VERSION ""

NS_ :

BS_:

BU_: CH DIPF DIPR ETH FC HVI HVS PARTY SDCV VEH VIRT

BO_ 1304 VCRIGHT_alertCleared: 2 VEH
 SG_ VCRIGHT_alertClearedID : 0|9@1+ (1,0) [0|324] ""  X

BO_ 1924 DBG_xcpPMSCommand: 8 VEH
 SG_ DBG_xcpPMSCommand : 7|64@0+ (1,0) [0|18446744073709551615] ""  pms

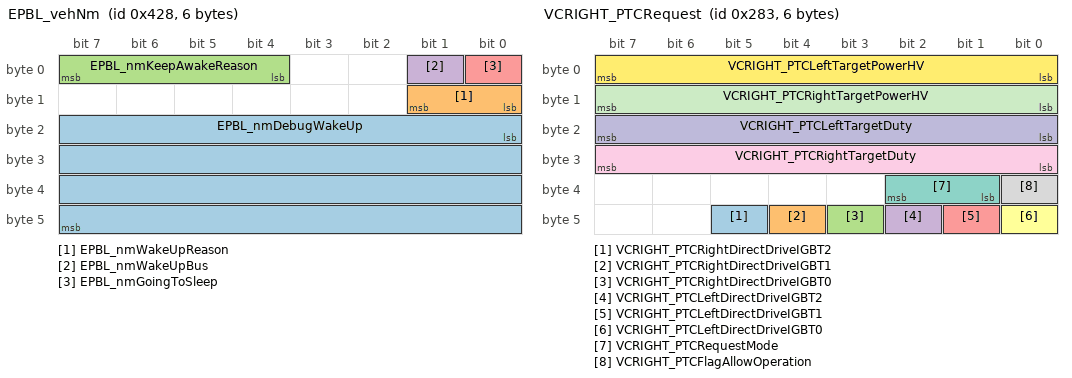
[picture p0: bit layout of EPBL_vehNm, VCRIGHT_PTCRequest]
BO_ 1064 EPBL_vehNm: 6 VEH
 SG_ EPBL_nmDebugWakeUp : 16|32@1+ (1,0) [0|4294967295] ""  gtw
 SG_ EPBL_nmWakeUpReason : 8|2@1+ (1,0) [0|3] ""  gtw
 SG_ EPBL_nmKeepAwakeReason : 4|4@1+ (1,0) [0|15] ""  gtw
 SG_ EPBL_nmWakeUpBus : 1|1@1+ (1,0) [0|1] ""  X
 SG_ EPBL_nmGoingToSleep : 0|1@1+ (1,0) [0|1] ""  X

BO_ 1579 UDS_ccRequest: 8 VEH
 SG_ UDS_ccRequestData : 7|64@0+ (1,0) [0|18446744073709551615] ""  bms

BO_ 627 UI_vehicleControl: 8 VEH
 SG_ UI_rearWindowLockout : 63|1@1+ (1,0) [0|1] ""  vcleft
 SG_ UI_driveStateRequest : 62|1@1+ (1,0) [0|1] ""  vcfront
 SG_ UI_honkHorn : 61|1@1+ (1,0) [0|1] ""  vcfront
 SG_ UI_domeLightSwitch : 59|2@1+ (1,0) [0|2] ""  vcleft
 SG_ UI_wiperRequest : 56|3@1+ (1,0) [0|6] ""  app
 SG_ UI_remoteClosureRequest : 54|2@1+ (1,0) [0|3] ""  vcsec
 SG_ UI_mirrorDipOnReverse : 53|1@1+ (1,0) [0|1] ""  vcleft
 SG_ UI_autoFoldMirrorsOn : 52|1@1+ (1,0) [0|1] ""  vcleft
 SG_ UI_rearRightSeatHeatReq : 50|2@1+ (1,0) [0|3] ""  vcright
 SG_ UI_rearCenterSeatHeatReq : 48|2@1+ (1,0) [0|3] ""  vcright
 SG_ UI_rearLeftSeatHeatReq : 46|2@1+ (1,0) [0|3] ""  vcright
 SG_ UI_frontRightSeatHeatReq : 44|2@1+ (1,0) [0|3] ""  vcright
 SG_ UI_frontLeftSeatHeatReq : 42|2@1+ (1,0) [0|3] ""  vcleft
 SG_ UI_autoHighBeamEnabled : 41|1@1+ (1,0) [0|1] ""  vcfront
 SG_ UI_ambientLightingEnabled : 40|1@1+ (1,0) [0|1] ""  vcfront
 SG_ UI_displayBrightnessLevel : 32|8@1+ (0.5,0) [0|127] "%"  vcfront
 SG_ UI_powerOff : 31|1@1+ (1,0) [0|1] ""  vcfront
 SG_ UI_seeYouHomeLightingOn : 30|1@1+ (1,0) [0|1] ""  vcfront
 SG_ UI_remoteStartRequest : 27|3@1+ (1,0) [0|4] ""  vcsec
 SG_ UI_mirrorHeatRequest : 26|1@1+ (1,0) [0|1] ""  vcleft
 SG_ UI_mirrorFoldRequest : 24|2@1+ (1,0) [0|3] ""  vcleft
 SG_ UI_rearFogSwitch : 23|1@1+ (1,0) [0|1] ""  vcleft
 SG_ UI_stop12vSupport : 22|1@1+ (1,0) [0|1] ""  vcfront
 SG_ UI_intrusionSensorOn : 21|1@1+ (1,0) [0|1] ""  vcfront
 SG_ UI_alarmEnabled : 20|1@1+ (1,0) [0|1] ""  vcsec
 SG_ UI_lockRequest : 17|3@1+ (1,0) [0|7] ""  vcsec
 SG_ UI_childDoorLockOn : 16|1@1+ (1,0) [0|1] ""  vcleft
 SG_ UI_globalUnlockOn : 15|1@1+ (1,0) [0|1] ""  X
 SG_ UI_unlockOnPark : 14|1@1+ (1,0) [0|1] ""  vcsec
 SG_ UI_walkAwayLock : 13|1@1+ (1,0) [0|1] ""  vcsec
 SG_ UI_walkUpUnlock : 12|1@1+ (1,0) [0|1] ""  vcsec
 SG_ UI_steeringButtonMode : 9|3@1+ (1,0) [0|5] ""  vcfront
 SG_ UI_steeringBacklightEnabled : 8|1@1+ (1,0) [0|1] ""  vcleft
 SG_ UI_wiperMode : 6|2@1+ (1,0) [0|3] ""  vcfront
 SG_ UI_frunkRequest : 5|1@1+ (1,0) [0|1] ""  vcfront
 SG_ UI_summonActive : 4|1@1+ (1,0) [0|1] ""  vcleft
 SG_ UI_frontFogSwitch : 3|1@1+ (1,0) [0|1] ""  vcfront
 SG_ UI_accessoryPowerRequest : 0|1@1+ (1,0) [0|1] ""  vcfront

BO_ 1960 EPBR_debugOutput: 8 VEH
 SG_ EPBR_filteredCurrentCalSP m1 : 52|12@1+ (0.01,0) [0|40.95] "A"  X
 SG_ EPBR_pid_error m1 : 40|12@1+ (0.016997132,-37.55274262) [-37.55274|32.05051] "A"  X
 SG_ EPBR_currentVariance m0 : 40|14@1- (3.0517578125e-05,0) [-0.25|0.24997] "A"  X
 SG_ EPBR_atEndStop m0 : 37|1@1+ (1,0) [0|1] ""  X
 SG_ EPBR_learnedBrakeHWType m0 : 35|2@1+ (1,0) [0|2] ""  X
 SG_ EPBR_diBrakeActive m0 : 34|1@1+ (1,0) [0|1] ""  X
 SG_ EPBR_diStandStill m0 : 33|1@1+ (1,0) [0|1] ""  X
 SG_ EPBR_nFault m0 : 32|1@1+ (1,0) [0|1] ""  X
 SG_ EPBR_brakeDiscWipeAccumul m2 : 32|28@1+ (1,0) [0|268435455] ""  X
 SG_ EPBR_ramp m1 : 32|8@1+ (0.392157,0) [0|100.00004] "%"  X
 SG_ EPBR_lockoutCommandHVC m2 : 31|1@1+ (1,0) [0|1] ""  gtw
 SG_ EPBR_lockoutOutputHVC m2 : 30|1@1+ (1,0) [0|1] ""  gtw
 SG_ EPBR_caliperState m0 : 29|3@1+ (1,0) [0|5] ""  X
 SG_ EPBR_lockoutCmdContactor m2 : 29|1@1+ (1,0) [0|1] ""  gtw
 SG_ EPBR_lockoutOutContactor m2 : 28|1@1+ (1,0) [0|1] ""  gtw
 SG_ EPBR_pid_duty m1 : 22|10@1- (0.2,0) [-102.4|102.2] "%"  X
 SG_ EPBR_pvFilt m0 : 20|9@1+ (0.043549408784,0) [0|22.25375] "V"  X
 SG_ EPBR_filteredCurrentPeak m2 : 16|12@1+ (0.01,0) [0|40.95] "A"  gtw
 SG_ EPBR_pid_uI m1 : 12|10@1- (0.2,0) [-102.4|102.2] "A"  X
 SG_ EPBR_nvFilt m0 : 11|9@1+ (0.043549408784,0) [0|22.25375] "V"  X
 SG_ EPBR_currentOffset m2 : 2|12@1+ (0.016997132,-37.55274262) [-37.55274|32.05051] "A"  X
 SG_ EPBR_pid_uP m1 : 2|10@1- (0.2,0) [-102.4|102.2] "A"  X
 SG_ EPBR_12VFilt_SW m0 : 2|9@1+ (0.043549408784,0) [0|22.25375] "V"  X
 SG_ EPBR_debugOutput M : 0|2@1+ (1,0) [0|2] ""  X

BO_ 1310 FC_info: 8 VEH
 SG_ FC_partNumChar14 m26 : 56|1@1+ (1,0) [0|1] ""  gtw
 SG_ FC_partNumChar07 m25 : 56|1@1+ (1,0) [0|1] ""  gtw
 SG_ FC_partNumChar20 m27 : 48|1@1+ (1,0) [0|1] ""  gtw
 SG_ FC_infoComponentID m10 : 48|16@1+ (1,0) [0|65535] ""  gtw
 SG_ FC_infoSubUsageID m11 : 48|16@1+ (1,0) [0|65535] ""  gtw
 SG_ FC_partNumChar13 m26 : 48|1@1+ (1,0) [0|1] ""  gtw
 SG_ FC_partNumChar06 m25 : 48|1@1+ (1,0) [0|1] ""  gtw
 SG_ FC_infoHardwareRevision m19 : 40|8@1+ (1,0) [0|255] ""  gtw
 SG_ FC_partNumChar05 m25 : 40|1@1+ (1,0) [0|1] ""  gtw
 SG_ FC_partNumChar19 m27 : 40|1@1+ (1,0) [0|1] ""  gtw
 SG_ FC_partNumChar12 m26 : 40|1@1+ (1,0) [0|1] ""  gtw
 SG_ FC_infoVariantCRC m22 : 32|32@1+ (1,0) [0|4294967295] ""  gtw
 SG_ FC_partNumChar11 m26 : 32|1@1+ (1,0) [0|1] ""  gtw
 SG_ FC_infoBootCRC m15 : 32|32@1+ (1,0) [0|4294967295] ""  gtw
 SG_ FC_partNumChar04 m25 : 32|1@1+ (1,0) [0|1] ""  gtw
 SG_ FC_infoUsageID m11 : 32|16@1+ (1,0) [0|65535] ""  gtw
 SG_ FC_partNumChar18 m27 : 32|1@1+ (1,0) [0|1] ""  gtw
 SG_ FC_infoHardwareID m10 : 32|16@1+ (1,0) [0|65535] ""  gtw
 SG_ FC_infoMaturity m19 : 32|8@1+ (1,0) [0|255] ""  gtw
 SG_ FC_infoApplicationCRC m13 : 32|32@1+ (1,0) [0|4294967295] ""  gtw
 SG_ FC_partNumChar03 m25 : 24|1@1+ (1,0) [0|1] ""  gtw
 SG_ FC_partNumChar17 m27 : 24|1@1+ (1,0) [0|1] ""  gtw
 SG_ FC_partNumChar10 m26 : 24|1@1+ (1,0) [0|1] ""  gtw
 SG_ FC_infoCPLDVersionMinor m16 : 24|8@1+ (1,0) [0|255] ""  gtw
 SG_ FC_infoAssemblyID m11 : 24|8@1+ (1,0) [0|255] ""  gtw
 SG_ FC_infoBranchOrigin m19 : 24|8@1+ (1,0) [0|255] ""  gtw
 SG_ FC_partNumChar02 m25 : 16|1@1+ (1,0) [0|1] ""  gtw
 SG_ FC_infoMajorVersion m19 : 16|8@1+ (1,0) [0|255] ""  gtw
 SG_ FC_infoBuildConfigID m10 : 16|8@1+ (1,0) [0|255] ""  gtw
 SG_ FC_partNumChar09 m26 : 16|1@1+ (1,0) [0|1] ""  gtw
 SG_ FC_partNumChar16 m27 : 16|1@1+ (1,0) [0|1] ""  gtw
 SG_ FC_infoPcbaID m11 : 16|8@1+ (1,0) [0|255] ""  gtw
 SG_ FC_infoCPLDVersionMajor m16 : 16|8@1+ (1,0) [0|255] ""  gtw
 SG_ FC_partNumChar08 m26 : 8|1@1+ (1,0) [0|1] ""  gtw
 SG_ FC_infoBuildType m10 : 8|3@1+ (1,0) [0|4] ""  gtw
 SG_ FC_infoAppGitHashBytes m17 : 8|56@1+ (1,0) [0|72057594037927935] ""  gtw
 SG_ FC_infoBootGitHashBytes m18 : 8|56@1+ (1,0) [0|72057594037927935] ""  gtw
 SG_ FC_infoPlatformType m19 : 8|8@1+ (1,0) [0|255] ""  gtw
 SG_ FC_infoBootSvnRev m14 : 8|24@1+ (1,0) [0|16777215] ""  gtw
 SG_ FC_partNumChar01 m25 : 8|1@1+ (1,0) [0|1] ""  gtw
 SG_ FC_partNumChar15 m27 : 8|1@1+ (1,0) [0|1] ""  gtw
 SG_ FC_infoBootUdsProtoVersion m20 : 8|8@1+ (1,0) [0|255] ""  gtw
 SG_ FC_infoIndex M : 0|8@1+ (1,0) [0|255] ""  dbg

BO_ 1910 DBG_xcpDISCommand: 8 VEH
 SG_ DBG_xcpDISCommand : 7|64@0+ (1,0) [0|18446744073709551615] ""  dis

BO_ 643 VCRIGHT_PTCRequest: 6 VEH
 SG_ VCRIGHT_PTCRightDirectDriveIGBT2 : 45|1@1+ (1,0) [0|1] ""  ptc
 SG_ VCRIGHT_PTCRightDirectDriveIGBT1 : 44|1@1+ (1,0) [0|1] ""  ptc
 SG_ VCRIGHT_PTCRightDirectDriveIGBT0 : 43|1@1+ (1,0) [0|1] ""  ptc
 SG_ VCRIGHT_PTCLeftDirectDriveIGBT2 : 42|1@1+ (1,0) [0|1] ""  ptc
 SG_ VCRIGHT_PTCLeftDirectDriveIGBT1 : 41|1@1+ (1,0) [0|1] ""  ptc
 SG_ VCRIGHT_PTCLeftDirectDriveIGBT0 : 40|1@1+ (1,0) [0|1] ""  ptc
 SG_ VCRIGHT_PTCRequestMode : 33|2@1+ (1,0) [0|2] ""  ptc
 SG_ VCRIGHT_PTCFlagAllowOperation : 32|1@1+ (1,0) [0|1] ""  ptc
 SG_ VCRIGHT_PTCRightTargetDuty : 24|8@1+ (0.5,0) [0|100] "%"  ptc
 SG_ VCRIGHT_PTCLeftTargetDuty : 16|8@1+ (0.5,0) [0|100] "%"  ptc
 SG_ VCRIGHT_PTCRightTargetPowerHV : 8|8@1+ (20,0) [0|5000] "W"  ptc
 SG_ VCRIGHT_PTCLeftTargetPowerHV : 0|8@1+ (20,0) [0|5000] "W"  ptc

BO_ 1768 EPBR_statsOutput: 8 VEH
 SG_ EPBR_staticApplyCountsVeryCold m0 : 44|20@1+ (1,0) [0|1048575] ""  X
 SG_ EPBR_staticApplyCountsCold m0 : 24|20@1+ (1,0) [0|1048575] ""  X
 SG_ EPBR_dynamicApplyCounts m1 : 8|32@1+ (1,0) [0|4294967295] ""  X
 SG_ EPBR_staticApplyCounts m0 : 2|20@1+ (1,0) [0|1048575] ""  X
 SG_ EPBR_statsOutput M : 0|2@1+ (1,0) [0|2] ""  X

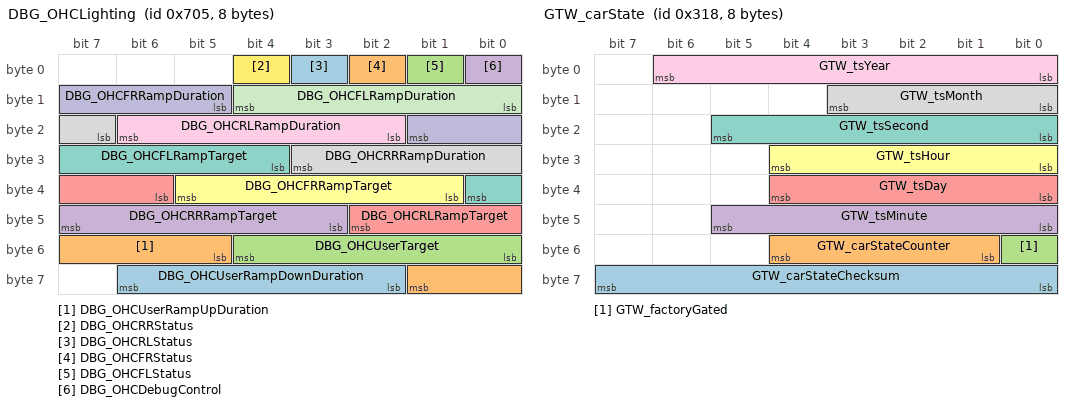
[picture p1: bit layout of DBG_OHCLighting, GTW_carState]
BO_ 1797 DBG_OHCLighting: 8 VEH
 SG_ DBG_OHCUserRampDownDuration : 58|5@1+ (0.25,0.25) [0.25|8] "sec"  vcleft
 SG_ DBG_OHCUserRampUpDuration : 53|5@1+ (0.25,0.25) [0.25|8] "sec"  vcleft
 SG_ DBG_OHCUserTarget : 48|5@1+ (5,0) [0|155] "%"  vcleft
 SG_ DBG_OHCRRRampTarget : 43|5@1+ (5,0) [0|155] "%"  vcleft
 SG_ DBG_OHCRLRampTarget : 38|5@1+ (5,0) [0|155] "%"  vcleft
 SG_ DBG_OHCFRRampTarget : 33|5@1+ (5,0) [0|155] "%"  vcleft
 SG_ DBG_OHCFLRampTarget : 28|5@1+ (5,0) [0|155] "%"  vcleft
 SG_ DBG_OHCRRRampDuration : 23|5@1+ (0.25,0.25) [0.25|8] "sec"  vcleft
 SG_ DBG_OHCRLRampDuration : 18|5@1+ (0.25,0.25) [0.25|8] "sec"  vcleft
 SG_ DBG_OHCFRRampDuration : 13|5@1+ (0.25,0.25) [0.25|8] "sec"  vcleft
 SG_ DBG_OHCFLRampDuration : 8|5@1+ (0.25,0.25) [0.25|8] "sec"  vcleft
 SG_ DBG_OHCRRStatus : 4|1@1+ (1,0) [0|1] ""  vcleft
 SG_ DBG_OHCRLStatus : 3|1@1+ (1,0) [0|1] ""  vcleft
 SG_ DBG_OHCFRStatus : 2|1@1+ (1,0) [0|1] ""  vcleft
 SG_ DBG_OHCFLStatus : 1|1@1+ (1,0) [0|1] ""  vcleft
 SG_ DBG_OHCDebugControl : 0|1@1+ (1,0) [0|1] ""  vcleft

BO_ 963 VCRIGHT_switchStatus: 7 VEH
 SG_ VCRIGHT_trunkExtReleasePressed : 48|1@1+ (1,0) [0|1] ""  gtw
 SG_ VCRIGHT_rearRightBuckleSwitch : 46|2@1+ (1,0) [0|3] ""  gtw
 SG_ VCRIGHT_rearCenterBuckleSwitch : 44|2@1+ (1,0) [0|3] ""  gtw
 SG_ VCRIGHT_frontOccupancySwitch : 42|2@1+ (1,0) [0|3] ""  gtw
 SG_ VCRIGHT_frontBuckleSwitch : 40|2@1+ (1,0) [0|3] ""  gtw
 SG_ VCRIGHT_btnWindowSwPackAutoDwnLR : 39|1@1+ (1,0) [0|1] ""  gtw
 SG_ VCRIGHT_btnWindowSwPackDownLR : 38|1@1+ (1,0) [0|1] ""  gtw
 SG_ VCRIGHT_btnWindowSwPackAutoUpLR : 37|1@1+ (1,0) [0|1] ""  gtw
 SG_ VCRIGHT_btnWindowSwPackUpLR : 36|1@1+ (1,0) [0|1] ""  gtw
 SG_ VCRIGHT_btnWindowSwPackAutoDwnLF : 35|1@1+ (1,0) [0|1] ""  gtw
 SG_ VCRIGHT_btnWindowSwPackDownLF : 34|1@1+ (1,0) [0|1] ""  gtw
 SG_ VCRIGHT_btnWindowSwPackAutoUpLF : 33|1@1+ (1,0) [0|1] ""  gtw
 SG_ VCRIGHT_btnWindowSwPackUpLF : 32|1@1+ (1,0) [0|1] ""  gtw
 SG_ VCRIGHT_btnWindowAutoDownRR : 31|1@1+ (1,0) [0|1] ""  gtw
 SG_ VCRIGHT_btnWindowDownRR : 30|1@1+ (1,0) [0|1] ""  gtw
 SG_ VCRIGHT_btnWindowAutoUpRR : 29|1@1+ (1,0) [0|1] ""  gtw
 SG_ VCRIGHT_btnWindowUpRR : 28|1@1+ (1,0) [0|1] ""  gtw
 SG_ VCRIGHT_btnWindowAutoDownRF : 27|1@1+ (1,0) [0|1] ""  gtw
 SG_ VCRIGHT_btnWindowDownRF : 26|1@1+ (1,0) [0|1] ""  gtw
 SG_ VCRIGHT_btnWindowAutoUpRF : 25|1@1+ (1,0) [0|1] ""  gtw
 SG_ VCRIGHT_btnWindowUpRF : 24|1@1+ (1,0) [0|1] ""  gtw
 SG_ VCRIGHT_frontSeatLumbarOut : 22|2@1+ (1,0) [0|3] ""  gtw
 SG_ VCRIGHT_frontSeatLumbarIn : 20|2@1+ (1,0) [0|3] ""  gtw
 SG_ VCRIGHT_frontSeatLumbarUp : 18|2@1+ (1,0) [0|3] ""  gtw
 SG_ VCRIGHT_frontSeatLumbarDown : 16|2@1+ (1,0) [0|3] ""  gtw
 SG_ VCRIGHT_frontSeatBackrestForward : 14|2@1+ (1,0) [0|3] ""  gtw
 SG_ VCRIGHT_frontSeatBackrestBack : 12|2@1+ (1,0) [0|3] ""  gtw
 SG_ VCRIGHT_frontSeatLiftUp : 10|2@1+ (1,0) [0|3] ""  gtw
 SG_ VCRIGHT_frontSeatLiftDown : 8|2@1+ (1,0) [0|3] ""  gtw
 SG_ VCRIGHT_frontSeatTiltUp : 6|2@1+ (1,0) [0|3] ""  gtw
 SG_ VCRIGHT_frontSeatTiltDown : 4|2@1+ (1,0) [0|3] ""  gtw
 SG_ VCRIGHT_frontSeatTrackForward : 2|2@1+ (1,0) [0|3] ""  gtw
 SG_ VCRIGHT_frontSeatTrackBack : 0|2@1+ (1,0) [0|3] ""  gtw

BO_ 1546 UDS_vcsecRequest: 8 VEH
 SG_ UDS_vcsecRequestData : 7|64@0+ (1,0) [0|18446744073709551615] ""  vcsec

BO_ 792 GTW_carState: 8 VEH
 SG_ GTW_carStateChecksum : 56|8@1+ (1,0) [0|255] ""  X
 SG_ GTW_carStateCounter : 49|4@1+ (1,0) [0|15] ""  X
 SG_ GTW_factoryGated : 48|1@1+ (1,0) [0|1] ""  epbl
 SG_ GTW_tsMinute : 40|6@1+ (1,0) [0|59] "minutes"  X
 SG_ GTW_tsDay : 32|5@1+ (1,0) [0|31] "days"  vcfront
 SG_ GTW_tsHour : 24|5@1+ (1,0) [0|23] "hours"  X
 SG_ GTW_tsSecond : 16|6@1+ (1,0) [0|59] "seconds"  X
 SG_ GTW_tsMonth : 8|4@1+ (1,0) [1|12] "months"  X
 SG_ GTW_tsYear : 0|7@1+ (1,2000) [2000|2127] "Year"  X

BO_ 771 VCRIGHT_info: 8 VEH
 SG_ VCRIGHT_infoComponentId m10 : 48|16@1+ (1,0) [0|65535] ""  gtw
 SG_ VCRIGHT_infoSubUsageId m11 : 40|16@1+ (1,0) [0|65535] ""  gtw
 SG_ VCRIGHT_infoHardwareId m10 : 32|16@1+ (1,0) [0|65535] ""  gtw
 SG_ VCRIGHT_infoBootCrc m20 : 24|32@1+ (1,0) [0|4294967295] ""  gtw
 SG_ VCRIGHT_infoUsageId m11 : 24|16@1+ (1,0) [0|65535] ""  gtw
 SG_ VCRIGHT_infoBuildConfigId m10 : 16|16@1+ (1,0) [0|65535] ""  gtw
 SG_ VCRIGHT_infoAssemblyId m11 : 16|8@1+ (1,0) [0|255] ""  gtw
 SG_ VCRIGHT_infoAppGitHash m17 : 8|56@1+ (1,0) [0|72057594037927935] ""  gtw
 SG_ VCRIGHT_infoBuildType m10 : 8|3@1+ (1,0) [0|4] ""  gtw
 SG_ VCRIGHT_infoBootGitHash m18 : 8|56@1+ (1,0) [0|72057594037927935] ""  gtw
 SG_ VCRIGHT_infoAppCrc m13 : 8|32@1+ (1,0) [0|4294967295] ""  gtw
 SG_ VCRIGHT_infoPcbaId m11 : 8|8@1+ (1,0) [0|255] ""  gtw
 SG_ VCRIGHT_infoPlatformType m19 : 8|8@1+ (1,0) [0|255] ""  gtw
 SG_ VCRIGHT_infoBootUdsProtoVersion m20 : 8|16@1+ (1,0) [0|65535] ""  gtw
 SG_ VCRIGHT_infoIndex M : 0|8@1+ (1,0) [0|255] ""  gtw

BO_ 1285 UMC_smartAdapterInfo: 8 VEH
 SG_ SA_partNumChar14 m26 : 56|8@1+ (1,0) [0|255] ""  gtw
 SG_ SA_serialNumChar14 m30 : 56|8@1+ (1,0) [0|255] ""  gtw
 SG_ SA_partNumChar07 m25 : 56|8@1+ (1,0) [0|255] ""  gtw
 SG_ SA_serialNumChar07 m29 : 56|8@1+ (1,0) [0|255] ""  gtw
 SG_ SA_SubUsageID m11 : 48|16@1+ (1,0) [0|65535] ""  gtw
 SG_ SA_partNumChar20 m27 : 48|8@1+ (1,0) [0|255] ""  gtw
 SG_ SA_partNumChar06 m25 : 48|8@1+ (1,0) [0|255] ""  gtw
 SG_ SA_serialNumChar13 m30 : 48|8@1+ (1,0) [0|255] ""  gtw
 SG_ SA_partNumChar13 m26 : 48|8@1+ (1,0) [0|255] ""  gtw
 SG_ SA_serialNumChar06 m29 : 48|8@1+ (1,0) [0|255] ""  gtw
 SG_ SA_partNumChar12 m26 : 40|8@1+ (1,0) [0|255] ""  gtw
 SG_ SA_partNumChar19 m27 : 40|8@1+ (1,0) [0|255] ""  gtw
 SG_ SA_partNumChar05 m25 : 40|8@1+ (1,0) [0|255] ""  gtw
 SG_ SA_serialNumChar05 m29 : 40|8@1+ (1,0) [0|255] ""  gtw
 SG_ SA_serialNumChar12 m30 : 40|8@1+ (1,0) [0|255] ""  gtw
 SG_ SA_serialNumChar11 m30 : 32|8@1+ (1,0) [0|255] ""  gtw
 SG_ SA_partNumChar18 m27 : 32|8@1+ (1,0) [0|255] ""  gtw
 SG_ SA_serialNumChar04 m29 : 32|8@1+ (1,0) [0|255] ""  gtw
 SG_ SA_partNumChar04 m25 : 32|8@1+ (1,0) [0|255] ""  gtw
 SG_ SA_UsageID m11 : 32|16@1+ (1,0) [0|65535] ""  gtw
 SG_ SA_partNumChar11 m26 : 32|8@1+ (1,0) [0|255] ""  gtw
 SG_ SA_AssemblyID m11 : 24|8@1+ (1,0) [0|255] ""  gtw
 SG_ SA_serialNumChar03 m29 : 24|8@1+ (1,0) [0|255] ""  gtw
 SG_ SA_serialNumChar10 m30 : 24|8@1+ (1,0) [0|255] ""  gtw
 SG_ SA_partNumChar10 m26 : 24|8@1+ (1,0) [0|255] ""  gtw
 SG_ SA_partNumChar17 m27 : 24|8@1+ (1,0) [0|255] ""  gtw
 SG_ SA_partNumChar03 m25 : 24|8@1+ (1,0) [0|255] ""  gtw
 SG_ SA_serialNumChar02 m29 : 16|8@1+ (1,0) [0|255] ""  gtw
 SG_ SA_partNumChar02 m25 : 16|8@1+ (1,0) [0|255] ""  gtw
 SG_ SA_serialNumChar09 m30 : 16|8@1+ (1,0) [0|255] ""  gtw
 SG_ SA_genealogyCrc m0 : 16|32@1+ (1,0) [0|4294967295] ""  gtw
 SG_ SA_partNumChar16 m27 : 16|8@1+ (1,0) [0|255] ""  gtw
 SG_ SA_partNumChar09 m26 : 16|8@1+ (1,0) [0|255] ""  gtw
 SG_ SA_serialNumChar08 m30 : 8|8@1+ (1,0) [0|255] ""  gtw
 SG_ SA_serialNumInt m32 : 8|40@1+ (1,0) [0|1099511627775] ""  X
 SG_ SA_partNumChar15 m27 : 8|8@1+ (1,0) [0|255] ""  gtw
 SG_ SA_partNumChar01 m25 : 8|8@1+ (1,0) [0|255] ""  gtw
 SG_ SA_genealogyVersion m0 : 8|8@1+ (1,0) [0|255] ""  gtw
 SG_ SA_partNumInt m31 : 8|32@1+ (1,0) [0|4294967295] ""  X
 SG_ SA_serialNumChar01 m29 : 8|8@1+ (1,0) [0|255] ""  gtw
 SG_ SA_partNumChar08 m26 : 8|8@1+ (1,0) [0|255] ""  gtw
 SG_ SA_infoIndex M : 0|8@1+ (1,0) [0|32] ""  dbg

BO_ 858 DI_alertMatrix3: 8 VEH
 SG_ DI_a192_invalidOdometer : 63|1@1+ (1,0) [0|1] ""  gtw
 SG_ DI_a191_brakeShiftReq : 62|1@1+ (1,0) [0|1] ""  gtw
 SG_ DI_a189_garageShiftWithPedal : 60|1@1+ (1,0) [0|1] ""  gtw
 SG_ DI_a187_pedalMisapplication : 58|1@1+ (1,0) [0|1] ""  gtw
 SG_ DI_a186_brakeStand : 57|1@1+ (1,0) [0|1] ""  gtw
 SG_ DI_a185_autoparkAborted : 56|1@1+ (1,0) [0|1] ""  gtw
 SG_ DI_a184_autoparkCanceled : 55|1@1+ (1,0) [0|1] ""  gtw
 SG_ DI_a183_holdReleaseRqrd : 54|1@1+ (1,0) [0|1] ""  gtw
 SG_ DI_a182_frontMotorMode : 53|1@1+ (1,0) [0|1] ""  gtw
 SG_ DI_a181_rearMotorMode : 52|1@1+ (1,0) [0|1] ""  gtw
 SG_ DI_a180_crsSeatbeltUnbuckled : 51|1@1+ (1,0) [0|1] ""  gtw
 SG_ DI_a177_tireFitmentChanged : 48|1@1+ (1,0) [0|1] ""  gtw
 SG_ DI_a176_EBRreleased : 47|1@1+ (1,0) [0|1] ""  gtw
 SG_ DI_a175_crsNotAvailable : 46|1@1+ (1,0) [0|1] ""  gtw
 SG_ DI_a174_notOkToStartDrive : 45|1@1+ (1,0) [0|1] ""  gtw
 SG_ DI_a173_bothPedalsPressed : 44|1@1+ (1,0) [0|1] ""  gtw
 SG_ DI_a172_accelPressedInNP : 43|1@1+ (1,0) [0|1] ""  gtw
 SG_ DI_a171_driveRailNotRequested : 42|1@1+ (1,0) [0|1] ""  gtw
 SG_ DI_a170_pedalFoul : 41|1@1+ (1,0) [0|1] ""  gtw
 SG_ DI_a169_regenOffOverride : 40|1@1+ (1,0) [0|1] ""  gtw
 SG_ DI_a168_proximityDriveDenial : 39|1@1+ (1,0) [0|1] ""  gtw
 SG_ DI_a167_keyNotAuthenticated : 38|1@1+ (1,0) [0|1] ""  gtw
 SG_ DI_a166_driverLeft : 37|1@1+ (1,0) [0|1] ""  gtw
 SG_ DI_a165_cruiseCancelled : 36|1@1+ (1,0) [0|1] ""  gtw
 SG_ DI_a164_brakeOverride : 35|1@1+ (1,0) [0|1] ""  gtw
 SG_ DI_a163_unparkReq : 34|1@1+ (1,0) [0|1] ""  gtw
 SG_ DI_a162_shiftDenied : 33|1@1+ (1,0) [0|1] ""  gtw
 SG_ DI_a161_epas3pMIA : 32|1@1+ (1,0) [0|1] ""  gtw
 SG_ DI_a160_busVoltageAnomaly : 31|1@1+ (1,0) [0|1] ""  gtw
 SG_ DI_a159_cruiseSelfCheck : 30|1@1+ (1,0) [0|1] ""  gtw
 SG_ DI_a158_ibstMIA : 29|1@1+ (1,0) [0|1] ""  gtw
 SG_ DI_a157_rcmMIA : 28|1@1+ (1,0) [0|1] ""  gtw
 SG_ DI_a156_currentObserver : 27|1@1+ (1,0) [0|1] ""  gtw
 SG_ DI_a155_vcfrontMIA : 26|1@1+ (1,0) [0|1] ""  gtw
 SG_ DI_a154_resolver : 25|1@1+ (1,0) [0|1] ""  gtw
 SG_ DI_a153_oilPump : 24|1@1+ (1,0) [0|1] ""  gtw
 SG_ DI_a152_linError : 23|1@1+ (1,0) [0|1] ""  gtw
 SG_ DI_a151_shockTorqueLimiter : 22|1@1+ (1,0) [0|1] ""  gtw
 SG_ DI_a150_busVD : 21|1@1+ (1,0) [0|1] ""  gtw
 SG_ DI_a149_oilPumpFailure : 20|1@1+ (1,0) [0|1] ""  gtw
 SG_ DI_a148_overtorqueUsed : 19|1@1+ (1,0) [0|1] ""  gtw
 SG_ DI_a147_highTorqueWearLimit : 18|1@1+ (1,0) [0|1] ""  gtw
 SG_ DI_a146_pbrkPanicEpbFault : 17|1@1+ (1,0) [0|1] ""  gtw
 SG_ DI_a145_pbrkPanicSkid : 16|1@1+ (1,0) [0|1] ""  gtw
 SG_ DI_a144_configMismatch : 15|1@1+ (1,0) [0|1] ""  gtw
 SG_ DI_a143_mcuLimitActive : 14|1@1+ (1,0) [0|1] ""  gtw
 SG_ DI_a142_highLashAngle : 13|1@1+ (1,0) [0|1] ""  gtw
 SG_ DI_a141_dasMIA : 12|1@1+ (1,0) [0|1] ""  gtw
 SG_ DI_a139_rearUnitDisabled : 10|1@1+ (1,0) [0|1] ""  gtw
 SG_ DI_a138_frontUnitDisabled : 9|1@1+ (1,0) [0|1] ""  gtw
 SG_ DI_a137_noCapableDriveUnits : 8|1@1+ (1,0) [0|1] ""  gtw
 SG_ DI_a136_spiError : 7|1@1+ (1,0) [0|1] ""  gtw
 SG_ DI_a135_vehicleHoldFault : 6|1@1+ (1,0) [0|1] ""  gtw
 SG_ DI_a134_wheelSpeedIrrational : 5|1@1+ (1,0) [0|1] ""  gtw
 SG_ DI_a133_capacitorOT : 4|1@1+ (1,0) [0|1] ""  gtw
 SG_ DI_a131_highSpeedWearLimit : 2|1@1+ (1,0) [0|1] ""  gtw
 SG_ DI_a130_aebFault : 1|1@1+ (1,0) [0|1] ""  gtw
 SG_ DI_a129_epbNotApplied : 0|1@1+ (1,0) [0|1] ""  gtw

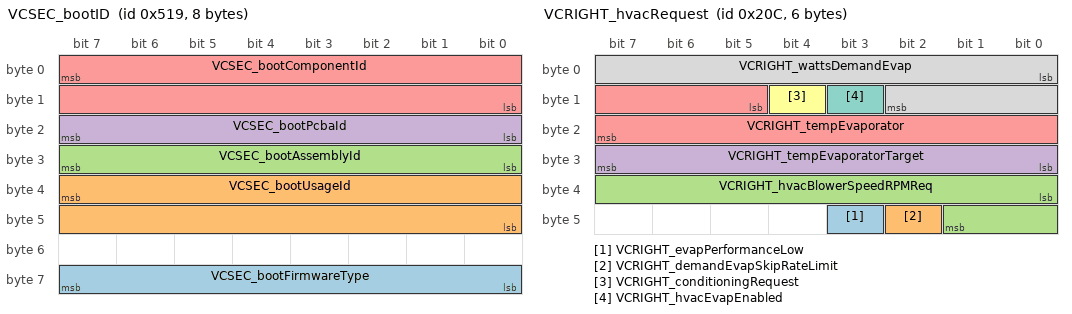
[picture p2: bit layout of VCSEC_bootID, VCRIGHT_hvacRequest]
BO_ 1305 VCSEC_bootID: 8 VEH
 SG_ VCSEC_bootFirmwareType : 63|8@0+ (1,0) [0|255] ""  X
 SG_ VCSEC_bootUsageId : 39|16@0+ (1,0) [0|65535] ""  X
 SG_ VCSEC_bootAssemblyId : 31|8@0+ (1,0) [0|255] ""  X
 SG_ VCSEC_bootPcbaId : 23|8@0+ (1,0) [0|255] ""  X
 SG_ VCSEC_bootComponentId : 7|16@0+ (1,0) [0|65535] ""  X

BO_ 524 VCRIGHT_hvacRequest: 6 VEH
 SG_ VCRIGHT_evapPerformanceLow : 43|1@1+ (1,0) [0|1] ""  gtw
 SG_ VCRIGHT_demandEvapSkipRateLimit : 42|1@1+ (1,0) [0|1] ""  vcfront
 SG_ VCRIGHT_hvacBlowerSpeedRPMReq : 32|10@1+ (5,0) [0|5115] "RPM"  gtw
 SG_ VCRIGHT_tempEvaporatorTarget : 24|8@1+ (0.2,0) [0|50] "degC"  gtw
 SG_ VCRIGHT_tempEvaporator : 13|11@1+ (0.1,-40) [-40|105] "degC"  gtw
 SG_ VCRIGHT_conditioningRequest : 12|1@1+ (1,0) [0|1] ""  vcfront
 SG_ VCRIGHT_hvacEvapEnabled : 11|1@1+ (1,0) [0|1] ""  gtw
 SG_ VCRIGHT_wattsDemandEvap : 0|11@1+ (5,0) [0|10000] "W"  gtw

BO_ 1748 PMS_info: 8 VEH
 SG_ PMS_componentId m10 : 48|16@1+ (1,0) [0|65535] ""  gtw
 SG_ PMS_subUsageId m11 : 48|16@1+ (1,0) [0|65535] ""  gtw
 SG_ PMS_bootloaderSvnUrlHash m14 : 32|32@1+ (1,0) [0|4294967295] ""  gtw
 SG_ PMS_bootloaderCrc m20 : 32|32@1+ (1,0) [0|4294967295] ""  gtw
 SG_ PMS_applicationCrc m13 : 32|32@1+ (1,0) [0|4294967295] ""  gtw
 SG_ PMS_usageId m11 : 32|16@1+ (1,0) [0|65535] ""  gtw
 SG_ PMS_hardwareId m10 : 32|8@1+ (1,0) [0|252] ""  gtw
 SG_ PMS_diNodeApplicationCrc m21 : 32|32@1+ (1,0) [0|4294967295] ""  gtw
 SG_ PMS_assemblyId m11 : 24|8@1+ (1,0) [0|255] ""  gtw
 SG_ PMS_buildConfigurationId m10 : 16|16@1+ (1,0) [0|65535] ""  gtw
 SG_ PMS_diNodeBuildConfigurationId m21 : 16|16@1+ (1,0) [0|65535] ""  X
 SG_ PMS_pcbaId m11 : 16|8@1+ (1,0) [0|255] ""  gtw
 SG_ PMS_appGitHash m17 : 8|56@1+ (1,0) [0|72057594037927935] ""  gtw
 SG_ PMS_diNodeBuildType m21 : 8|8@1+ (1,0) [0|4] ""  gtw
 SG_ PMS_bootloaderSvnRevision m14 : 8|24@1+ (1,0) [0|16777215] ""  gtw
 SG_ PMS_platformTyp m19 : 8|8@1+ (1,0) [0|255] ""  gtw
 SG_ PMS_bootGitHash m18 : 8|56@1+ (1,0) [0|72057594037927935] ""  gtw
 SG_ PMS_udsProtocolVersion m20 : 8|8@1+ (1,0) [0|255] ""  gtw
 SG_ PMS_buildType m10 : 8|8@1+ (1,0) [0|4] ""  gtw
 SG_ PMS_infoIndex M : 0|8@1+ (1,0) [0|255] ""  gtw

BO_ 929 VCFRONT_vehicleStatus: 8 VEH
 SG_ VCFRONT_vehicleStatusChecksum : 56|8@1+ (1,0) [0|255] ""  X
 SG_ VCFRONT_vehicleStatusCounter : 52|4@1+ (1,0) [0|15] ""  X
 SG_ VCFRONT_pcsEFuseVoltage : 42|10@1+ (0.1,0) [0|102.2] "V"  bms
 SG_ VCFRONT_2RowRightUnbuckled : 40|2@1+ (1,0) [0|2] ""  gtw
 SG_ VCFRONT_2RowCenterUnbuckled : 38|2@1+ (1,0) [0|2] ""  gtw
 SG_ VCFRONT_2RowLeftUnbuckled : 36|2@1+ (1,0) [0|2] ""  gtw
 SG_ VCFRONT_passengerUnbuckled : 34|2@1+ (1,0) [0|2] ""  gtw
 SG_ VCFRONT_driverUnbuckled : 32|2@1+ (1,0) [0|2] ""  gtw
 SG_ VCFRONT_driverDoorStatus : 31|1@1+ (1,0) [0|1] ""  di
 SG_ VCFRONT_driverBuckleStatus : 30|1@1+ (1,0) [0|1] ""  di
 SG_ VCFRONT_ota12VSupportRequest : 29|1@1+ (1,0) [0|1] ""  bms
 SG_ VCFRONT_driverIsLeaving : 28|1@1+ (1,0) [0|1] ""  di
 SG_ VCFRONT_batterySupportRequest : 27|1@1+ (1,0) [0|1] ""  gtw
 SG_ VCFRONT_pcs12vVoltageTarget : 16|11@1+ (0.01,0) [0|16] "V"  bms
 SG_ VCFRONT_12vStatusForDrive : 14|2@1+ (1,0) [0|2] ""  di
 SG_ VCFRONT_driverIsLeavingAnySpeed : 13|1@1+ (1,0) [0|1] ""  epbl
 SG_ VCFRONT_diPowerOnState : 10|3@1+ (1,0) [0|4] ""  gtw
 SG_ VCFRONT_LVLoadRequest : 9|1@1+ (1,0) [0|1] ""  gtw
 SG_ VCFRONT_is12VBatterySupported : 5|1@1+ (1,0) [0|1] ""  gtw
 SG_ VCFRONT_APGlassHeaterState : 2|3@1+ (1,0) [0|4] ""  aps
 SG_ VCFRONT_preconditionRequest : 1|1@1+ (1,0) [0|1] ""  bms
 SG_ VCFRONT_bmsHvChargeEnable : 0|1@1+ (1,0) [0|1] ""  bms

BO_ 1331 EPBL_bootID: 8 VEH
 SG_ EPBL_bootIdData : 0|64@1+ (1,0) [0|18446744073709551615] ""  gtwu

BO_ 1000 EPBR_alertMatrix: 8 VEH
 SG_ EPBR_a120_DI_DRIVE_MIA m1 : 63|1@1+ (1,0) [0|1] ""  gtw
 SG_ EPBR_a180_dynamicActive m2 : 63|1@1+ (1,0) [0|1] ""  gtw
 SG_ EPBR_a300_leftRightConfusion m4 : 63|1@1+ (1,0) [0|1] ""  gtw
 SG_ EPBR_a060_engineeringBuild m0 : 63|1@1+ (1,0) [0|1] ""  gtw
 SG_ EPBR_a119_SCCM_MIA m1 : 62|1@1+ (1,0) [0|1] ""  gtw
 SG_ EPBR_a059_inputResistanceHigh m0 : 62|1@1+ (1,0) [0|1] ""  gtw
 SG_ EPBR_a179_epbProblem m2 : 62|1@1+ (1,0) [0|1] ""  gtw
 SG_ EPBR_a178_caliperStateUnknown m2 : 61|1@1+ (1,0) [0|1] ""  gtw
 SG_ EPBR_a118_VCFRONT_MIA m1 : 61|1@1+ (1,0) [0|1] ""  gtw
 SG_ EPBR_a117_VCLEFT_MIA m1 : 60|1@1+ (1,0) [0|1] ""  gtw
 SG_ EPBR_a177_csmApplyRetry m2 : 60|1@1+ (1,0) [0|1] ""  gtw
 SG_ EPBR_a176_csmApplyFailed m2 : 59|1@1+ (1,0) [0|1] ""  gtw
 SG_ EPBR_a116_VCRIGHT_MIA m1 : 59|1@1+ (1,0) [0|1] ""  gtw
 SG_ EPBR_a175_csmReleaseRetry m2 : 58|1@1+ (1,0) [0|1] ""  gtw
 SG_ EPBR_a115_VCSEC_MIA m1 : 58|1@1+ (1,0) [0|1] ""  gtw
 SG_ EPBR_a174_csmReleaseFailed m2 : 57|1@1+ (1,0) [0|1] ""  gtw
 SG_ EPBR_a114_ESP_MIA m1 : 57|1@1+ (1,0) [0|1] ""  gtw
 SG_ EPBR_a113_UI_MIA m1 : 56|1@1+ (1,0) [0|1] ""  gtw
 SG_ EPBR_a173_hiCurrentMissing m2 : 56|1@1+ (1,0) [0|1] ""  gtw
 SG_ EPBR_a172_SPI_MIA m2 : 55|1@1+ (1,0) [0|1] ""  gtw
 SG_ EPBR_a112_EPBL_MIA m1 : 55|1@1+ (1,0) [0|1] ""  gtw
 SG_ EPBR_a171_12vUv m2 : 54|1@1+ (1,0) [0|1] ""  gtw
 SG_ EPBR_a111_EPBR_MIA m1 : 54|1@1+ (1,0) [0|1] ""  gtw
 SG_ EPBR_a110_GTW_MIA m1 : 53|1@1+ (1,0) [0|1] ""  gtw
 SG_ EPBR_a170_12vOv m2 : 53|1@1+ (1,0) [0|1] ""  gtw
 SG_ EPBR_a109_RCM_MIA m1 : 52|1@1+ (1,0) [0|1] ""  gtw
 SG_ EPBR_a108_DIS_MIA m1 : 51|1@1+ (1,0) [0|1] ""  gtw
 SG_ EPBR_a107_BMS_MIA m1 : 50|1@1+ (1,0) [0|1] ""  gtw
 SG_ EPBR_a106_PCS_MIA m1 : 49|1@1+ (1,0) [0|1] ""  gtw
 SG_ EPBR_a046_Task1000msError m0 : 49|1@1+ (1,0) [0|1] ""  gtw
 SG_ EPBR_a105_TAS_MIA m1 : 48|1@1+ (1,0) [0|1] ""  gtw
 SG_ EPBR_a045_Task100msError m0 : 48|1@1+ (1,0) [0|1] ""  gtw
 SG_ EPBR_a104_DAS_MIA m1 : 47|1@1+ (1,0) [0|1] ""  gtw
 SG_ EPBR_a044_Task10msError m0 : 47|1@1+ (1,0) [0|1] ""  gtw
 SG_ EPBR_a043_Task1msError m0 : 46|1@1+ (1,0) [0|1] ""  gtw
 SG_ EPBR_a103_CP_MIA m1 : 46|1@1+ (1,0) [0|1] ""  gtw
 SG_ EPBR_a102_PTC_MIA m1 : 45|1@1+ (1,0) [0|1] ""  gtw
 SG_ EPBR_a042_HighStackUsage m0 : 45|1@1+ (1,0) [0|1] ""  gtw
 SG_ EPBR_a101_PM_MIA m1 : 44|1@1+ (1,0) [0|1] ""  gtw
 SG_ EPBR_a041_HighCPULoad m0 : 44|1@1+ (1,0) [0|1] ""  gtw
 SG_ EPBR_a100_CANbus_MIA m1 : 43|1@1+ (1,0) [0|1] ""  gtw
 SG_ EPBR_a099_PARK_MIA m1 : 42|1@1+ (1,0) [0|1] ""  gtw
 SG_ EPBR_a098_DI_THERMAL_MIA m1 : 41|1@1+ (1,0) [0|1] ""  gtw
 SG_ EPBR_a097_CMP_MIA m1 : 40|1@1+ (1,0) [0|1] ""  gtw
 SG_ EPBR_a217_SPI_MIA_debugData2 m3 : 40|1@1+ (1,0) [0|1] ""  gtw
 SG_ EPBR_a216_SPI_MIA_debugData1 m3 : 39|1@1+ (1,0) [0|1] ""  gtw
 SG_ EPBR_a031_UDSActive m0 : 34|1@1+ (1,0) [0|1] ""  gtw
 SG_ EPBR_a030_ECULogUploadRequest m0 : 33|1@1+ (1,0) [0|1] ""  gtw
 SG_ EPBR_a022_TaskInitError m0 : 25|1@1+ (1,0) [0|1] ""  gtw
 SG_ EPBR_a021_TaskSchedulerError m0 : 24|1@1+ (1,0) [0|1] ""  gtw
 SG_ EPBR_a141_invalidState m2 : 24|1@1+ (1,0) [0|1] ""  gtw
 SG_ EPBR_a201_hwBrakeTypeMismatch m3 : 24|1@1+ (1,0) [0|1] ""  gtw
 SG_ EPBR_a200_PmUnparkNotAllowed m3 : 23|1@1+ (1,0) [0|1] ""  gtw
 SG_ EPBR_a138_NVMWriteTime m2 : 21|1@1+ (1,0) [0|1] ""  gtw
 SG_ EPBR_a137_PvUv m2 : 20|1@1+ (1,0) [0|1] ""  gtw
 SG_ EPBR_a136_PvOv m2 : 19|1@1+ (1,0) [0|1] ""  gtw
 SG_ EPBR_a015_NVMMAlert m0 : 18|1@1+ (1,0) [0|1] ""  gtw
 SG_ EPBR_a195_parkForDriverIsLeaving m3 : 18|1@1+ (1,0) [0|1] ""  gtw
 SG_ EPBR_a135_NvUv m2 : 18|1@1+ (1,0) [0|1] ""  gtw
 SG_ EPBR_a134_NvOv m2 : 17|1@1+ (1,0) [0|1] ""  gtw
 SG_ EPBR_a013_AlertManagerFault m0 : 16|1@1+ (1,0) [0|1] ""  gtw
 SG_ EPBR_a012_CPUReset m0 : 15|1@1+ (1,0) [0|1] ""  gtw
 SG_ EPBR_a191_csmReleaseDegraded m3 : 14|1@1+ (1,0) [0|1] ""  gtw
 SG_ EPBR_a251_currentVarianceHigh m4 : 14|1@1+ (1,0) [0|1] ""  gtw
 SG_ EPBR_a190_csmApplyDegraded m3 : 13|1@1+ (1,0) [0|1] ""  gtw
 SG_ EPBR_a250_WinchModeCanceled m4 : 13|1@1+ (1,0) [0|1] ""  gtw
 SG_ EPBR_a010_ExtSupplyVoltError m0 : 13|1@1+ (1,0) [0|1] ""  gtw
 SG_ EPBR_a189_epbDynamicParkCanceled m3 : 12|1@1+ (1,0) [0|1] ""  gtw
 SG_ EPBR_a249_idleFaultRelease m4 : 12|1@1+ (1,0) [0|1] ""  gtw
 SG_ EPBR_a128_MotorPVoltHigh m2 : 11|1@1+ (1,0) [0|1] ""  gtw
 SG_ EPBR_a188_epbDynamic m3 : 11|1@1+ (1,0) [0|1] ""  gtw
 SG_ EPBR_a248_csmDynamicApplyFailed m4 : 11|1@1+ (1,0) [0|1] ""  gtw
 SG_ EPBR_a247_csmDynamicApplyRetry m4 : 10|1@1+ (1,0) [0|1] ""  gtw
 SG_ EPBR_a187_cdpDynamic m3 : 10|1@1+ (1,0) [0|1] ""  gtw
 SG_ EPBR_a127_MotorNVoltHigh m2 : 10|1@1+ (1,0) [0|1] ""  gtw
 SG_ EPBR_a126_MotorNVoltLow m2 : 9|1@1+ (1,0) [0|1] ""  gtw
 SG_ EPBR_a246_idleFaultApply m4 : 9|1@1+ (1,0) [0|1] ""  gtw
 SG_ EPBR_a186_externalParkAbort m3 : 9|1@1+ (1,0) [0|1] ""  gtw
 SG_ EPBR_a245_serviceModeActive m4 : 8|1@1+ (1,0) [0|1] ""  gtw
 SG_ EPBR_a125_IdleVMismatch m2 : 8|1@1+ (1,0) [0|1] ""  gtw
 SG_ EPBR_a185_summonAborted m3 : 8|1@1+ (1,0) [0|1] ""  gtw
 SG_ EPBR_a184_dynamicParkAbort m3 : 7|1@1+ (1,0) [0|1] ""  gtw
 SG_ EPBR_a124_calOutOfBounds m2 : 7|1@1+ (1,0) [0|1] ""  gtw
 SG_ EPBR_a244_WinchModeActive m4 : 7|1@1+ (1,0) [0|1] ""  gtw
 SG_ EPBR_a064_busSleepReqTimeout m1 : 7|1@1+ (1,0) [0|1] ""  gtw
 SG_ EPBR_a063_SwitchFault m1 : 6|1@1+ (1,0) [0|1] ""  gtw
 SG_ EPBR_a003_SWAssertion m0 : 6|1@1+ (1,0) [0|1] ""  gtw
 SG_ EPBR_a183_cdpNotAvailable m3 : 6|1@1+ (1,0) [0|1] ""  gtw
 SG_ EPBR_a243_bdwUnavailable m4 : 6|1@1+ (1,0) [0|1] ""  gtw
 SG_ EPBR_a123_Uc m2 : 6|1@1+ (1,0) [0|1] ""  gtw
 SG_ EPBR_a122_Oc m2 : 5|1@1+ (1,0) [0|1] ""  gtw
 SG_ EPBR_a182_OneEPBAppliedUnsecEnv m3 : 5|1@1+ (1,0) [0|1] ""  gtw
 SG_ EPBR_a062_XCPWasConnected m1 : 5|1@1+ (1,0) [0|1] ""  gtw
 SG_ EPBR_a242_hvOutputLocked m4 : 5|1@1+ (1,0) [0|1] ""  gtw
 SG_ EPBR_a002_PowerLossReset m0 : 5|1@1+ (1,0) [0|1] ""  gtw
 SG_ EPBR_a121_nDriveFault m2 : 4|1@1+ (1,0) [0|1] ""  gtw
 SG_ EPBR_a241_diOutputLocked m4 : 4|1@1+ (1,0) [0|1] ""  gtw
 SG_ EPBR_a181_TooSteepGradeToPark m3 : 4|1@1+ (1,0) [0|1] ""  gtw
 SG_ EPBR_a001_WatchdogReset m0 : 4|1@1+ (1,0) [0|1] ""  gtw
 SG_ EPBR_a061_XCPConnected m1 : 4|1@1+ (1,0) [0|1] ""  gtw
 SG_ EPBR_matrixIndex M : 0|4@1+ (1,0) [0|15] ""  gtw

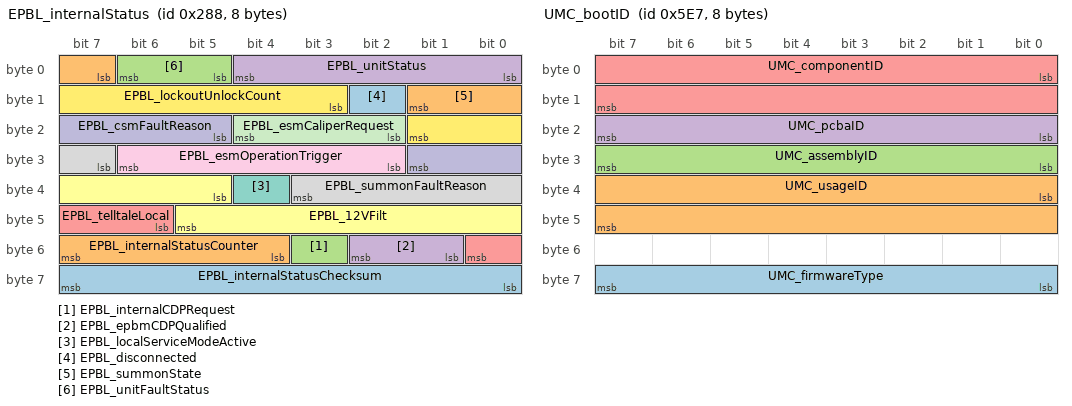
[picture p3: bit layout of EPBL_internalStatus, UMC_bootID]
BO_ 648 EPBL_internalStatus: 8 VEH
 SG_ EPBL_internalStatusChecksum : 56|8@1+ (1,0) [0|255] ""  X
 SG_ EPBL_internalStatusCounter : 52|4@1+ (1,0) [0|15] ""  X
 SG_ EPBL_internalCDPRequest : 51|1@1+ (1,0) [0|1] ""  epbr
 SG_ EPBL_epbmCDPQualified : 49|2@1+ (1,0) [0|2] ""  X
 SG_ EPBL_telltaleLocal : 46|3@1+ (1,0) [0|7] ""  epbr
 SG_ EPBL_12VFilt : 37|9@1+ (0.043549408784,0) [0|22.25375] "V"  gtw
 SG_ EPBL_localServiceModeActive : 36|1@1+ (1,0) [0|1] ""  epbr
 SG_ EPBL_summonFaultReason : 31|5@1+ (1,0) [0|28] ""  gtw
 SG_ EPBL_esmOperationTrigger : 26|5@1+ (1,0) [0|30] ""  gtw
 SG_ EPBL_csmFaultReason : 21|5@1+ (1,0) [0|21] ""  gtw
 SG_ EPBL_esmCaliperRequest : 18|3@1+ (1,0) [0|4] ""  gtw
 SG_ EPBL_lockoutUnlockCount : 11|7@1+ (1,0) [0|127] ""  gtw
 SG_ EPBL_disconnected : 10|1@1+ (1,0) [0|1] ""  epbr
 SG_ EPBL_summonState : 7|3@1+ (1,0) [0|6] ""  epbr
 SG_ EPBL_unitFaultStatus : 5|2@1+ (1,0) [0|3] ""  epbr
 SG_ EPBL_unitStatus : 0|5@1+ (1,0) [0|21] ""  epbr

BO_ 1893 VCSEC_xcpResponse: 8 VEH
 SG_ VCSEC_xcpResponseData : 0|64@1+ (1,0) [0|18446744073709551615] ""  X

BO_ 867 CMP_info: 8 VEH
 SG_ CMP_infoSubUsageId m11 : 48|16@1+ (1,0) [0|65535] ""  gtw
 SG_ CMP_infoComponentId m10 : 48|16@1+ (1,0) [0|65535] ""  gtw
 SG_ CMP_infoAppCrc m13 : 32|32@1+ (1,0) [0|4294967295] ""  gtw
 SG_ CMP_infoBootCrc m20 : 32|32@1+ (1,0) [0|4294967295] ""  gtw
 SG_ CMP_infoUsageId m11 : 32|16@1+ (1,0) [0|65535] ""  gtw
 SG_ CMP_infoHardwareId m10 : 32|16@1+ (1,0) [0|65535] ""  gtw
 SG_ CMP_infoAssemblyId m11 : 24|8@1+ (1,0) [0|255] ""  gtw
 SG_ CMP_infoBuildConfigId m10 : 16|16@1+ (1,0) [0|65535] ""  gtw
 SG_ CMP_infoPcbaId m11 : 16|8@1+ (1,0) [0|255] ""  gtw
 SG_ CMP_infoBootUdsProtoVersion m20 : 8|8@1+ (1,0) [0|255] ""  gtw
 SG_ CMP_infoBuildType m10 : 8|8@1+ (1,0) [0|4] ""  gtw
 SG_ CMP_infoPlatformType m13 : 8|8@1+ (1,0) [0|255] ""  gtw
 SG_ CMP_infoIndex M : 0|8@1+ (1,0) [0|255] ""  gtw

BO_ 1511 UMC_bootID: 8 VEH
 SG_ UMC_firmwareType : 56|8@1+ (1,0) [0|255] ""  X
 SG_ UMC_usageID : 32|16@1+ (1,0) [0|65535] ""  X
 SG_ UMC_assemblyID : 24|8@1+ (1,0) [0|255] ""  X
 SG_ UMC_pcbaID : 16|8@1+ (1,0) [0|255] ""  X
 SG_ UMC_componentID : 0|16@1+ (1,0) [0|65535] ""  dbg

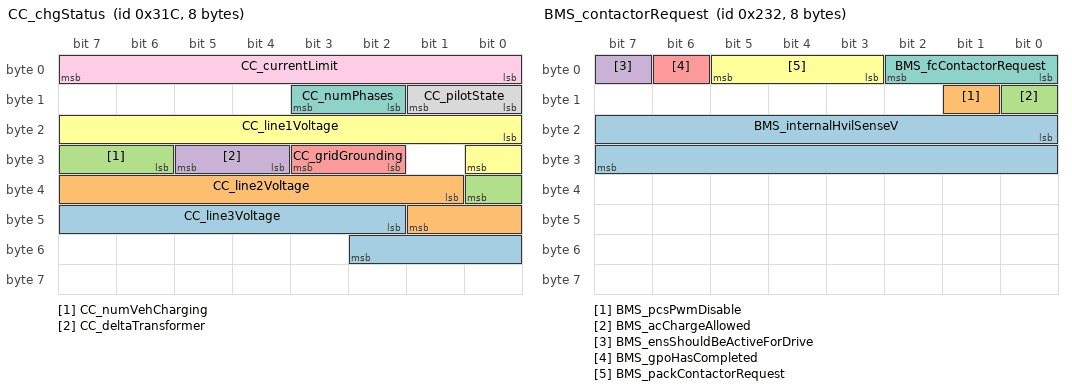
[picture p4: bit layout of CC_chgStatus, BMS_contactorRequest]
BO_ 796 CC_chgStatus: 8 VEH
 SG_ CC_line3Voltage : 42|9@1+ (1,0) [0|511] "V"  gtw
 SG_ CC_line2Voltage : 33|9@1+ (1,0) [0|511] "V"  gtw
 SG_ CC_numVehCharging : 30|3@1+ (1,0) [0|7] ""  gtw
 SG_ CC_deltaTransformer : 28|2@1+ (1,0) [0|3] ""  gtw
 SG_ CC_gridGrounding : 26|2@1+ (1,0) [0|2] ""  gtw
 SG_ CC_line1Voltage : 16|9@1+ (1,0) [0|511] "V"  gtw
 SG_ CC_numPhases : 10|2@1+ (1,0) [0|3] ""  gtw
 SG_ CC_pilotState : 8|2@1+ (1,0) [0|3] ""  gtw
 SG_ CC_currentLimit : 0|8@1+ (0.5,0) [0|127.5] "A"  dbg

BO_ 1796 DBG_xcpPMCommand: 8 VEH
 SG_ DBG_xcpPMCommand : 7|64@0+ (1,0) [0|18446744073709551615] ""  pm

BO_ 1799 DBG_intrusionSensor: 3 VEH
 SG_ DBG_IS_Reserved_06 : 23|1@1+ (1,0) [0|1] ""  vcleft
 SG_ DBG_IS_Siren_Alarm_Cycles : 22|1@1+ (1,0) [0|1] ""  vcleft
 SG_ DBG_IS_Siren_Tone : 21|1@1+ (1,0) [0|1] ""  vcleft
 SG_ DBG_IS_Siren_Beep_Duration : 19|2@1+ (1,0) [0|3] ""  vcleft
 SG_ DBG_IS_Siren_Beep_Type : 17|2@1+ (1,0) [0|3] ""  vcleft
 SG_ DBG_IS_Siren_Alarm : 16|1@1+ (1,0) [0|1] ""  vcleft
 SG_ DBG_IS_Reserved_05 : 15|1@1+ (1,0) [0|1] ""  vcleft
 SG_ DBG_IS_Reserved_04 : 14|1@1+ (1,0) [0|1] ""  vcleft
 SG_ DBG_IS_Reserved_03 : 13|1@1+ (1,0) [0|1] ""  vcleft
 SG_ DBG_IS_Reserved_02 : 12|1@1+ (1,0) [0|1] ""  vcleft
 SG_ DBG_IS_Vehicles_Settings : 8|4@1+ (1,0) [0|15] ""  vcleft
 SG_ DBG_IS_Suspensions : 7|1@1+ (1,0) [0|1] ""  vcleft
 SG_ DBG_IS_Reserved_01 : 6|1@1+ (1,0) [0|1] ""  vcleft
 SG_ DBG_IS_Window : 5|1@1+ (1,0) [0|1] ""  vcleft
 SG_ DBG_IS_Heater : 4|1@1+ (1,0) [0|1] ""  vcleft
 SG_ DBG_IS_Air_Conditioned : 3|1@1+ (1,0) [0|1] ""  vcleft
 SG_ DBG_IS_USS_Operation : 0|3@1+ (1,0) [0|7] ""  vcleft

BO_ 737 VCFRONT_status: 8 VEH
 SG_ VCFRONT_frunkAccessPost m0 : 62|1@1+ (1,0) [0|1] ""  gtw
 SG_ VCFRONT_headlampRightFanStatus m0 : 61|1@1+ (1,0) [0|1] ""  gtw
 SG_ VCFRONT_headlampLeftFanStatus m0 : 60|1@1+ (1,0) [0|1] ""  gtw
 SG_ VCFRONT_12VOverchargeCounter m4 : 59|4@1+ (1,0) [0|15] ""  gtw
 SG_ VCFRONT_sleepCurrent m1 : 53|10@1- (1,0) [-512|511] "mA"  gtw
 SG_ VCFRONT_wiperPositionDeg m0 : 52|8@1+ (1,0) [0|255] "deg"  X
 SG_ VCFRONT_hornOn m0 : 51|1@1+ (1,0) [0|1] ""  gtw
 SG_ VCFRONT_anyDoorOpen m0 : 50|1@1+ (1,0) [0|1] ""  gtw
 SG_ VCFRONT_anyClosureOpen m0 : 49|1@1+ (1,0) [0|1] ""  gtw
 SG_ VCFRONT_wiperCycles m3 : 48|16@1+ (100,0) [0|6553500] "Cycles"  gtw
 SG_ VCFRONT_homelinkCommStatus m2 : 48|2@1+ (1,0) [0|3] ""  gtw
 SG_ VCFRONT_frunkInteriorRelSwitch m0 : 48|1@1+ (1,0) [0|1] ""  gtw
 SG_ VCFRONT_timeSpentSleeping m1 : 45|8@1+ (1,0) [0|255] "s"  gtw
 SG_ VCFRONT_IBSUnfilteredTemperature m4 : 43|16@1- (0.01,0) [-327.68|327.67] "degC"  gtw
 SG_ VCFRONT_HSDInitCompleteU16 m4 : 42|1@1+ (1,0) [0|1] ""  gtw
 SG_ VCFRONT_HSDInitCompleteU13 m4 : 41|1@1+ (1,0) [0|1] ""  gtw
 SG_ VCFRONT_PEResetLineState m4 : 40|1@1+ (1,0) [0|1] ""  gtw
 SG_ VCFRONT_pressureRefrigDischarge m3 : 40|8@1+ (0.125,0) [0|31.75] "bar"  gtw
 SG_ VCFRONT_homelinkV2Response4 m2 : 40|8@1+ (1,0) [0|255] ""  gtw
 SG_ VCFRONT_IBSFault m4 : 39|1@1+ (1,0) [0|1] ""  gtw
 SG_ VCFRONT_PCSMia m4 : 38|1@1+ (1,0) [0|1] ""  gtw
 SG_ VCFRONT_headlightRightVPosition m0 : 38|10@1+ (1,0) [0|1023] "ticks"  X
 SG_ VCFRONT_chargeNeeded m4 : 37|1@1+ (1,0) [0|1] ""  gtw
 SG_ VCFRONT_timeSpentDischarging m1 : 35|10@1+ (1,0) [0|1023] "min"  gtw
 SG_ VCFRONT_pressureRefrigSuction m3 : 32|7@1+ (0.125,0) [0|11.5] "bar"  gtw
 SG_ VCFRONT_homelinkV2Response3 m2 : 32|8@1+ (1,0) [0|255] ""  gtw
 SG_ VCFRONT_hasLowRefrigerant m3 : 29|1@1+ (1,0) [0|1] ""  gtw
 SG_ VCFRONT_headlightLeftVPosition m0 : 28|10@1+ (1,0) [0|1023] "ticks"  X
 SG_ VCFRONT_compPerfRecoveryLimited m3 : 27|1@1+ (1,0) [0|1] ""  gtw
 SG_ VCFRONT_chillerDemandActive m3 : 26|1@1+ (1,0) [0|1] ""  gtw
 SG_ VCFRONT_timeSpentCharging m1 : 25|10@1+ (1,0) [0|1023] "min"  gtw
 SG_ VCFRONT_isEvapOperationAllowed m3 : 25|1@1+ (1,0) [0|1] ""  gtw
 SG_ VCFRONT_airCompressorStatus m0 : 25|3@1+ (1,0) [0|7] ""  gtw
 SG_ VCFRONT_AS8510Voltage m4 : 25|12@1+ (0.005443676098,0) [0|22.28641] "V"  gtw
 SG_ VCFRONT_crashUnlockOverrideSet m0 : 24|1@1+ (1,0) [0|1] ""  gtw
 SG_ VCFRONT_freezeEvapITerm m3 : 24|1@1+ (1,0) [0|1] ""  gtw
 SG_ VCFRONT_homelinkV2Response2 m2 : 24|8@1+ (1,0) [0|255] ""  gtw
 SG_ VCFRONT_crashState m0 : 22|2@1+ (1,0) [0|2] ""  gtw
 SG_ VCFRONT_batterySMState m1 : 22|3@1+ (1,0) [0|7] ""  gtw
 SG_ VCFRONT_reverseBatteryFault m1 : 21|1@1+ (1,0) [0|1] ""  X
 SG_ VCFRONT_crashDetectedType m0 : 20|2@1+ (1,0) [0|2] ""  gtw
 SG_ VCFRONT_vehicleStatusDBG m1 : 16|5@1+ (1,0) [0|17] ""  aps
 SG_ VCFRONT_wiperState m0 : 16|4@1+ (1,0) [0|12] ""  das
 SG_ VCFRONT_homelinkV2Response1 m2 : 16|8@1+ (1,0) [0|255] ""  gtw
 SG_ VCFRONT_minEvapHeatRejection m3 : 16|8@1+ (10,0) [0|2500] "W"  vcright
 SG_ VCFRONT_vbatMonitorVoltage m4 : 13|12@1+ (0.005443676098,0) [0|22.28641] "V"  gtw
 SG_ VCFRONT_iBoosterStateDBG m1 : 12|3@1+ (1,0) [0|4] ""  gtw
 SG_ VCFRONT_wiperPosition m0 : 12|3@1+ (1,0) [0|4] ""  gtw
 SG_ VCFRONT_epasWakeLine m1 : 11|1@1+ (1,0) [0|1] ""  gtw
 SG_ VCFRONT_iBoosterWakeLine m1 : 10|1@1+ (1,0) [0|1] ""  gtw
 SG_ VCFRONT_ChargePumpVoltageStable m1 : 9|1@1+ (1,0) [0|1] ""  gtw
 SG_ VCFRONT_homelinkV2Response0 m2 : 8|8@1+ (1,0) [0|255] ""  gtw
 SG_ VCFRONT_railBState m1 : 8|1@1+ (1,0) [0|1] ""  gtw
 SG_ VCFRONT_maxEvapHeatRejection m3 : 8|8@1+ (32,0) [0|8000] "W"  vcright
 SG_ VCFRONT_wiperSpeed m0 : 8|4@1+ (1,0) [0|8] ""  das
 SG_ VCFRONT_railAState m1 : 7|1@1+ (1,0) [0|1] ""  gtw
 SG_ VCFRONT_12VBRailStable m1 : 6|1@1+ (1,0) [0|1] ""  gtw
 SG_ VCFRONT_12VARailStable m1 : 5|1@1+ (1,0) [0|1] ""  gtw
 SG_ VCFRONT_5VBRailStable m1 : 4|1@1+ (1,0) [0|1] ""  gtw
 SG_ VCFRONT_frunkLatchStatus m0 : 3|4@1+ (1,0) [0|8] ""  di
 SG_ VCFRONT_tempCompTargetVoltage m4 : 3|10@1+ (0.01,9) [9|16] "V"  gtw
 SG_ VCFRONT_5VARailStable m1 : 3|1@1+ (1,0) [0|1] ""  gtw
 SG_ VCFRONT_statusIndex M : 0|3@1+ (1,0) [0|5] ""  X

BO_ 1798 DBG_xcpDICommand: 8 VEH
 SG_ DBG_xcpDICommand : 7|64@0+ (1,0) [0|18446744073709551615] ""  di

BO_ 562 BMS_contactorRequest: 8 VEH
 SG_ BMS_internalHvilSenseV : 16|16@1+ (0.001,0) [0|65.534] "V"  X
 SG_ BMS_pcsPwmDisable : 9|1@1+ (1,0) [0|1] ""  X
 SG_ BMS_acChargeAllowed : 8|1@1+ (1,0) [0|1] ""  X
 SG_ BMS_ensShouldBeActiveForDrive : 7|1@1+ (1,0) [0|1] ""  X
 SG_ BMS_gpoHasCompleted : 6|1@1+ (1,0) [0|1] ""  X
 SG_ BMS_packContactorRequest : 3|3@1+ (1,0) [0|5] ""  gtw
 SG_ BMS_fcContactorRequest : 0|3@1+ (1,0) [0|5] ""  gtw

BO_ 825 VCSEC_authentication: 8 VEH
 SG_ VCSEC_authRequested : 60|1@1+ (1,0) [0|1] ""  gtw
 SG_ VCSEC_keyChannelIndexed : 56|4@1+ (1,0) [0|15] ""  gtw
 SG_ VCSEC_simpleLockStatus : 54|2@1+ (1,0) [0|2] ""  gtw
 SG_ VCSEC_lockIndicationRequest : 51|3@1+ (1,0) [0|4] ""  gtw
 SG_ VCSEC_immobilizerState : 48|3@1+ (1,0) [0|5] ""  bms
 SG_ VCSEC_alarmStatus : 43|4@1+ (1,0) [0|15] ""  bms
 SG_ VCSEC_isKeyWithinSummonRange : 41|1@1+ (1,0) [0|1] ""  gtw
 SG_ VCSEC_usingModifiedMACAddress : 40|1@1+ (1,0) [0|1] ""  gtw
 SG_ VCSEC_prsntRsnDeltaP : 39|1@1+ (1,0) [0|1] ""  gtw
 SG_ VCSEC_MCUCommandType : 36|3@1+ (1,0) [0|5] ""  bms
 SG_ VCSEC_frunkRequest : 34|2@1+ (1,0) [0|2] ""  gtw
 SG_ VCSEC_trunkRequest : 32|2@1+ (1,0) [0|2] ""  gtw
 SG_ VCSEC_summonRequest : 29|3@1+ (1,0) [0|5] ""  gtw
 SG_ VCSEC_lockRequestType : 24|5@1+ (1,0) [0|19] ""  gtw
 SG_ VCSEC_trunkLockStatus : 23|1@1+ (1,0) [0|1] ""  gtw
 SG_ VCSEC_rightRearLockStatus : 22|1@1+ (1,0) [0|1] ""  gtw
 SG_ VCSEC_rightFrontLockStatus : 21|1@1+ (1,0) [0|1] ""  gtw
 SG_ VCSEC_leftRearLockStatus : 20|1@1+ (1,0) [0|1] ""  gtw
 SG_ VCSEC_leftFrontLockStatus : 19|1@1+ (1,0) [0|1] ""  gtw
 SG_ VCSEC_chargePortLockStatus : 18|1@1+ (1,0) [0|1] ""  bms
 SG_ VCSEC_authenticationStatus : 16|2@1+ (1,0) [0|2] ""  gtw
 SG_ VCSEC_vehicleLockStatus : 12|4@1+ (1,0) [0|15] ""  gtw
 SG_ VCSEC_numberOfPubKeysOnWhitelist : 6|5@1+ (1,0) [0|31] ""  bms
 SG_ VCSEC_prsntRsnHighThresholdR : 5|1@1+ (1,0) [0|1] ""  gtw
 SG_ VCSEC_prsntRsnDeltaR : 4|1@1+ (1,0) [0|1] ""  gtw
 SG_ VCSEC_prsntRsnDeltaD : 3|1@1+ (1,0) [0|1] ""  gtw
 SG_ VCSEC_prsntRsnHighThresholdP : 2|1@1+ (1,0) [0|1] ""  gtw
 SG_ VCSEC_prsntRsnHighThresholdD : 1|1@1+ (1,0) [0|1] ""  gtw
 SG_ VCSEC_prsntRsnHighThresholdC : 0|1@1+ (1,0) [0|1] ""  gtw

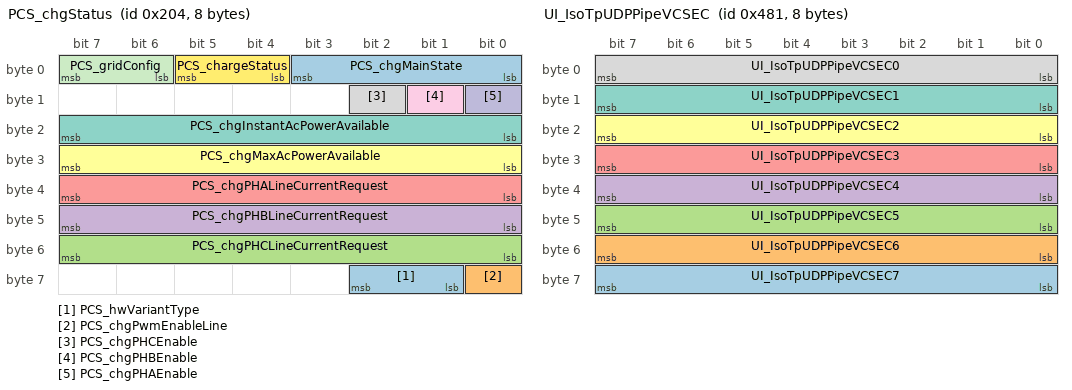
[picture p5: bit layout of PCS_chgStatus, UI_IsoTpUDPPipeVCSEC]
BO_ 516 PCS_chgStatus: 8 VEH
 SG_ PCS_hwVariantType : 57|2@1+ (1,0) [0|2] ""  gtw
 SG_ PCS_chgPwmEnableLine : 56|1@1+ (1,0) [0|1] ""  gtw
 SG_ PCS_chgPHCLineCurrentRequest : 48|8@1+ (0.1,0) [0|20] "A"  dbg
 SG_ PCS_chgPHBLineCurrentRequest : 40|8@1+ (0.1,0) [0|20] "A"  dbg
 SG_ PCS_chgPHALineCurrentRequest : 32|8@1+ (0.1,0) [0|20] "A"  dbg
 SG_ PCS_chgMaxAcPowerAvailable : 24|8@1+ (0.1,0) [0|20] "kW"  dbg
 SG_ PCS_chgInstantAcPowerAvailable : 16|8@1+ (0.1,0) [0|20] "kW"  gtw
 SG_ PCS_chgPHCEnable : 10|1@1+ (1,0) [0|1] ""  dbg
 SG_ PCS_chgPHBEnable : 9|1@1+ (1,0) [0|1] ""  dbg
 SG_ PCS_chgPHAEnable : 8|1@1+ (1,0) [0|1] ""  dbg
 SG_ PCS_gridConfig : 6|2@1+ (1,0) [0|3] ""  dbg
 SG_ PCS_chargeStatus : 4|2@1+ (1,0) [0|2] ""  dbg
 SG_ PCS_chgMainState : 0|4@1+ (1,0) [0|9] ""  dbg

BO_ 1153 UI_IsoTpUDPPipeVCSEC: 8 VEH
 SG_ UI_IsoTpUDPPipeVCSEC7 : 63|8@0+ (1,0) [0|255] ""  vcsec
 SG_ UI_IsoTpUDPPipeVCSEC6 : 55|8@0+ (1,0) [0|255] ""  vcsec
 SG_ UI_IsoTpUDPPipeVCSEC5 : 47|8@0+ (1,0) [0|255] ""  vcsec
 SG_ UI_IsoTpUDPPipeVCSEC4 : 39|8@0+ (1,0) [0|255] ""  vcsec
 SG_ UI_IsoTpUDPPipeVCSEC3 : 31|8@0+ (1,0) [0|255] ""  vcsec
 SG_ UI_IsoTpUDPPipeVCSEC2 : 23|8@0+ (1,0) [0|255] ""  vcsec
 SG_ UI_IsoTpUDPPipeVCSEC1 : 15|8@0+ (1,0) [0|255] ""  vcsec
 SG_ UI_IsoTpUDPPipeVCSEC0 : 7|8@0+ (1,0) [0|255] ""  vcsec

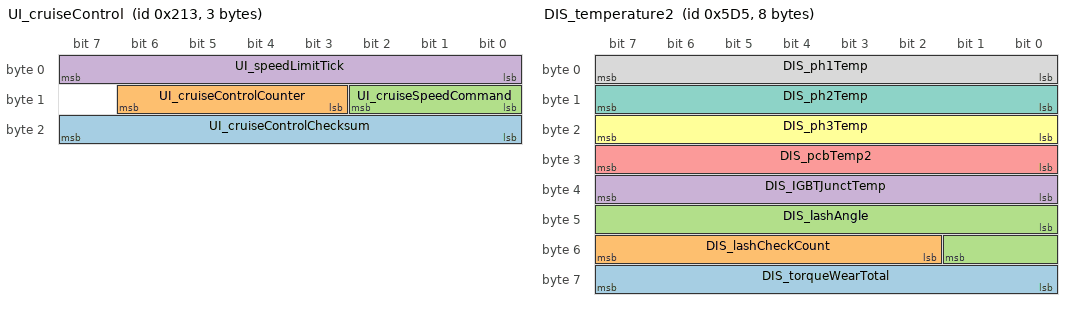
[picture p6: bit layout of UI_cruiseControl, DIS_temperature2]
BO_ 531 UI_cruiseControl: 3 VEH
 SG_ UI_cruiseControlChecksum : 16|8@1+ (1,0) [0|255] ""  X
 SG_ UI_cruiseControlCounter : 11|4@1+ (1,0) [0|15] ""  X
 SG_ UI_cruiseSpeedCommand : 8|3@1+ (1,0) [0|5] ""  das
 SG_ UI_speedLimitTick : 0|8@1+ (1,0) [0|200] "speed"  di

BO_ 1493 DIS_temperature2: 8 VEH
 SG_ DIS_torqueWearTotal : 56|8@1+ (0.02,0) [0|5.08] "1"  gtw
 SG_ DIS_lashCheckCount : 50|6@1+ (1,0) [0|63] ""  X
 SG_ DIS_lashAngle : 40|10@1+ (0.06,0) [0|60] "Deg"  X
 SG_ DIS_IGBTJunctTemp : 32|8@1+ (1,-40) [-40|200] "DegC"  gtw
 SG_ DIS_pcbTemp2 : 24|8@1+ (1,-40) [-40|150] "DegC"  gtw
 SG_ DIS_ph3Temp : 16|8@1+ (1,-40) [-40|120] "DegC"  X
 SG_ DIS_ph2Temp : 8|8@1+ (1,-40) [-40|120] "DegC"  gtw
 SG_ DIS_ph1Temp : 0|8@1+ (1,-40) [-40|120] "DegC"  gtw

BO_ 1550 UDS_cpRequest: 8 VEH
 SG_ UDS_cpRequestData : 7|64@0+ (1,0) [0|18446744073709551615] ""  bms

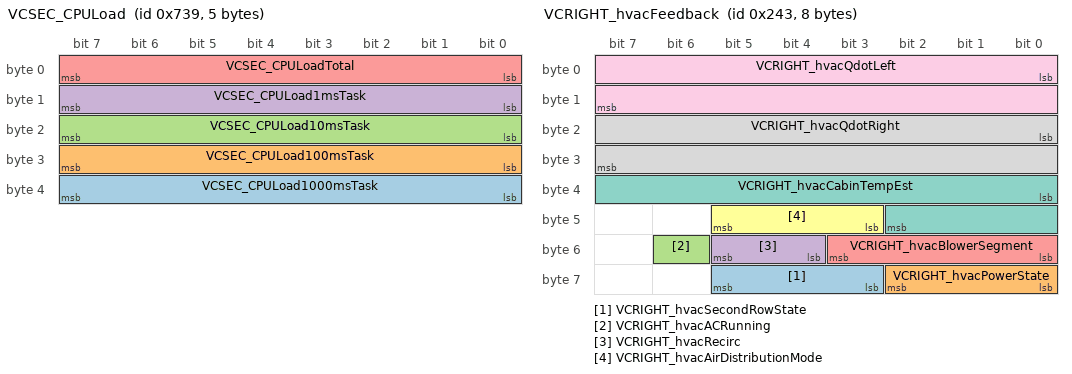
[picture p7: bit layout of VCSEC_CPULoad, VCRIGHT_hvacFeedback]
BO_ 1849 VCSEC_CPULoad: 5 VEH
 SG_ VCSEC_CPULoad1000msTask : 32|8@1+ (1,0) [0|255] ""  X
 SG_ VCSEC_CPULoad100msTask : 24|8@1+ (1,0) [0|255] ""  X
 SG_ VCSEC_CPULoad10msTask : 16|8@1+ (1,0) [0|255] ""  X
 SG_ VCSEC_CPULoad1msTask : 8|8@1+ (1,0) [0|255] ""  X
 SG_ VCSEC_CPULoadTotal : 0|8@1+ (1,0) [0|255] ""  X

BO_ 821 DIS_info: 8 VEH
 SG_ DIS_componentId m10 : 48|16@1+ (1,0) [0|65535] ""  gtw
 SG_ DIS_subUsageId m11 : 48|16@1+ (1,0) [0|65535] ""  gtw
 SG_ DIS_applicationSvnUrlHash m12 : 32|32@1+ (1,0) [0|4294967295] ""  gtw
 SG_ DIS_bootloaderSvnUrlHash m14 : 32|32@1+ (1,0) [0|4294967295] ""  gtw
 SG_ DIS_bootloaderCrc m20 : 32|32@1+ (1,0) [0|4294967295] ""  gtw
 SG_ DIS_usageId m11 : 32|16@1+ (1,0) [0|65535] ""  gtw
 SG_ DIS_applicationCrc m13 : 32|32@1+ (1,0) [0|4294967295] ""  gtw
 SG_ DIS_hardwareId m10 : 32|8@1+ (1,0) [0|252] ""  gtw
 SG_ DIS_assemblyId m11 : 24|8@1+ (1,0) [0|255] ""  gtw
 SG_ DIS_oilPumpAppCrc m16 : 16|32@1+ (1,0) [0|4294967295] ""  gtw
 SG_ DIS_buildConfigurationId m10 : 16|16@1+ (1,0) [0|65535] ""  gtw
 SG_ DIS_pcbaId m11 : 16|8@1+ (1,0) [0|255] ""  gtw
 SG_ DIS_appGitHash m17 : 8|56@1+ (1,0) [0|72057594037927935] ""  gtw
 SG_ DIS_bootloaderSvnRevision m14 : 8|24@1+ (1,0) [0|16777215] ""  gtw
 SG_ DIS_platformTyp m19 : 8|8@1+ (1,0) [0|255] ""  gtw
 SG_ DIS_applicationSvnRevision m12 : 8|24@1+ (1,0) [0|16777215] ""  gtw
 SG_ DIS_oilPumpBuildType m16 : 8|3@1+ (1,0) [0|4] ""  gtw
 SG_ DIS_subcomponentGitHash m31 : 8|56@1+ (1,0) [0|72057594037927935] ""  X
 SG_ DIS_bootGitHash m18 : 8|56@1+ (1,0) [0|72057594037927935] ""  gtw
 SG_ DIS_buildType m10 : 8|3@1+ (1,0) [0|4] ""  gtw
 SG_ DIS_infoBootLdUdsProtocolVersion m20 : 8|8@1+ (1,0) [0|255] ""  gtw
 SG_ DIS_infoIndex M : 0|8@1+ (1,0) [0|255] ""  gtw

BO_ 579 VCRIGHT_hvacFeedback: 8 VEH
 SG_ VCRIGHT_hvacSecondRowState : 59|3@1+ (1,0) [0|4] ""  gtw
 SG_ VCRIGHT_hvacPowerState : 56|3@1+ (1,0) [0|4] ""  gtw
 SG_ VCRIGHT_hvacACRunning : 54|1@1+ (1,0) [0|1] ""  gtw
 SG_ VCRIGHT_hvacRecirc : 52|2@1+ (1,0) [0|2] ""  gtw
 SG_ VCRIGHT_hvacBlowerSegment : 48|4@1+ (1,0) [0|11] ""  gtw
 SG_ VCRIGHT_hvacAirDistributionMode : 43|3@1+ (1,0) [0|7] ""  gtw
 SG_ VCRIGHT_hvacCabinTempEst : 32|11@1+ (0.1,-40) [-40|164] "degC"  gtw
 SG_ VCRIGHT_hvacQdotRight : 16|16@1+ (1,-32767) [-32767|32767] "W"  gtw
 SG_ VCRIGHT_hvacQdotLeft : 0|16@1+ (1,-32767) [-32767|32767] "W"  gtw

BO_ 822 DI_maxRatedPower: 3 VEH
 SG_ DI_sysRegenPowerRated : 16|8@1+ (1,-100) [-100|0] "kW"  gtw
 SG_ DI_sysDrivePowerRated : 0|9@1+ (1,0) [0|400] "kW"  gtw

BO_ 1810 BMS_packTemperatureMeasurements: 8 VEH
 SG_ BMS_packTemperature6 m1 : 48|16@1- (0.01,0) [-327.68|327.67] "C"  dbg
 SG_ BMS_packTemperature12 m3 : 48|16@1- (0.01,0) [-327.68|327.67] "C"  dbg
 SG_ BMS_packTemperature15 m4 : 48|16@1- (0.01,0) [-327.68|327.67] "C"  dbg
 SG_ BMS_packTemperature18 m5 : 48|16@1- (0.01,0) [-327.68|327.67] "C"  dbg
 SG_ BMS_packTemperature3 m0 : 48|16@1- (0.01,0) [-327.68|327.67] "C"  dbg
 SG_ BMS_packTemperature9 m2 : 48|16@1- (0.01,0) [-327.68|327.67] "C"  dbg
 SG_ BMS_packTemperature11 m3 : 32|16@1- (0.01,0) [-327.68|327.67] "C"  dbg
 SG_ BMS_packTemperature8 m2 : 32|16@1- (0.01,0) [-327.68|327.67] "C"  dbg
 SG_ BMS_packTemperature14 m4 : 32|16@1- (0.01,0) [-327.68|327.67] "C"  dbg
 SG_ BMS_packTemperature5 m1 : 32|16@1- (0.01,0) [-327.68|327.67] "C"  dbg
 SG_ BMS_packTemperature17 m5 : 32|16@1- (0.01,0) [-327.68|327.67] "C"  dbg
 SG_ BMS_packTemperature2 m0 : 32|16@1- (0.01,0) [-327.68|327.67] "C"  dbg
 SG_ BMS_packTemperature7 m2 : 16|16@1- (0.01,0) [-327.68|327.67] "C"  dbg
 SG_ BMS_packTemperature1 m0 : 16|16@1- (0.01,0) [-327.68|327.67] "C"  dbg
 SG_ BMS_packTemperature13 m4 : 16|16@1- (0.01,0) [-327.68|327.67] "C"  dbg
 SG_ BMS_packTemperature16 m5 : 16|16@1- (0.01,0) [-327.68|327.67] "C"  dbg
 SG_ BMS_packTemperature4 m1 : 16|16@1- (0.01,0) [-327.68|327.67] "C"  dbg
 SG_ BMS_packTemperature10 m3 : 16|16@1- (0.01,0) [-327.68|327.67] "C"  dbg
 SG_ BMS_thermistorStatus12 m3 : 12|2@1+ (1,0) [0|3] ""  dbg
 SG_ BMS_thermistorStatus18 m5 : 12|2@1+ (1,0) [0|3] ""  dbg
 SG_ BMS_thermistorStatus6 m1 : 12|2@1+ (1,0) [0|3] ""  dbg
 SG_ BMS_thermistorStatus3 m0 : 12|2@1+ (1,0) [0|3] ""  dbg
 SG_ BMS_thermistorStatus15 m4 : 12|2@1+ (1,0) [0|3] ""  dbg
 SG_ BMS_thermistorStatus9 m2 : 12|2@1+ (1,0) [0|3] ""  dbg
 SG_ BMS_thermistorStatus14 m4 : 10|2@1+ (1,0) [0|3] ""  dbg
 SG_ BMS_thermistorStatus2 m0 : 10|2@1+ (1,0) [0|3] ""  dbg
 SG_ BMS_thermistorStatus11 m3 : 10|2@1+ (1,0) [0|3] ""  dbg
 SG_ BMS_thermistorStatus8 m2 : 10|2@1+ (1,0) [0|3] ""  dbg
 SG_ BMS_thermistorStatus5 m1 : 10|2@1+ (1,0) [0|3] ""  dbg
 SG_ BMS_thermistorStatus17 m5 : 10|2@1+ (1,0) [0|3] ""  dbg
 SG_ BMS_thermistorStatus4 m1 : 8|2@1+ (1,0) [0|3] ""  dbg
 SG_ BMS_thermistorStatus1 m0 : 8|2@1+ (1,0) [0|3] ""  dbg
 SG_ BMS_thermistorStatus13 m4 : 8|2@1+ (1,0) [0|3] ""  dbg
 SG_ BMS_thermistorStatus7 m2 : 8|2@1+ (1,0) [0|3] ""  dbg
 SG_ BMS_thermistorStatus10 m3 : 8|2@1+ (1,0) [0|3] ""  dbg
 SG_ BMS_thermistorStatus16 m5 : 8|2@1+ (1,0) [0|3] ""  dbg
 SG_ BMS_packTemperatureMultiplexer M : 0|8@1+ (1,0) [0|5] ""  dbg

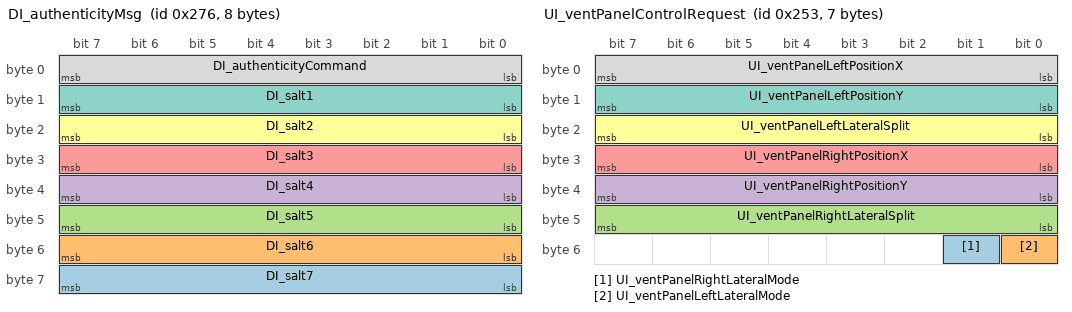
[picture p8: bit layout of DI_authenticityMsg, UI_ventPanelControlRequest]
BO_ 630 DI_authenticityMsg: 8 VEH
 SG_ DI_salt7 : 56|8@1+ (1,0) [0|255] ""  vcsec
 SG_ DI_salt6 : 48|8@1+ (1,0) [0|255] ""  vcsec
 SG_ DI_salt5 : 40|8@1+ (1,0) [0|255] ""  vcsec
 SG_ DI_salt4 : 32|8@1+ (1,0) [0|255] ""  vcsec
 SG_ DI_salt3 : 24|8@1+ (1,0) [0|255] ""  vcsec
 SG_ DI_salt2 : 16|8@1+ (1,0) [0|255] ""  vcsec
 SG_ DI_salt1 : 8|8@1+ (1,0) [0|255] ""  vcsec
 SG_ DI_authenticityCommand : 0|8@1+ (1,0) [0|255] ""  vcsec

BO_ 595 UI_ventPanelControlRequest: 7 VEH
 SG_ UI_ventPanelRightLateralMode : 49|1@1+ (1,0) [0|1] ""  vcright
 SG_ UI_ventPanelLeftLateralMode : 48|1@1+ (1,0) [0|1] ""  vcright
 SG_ UI_ventPanelRightLateralSplit : 40|8@1+ (0.5,0) [0|100] "%"  vcright
 SG_ UI_ventPanelRightPositionY : 32|8@1+ (0.5,0) [0|100] "%"  vcright
 SG_ UI_ventPanelRightPositionX : 24|8@1+ (0.5,0) [0|100] "%"  vcright
 SG_ UI_ventPanelLeftLateralSplit : 16|8@1+ (0.5,0) [0|100] "%"  vcright
 SG_ UI_ventPanelLeftPositionY : 8|8@1+ (0.5,0) [0|100] "%"  vcright
 SG_ UI_ventPanelLeftPositionX : 0|8@1+ (0.5,0) [0|100] "%"  vcright

BO_ 1992 EPBL_info: 8 VEH
 SG_ EPBL_infoComponentId m10 : 48|16@1+ (1,0) [0|65535] ""  gtw
 SG_ EPBL_infoSubUsageId m11 : 40|16@1+ (1,0) [0|65535] ""  gtw
 SG_ EPBL_infoHardwareId m10 : 32|16@1+ (1,0) [0|65535] ""  gtw
 SG_ EPBL_infoUsageId m11 : 24|16@1+ (1,0) [0|65535] ""  gtw
 SG_ EPBL_infoBootCrc m20 : 24|32@1+ (1,0) [0|4294967295] ""  gtw
 SG_ EPBL_infoBuildConfigId m10 : 16|16@1+ (1,0) [0|65535] ""  gtw
 SG_ EPBL_infoAssemblyId m11 : 16|8@1+ (1,0) [0|255] ""  gtw
 SG_ EPBL_infoAppCrc m13 : 8|32@1+ (1,0) [0|4294967295] ""  gtw
 SG_ EPBL_infoAppGitHash m17 : 8|56@1+ (1,0) [0|72057594037927935] ""  gtw
 SG_ EPBL_infoBootGitHash m18 : 8|56@1+ (1,0) [0|72057594037927935] ""  gtw
 SG_ EPBL_infoBuildType m10 : 8|3@1+ (1,0) [0|4] ""  gtw
 SG_ EPBL_infoPlatformType m19 : 8|8@1+ (1,0) [0|255] ""  gtw
 SG_ EPBL_infoBootUdsProtoVersion m20 : 8|16@1+ (1,0) [0|65535] ""  gtw
 SG_ EPBL_infoPcbaId m11 : 8|8@1+ (1,0) [0|255] ""  gtw
 SG_ EPBL_infoIndex M : 0|8@1+ (1,0) [0|255] ""  gtw

BO_ 707 VCRIGHT_windowStatus: 8 VEH
 SG_ VCRIGHT_windowCalibratedRR m0 : 62|1@1+ (1,0) [0|1] ""  gtw
 SG_ VCRIGHT_positionRR m0 : 54|8@1+ (10,0) [0|2550] "ticks"  gtw
 SG_ VCRIGHT_motorCurrentRR m0 : 48|6@1- (0.5,0.0) [-15|15] "A"  X
 SG_ VCRIGHT_windowStopReqReasonRR m1 : 48|4@1+ (1,0) [0|8] ""  gtw
 SG_ VCRIGHT_windowStopReasonRR m1 : 42|3@1+ (1,0) [0|6] ""  gtw
 SG_ VCRIGHT_windowThermalModeRR m1 : 40|2@1+ (1,0) [0|3] ""  X
 SG_ VCRIGHT_motorDutyRR m0 : 40|6@1- (5,0) [-100|100] "%"  X
 SG_ VCRIGHT_windowStateRR m0 : 33|4@1+ (1,0) [0|8] ""  gtw
 SG_ VCRIGHT_ThermalTCRR m1 : 32|8@1+ (1,0) [0|255] "s"  X
 SG_ VCRIGHT_windowCalibratedRF m0 : 32|1@1+ (1,0) [0|1] ""  gtw
 SG_ VCRIGHT_windowStopReqReasonRF m1 : 24|4@1+ (1,0) [0|8] ""  gtw
 SG_ VCRIGHT_positionRF m0 : 24|8@1+ (10,0) [0|2550] "ticks"  gtw
 SG_ VCRIGHT_windowStopReasonRF m1 : 18|3@1+ (1,0) [0|6] ""  gtw
 SG_ VCRIGHT_windowThermalModeRF m1 : 16|2@1+ (1,0) [0|3] ""  X
 SG_ VCRIGHT_motorCurrentRF m0 : 16|6@1- (0.5,0.0) [-15|15] "A"  X
 SG_ VCRIGHT_ThermalTCRF m1 : 8|8@1+ (1,0) [0|255] "s"  X
 SG_ VCRIGHT_motorDutyRF m0 : 8|6@1- (5,0) [-100|100] "%"  X
 SG_ VCRIGHT_windowStateRF m0 : 1|4@1+ (1,0) [0|8] ""  gtw
 SG_ VCRIGHT_windowStatusIndex M : 0|1@1+ (1,0) [0|1] ""  X

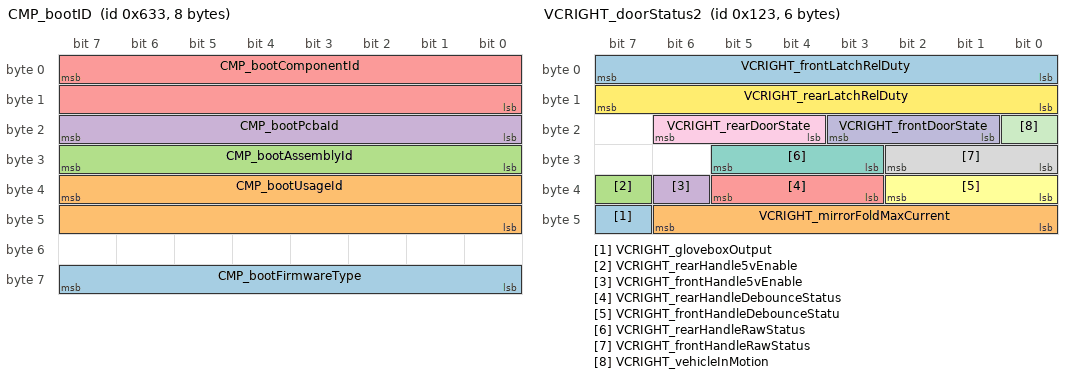
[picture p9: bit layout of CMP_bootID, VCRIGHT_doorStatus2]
BO_ 1587 CMP_bootID: 8 VEH
 SG_ CMP_bootFirmwareType : 63|8@0+ (1,0) [0|255] ""  gtwu
 SG_ CMP_bootUsageId : 39|16@0+ (1,0) [0|65535] ""  gtwu
 SG_ CMP_bootAssemblyId : 31|8@0+ (1,0) [0|255] ""  gtwu
 SG_ CMP_bootPcbaId : 23|8@0+ (1,0) [0|255] ""  gtwu
 SG_ CMP_bootComponentId : 7|16@0+ (1,0) [0|65535] ""  gtwu

BO_ 1894 DI_dlogData: 8 VEH
 SG_ DI_dlogData : 0|64@1+ (1,0) [0|18446744073709551615] ""  dbg

BO_ 1570 UDS_vcleftRequest: 8 VEH
 SG_ UDS_vcleftRequestData_L : 39|32@0+ (1,0) [0|4294967295] ""  vcleft
 SG_ UDS_vcleftRequestData_H : 7|32@0+ (1,0) [0|4294967295] ""  vcleft

BO_ 291 VCRIGHT_doorStatus2: 6 VEH
 SG_ VCRIGHT_gloveboxOutput : 47|1@1+ (1,0) [0|1] ""  gtw
 SG_ VCRIGHT_mirrorFoldMaxCurrent : 40|7@1- (0.046,0.0) [-3|3] "A"  X
 SG_ VCRIGHT_rearHandle5vEnable : 39|1@1+ (1,0) [0|1] ""  gtw
 SG_ VCRIGHT_frontHandle5vEnable : 38|1@1+ (1,0) [0|1] ""  gtw
 SG_ VCRIGHT_rearHandleDebounceStatus : 35|3@1+ (1,0) [0|5] ""  gtw
 SG_ VCRIGHT_frontHandleDebounceStatu : 32|3@1+ (1,0) [0|5] ""  gtw
 SG_ VCRIGHT_rearHandleRawStatus : 27|3@1+ (1,0) [0|5] ""  gtw
 SG_ VCRIGHT_frontHandleRawStatus : 24|3@1+ (1,0) [0|5] ""  gtw
 SG_ VCRIGHT_rearDoorState : 20|3@1+ (1,0) [0|4] ""  gtw
 SG_ VCRIGHT_frontDoorState : 17|3@1+ (1,0) [0|4] ""  gtw
 SG_ VCRIGHT_vehicleInMotion : 16|1@1+ (1,0) [0|1] ""  gtw
 SG_ VCRIGHT_rearLatchRelDuty : 8|8@1+ (1,0) [0|255] "%"  gtw
 SG_ VCRIGHT_frontLatchRelDuty : 0|8@1+ (1,0) [0|255] "%"  gtw

BO_ 1814 DI_xcpResponse: 8 VEH
 SG_ DI_xcpResponse : 0|64@1+ (1,0) [0|18446744073709551615] ""  dbg

BO_ 573 CP_chargeStatus: 1 VEH
 SG_ CP_acChargeCurrentLimit : 0|8@1+ (0.5,0) [0|127.5] "A"  gtw

BO_ 1349 VCFRONT_systemStatus: 8 VEH
 SG_ VCFRONT_systemStatusChecksum : 56|8@1+ (1,0) [0|255] ""  X
 SG_ VCFRONT_systemStatusCounter : 52|4@1+ (1,0) [0|15] ""  X
 SG_ VCFRONT_vcrightVoltage m0 : 40|12@1+ (0.005443676098,0) [0|22.28641] "V"  bms
 SG_ VCFRONT_vcleftVoltage m0 : 28|12@1+ (0.005443676098,0) [0|22.28641] "V"  gtw
 SG_ VCFRONT_loadShedTAS m1 : 23|1@1+ (1,0) [0|1] ""  gtw
 SG_ VCFRONT_vcrightCurrent m0 : 16|12@1+ (0.05,0) [0|204.7] "A"  gtw
 SG_ VCFRONT_loadShedPumps_duty m1 : 16|7@1+ (1,0) [0|100] "%"  gtw
 SG_ VCFRONT_loadShedUI m1 : 15|1@1+ (1,0) [0|1] ""  gtw
 SG_ VCFRONT_loadShedRSeatHeaters m1 : 14|1@1+ (1,0) [0|1] ""  gtw
 SG_ VCFRONT_loadShedDefrosters m1 : 13|1@1+ (1,0) [0|1] ""  gtw
 SG_ VCFRONT_loadShedBlower_duty m1 : 6|7@1+ (1,0) [0|100] "%"  gtw
 SG_ VCFRONT_loadShed12VAuxLoads m1 : 5|1@1+ (1,0) [0|1] ""  gtw
 SG_ VCFRONT_loadShedAmplifier m1 : 4|1@1+ (1,0) [0|1] ""  gtw
 SG_ VCFRONT_loadShedFSeatHeaters m1 : 3|1@1+ (1,0) [0|1] ""  gtw
 SG_ VCFRONT_vcleftCurrent m0 : 1|12@1+ (0.05,0) [0|204.7] "A"  gtw
 SG_ VCFRONT_loadShedSMState m1 : 1|2@1+ (1,0) [0|3] ""  gtw
 SG_ VCFRONT_systemStatusMuxIndex M : 0|1@1+ (1,0) [0|1] ""  X

BO_ 1932 EPBR_xcpResponse: 8 VEH
 SG_ EPBR_xcpResponse : 7|64@0+ (1,0) [0|18446744073709551615] ""  X

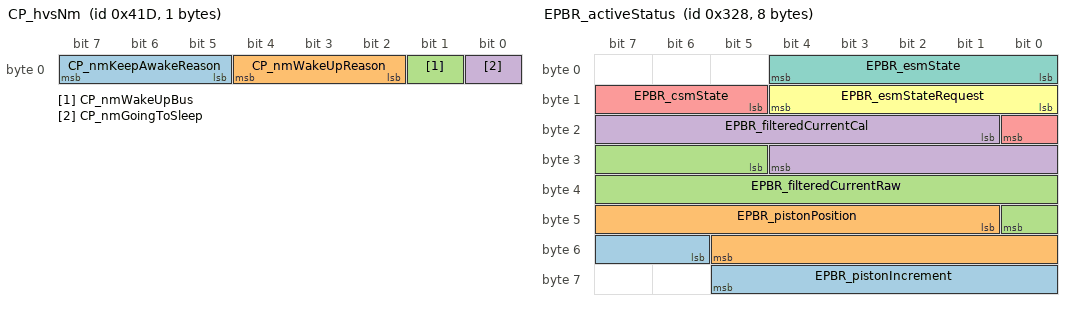
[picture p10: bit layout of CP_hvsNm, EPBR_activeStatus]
BO_ 1053 CP_hvsNm: 1 VEH
 SG_ CP_nmKeepAwakeReason : 5|3@1+ (1,0) [0|4] ""  dbg
 SG_ CP_nmWakeUpReason : 2|3@1+ (1,0) [0|4] ""  dbg
 SG_ CP_nmWakeUpBus : 1|1@1+ (1,0) [0|1] ""  dbg
 SG_ CP_nmGoingToSleep : 0|1@1+ (1,0) [0|1] ""  dbg

BO_ 1793 VCFRONT_debugThermal10Hz: 6 VEH
 SG_ VCFRONT_coolantNoFlowFaultPT m2 : 40|1@1+ (1,0) [0|1] ""  X
 SG_ VCFRONT_coolantNoFlowReqPT m2 : 39|1@1+ (1,0) [0|1] ""  X
 SG_ VCFRONT_coolantFlowPTMax m2 : 30|9@1+ (0.1,0) [0|40] "LPM"  X
 SG_ VCFRONT_coolantNoFlowFaultBat m2 : 29|1@1+ (1,0) [0|1] ""  X
 SG_ VCFRONT_coolantNoFlowReqBat m2 : 28|1@1+ (1,0) [0|1] ""  X
 SG_ VCFRONT_solenoidEvapCurrent m4 : 24|6@1+ (0.04,0) [0|2.4] "A"  X
 SG_ VCFRONT_radiatorFanFault m3 : 24|1@1+ (1,0) [0|1] ""  X
 SG_ VCFRONT_pumpPowertrainFault m1 : 24|1@1+ (1,0) [0|1] ""  X
 SG_ VCFRONT_pumpBatteryFault m0 : 24|1@1+ (1,0) [0|1] ""  X
 SG_ VCFRONT_solenoidEvapPowerApplied m4 : 20|1@1+ (1,0) [0|1] ""  X
 SG_ VCFRONT_coolantFlowBatMax m2 : 19|9@1+ (0.1,0) [0|40] "LPM"  X
 SG_ VCFRONT_exvMotorHasCommError m4 : 19|1@1+ (1,0) [0|1] ""  X
 SG_ VCFRONT_fiveWayValveStall m2 : 18|1@1+ (1,0) [0|1] ""  X
 SG_ VCFRONT_exvMotorIsCoilShortYNVbb m4 : 18|1@1+ (1,0) [0|1] ""  X
 SG_ VCFRONT_fiveWayValveNoTravel m2 : 17|1@1+ (1,0) [0|1] ""  X
 SG_ VCFRONT_exvMotorIsCoilShortYNGnd m4 : 17|1@1+ (1,0) [0|1] ""  X
 SG_ VCFRONT_pumpBatteryITerm m0 : 16|8@1+ (0.005,-0.6) [-0.6|0.6] "Nm"  X
 SG_ VCFRONT_fiveWayValveOverTravel m2 : 16|1@1+ (1,0) [0|1] ""  X
 SG_ VCFRONT_pumpPowertrainITerm m1 : 16|8@1+ (0.005,-0.6) [-0.6|0.6] "Nm"  X
 SG_ VCFRONT_radiatorFanITerm m3 : 16|8@1+ (0.025,-1.5) [-1.5|4.5] "Nm"  X
 SG_ VCFRONT_exvMotorIsCoilShortYPVbb m4 : 16|1@1+ (1,0) [0|1] ""  X
 SG_ VCFRONT_exvMotorIsCoilShortYPGnd m4 : 15|1@1+ (1,0) [0|1] ""  X
 SG_ VCFRONT_fiveWayValveUnderTravel m2 : 15|1@1+ (1,0) [0|1] ""  X
 SG_ VCFRONT_exvMotorIsCoilShortXNVbb m4 : 14|1@1+ (1,0) [0|1] ""  X
 SG_ VCFRONT_exvMotorIsCoilShortXNGnd m4 : 13|1@1+ (1,0) [0|1] ""  X
 SG_ VCFRONT_exvMotorIsCoilShortXPVbb m4 : 12|1@1+ (1,0) [0|1] ""  X
 SG_ VCFRONT_exvMotorIsCoilShortXPGnd m4 : 11|1@1+ (1,0) [0|1] ""  X
 SG_ VCFRONT_exvMotorIsCoilOpenY m4 : 10|1@1+ (1,0) [0|1] ""  X
 SG_ VCFRONT_exvMotorIsCoilOpenX m4 : 9|1@1+ (1,0) [0|1] ""  X
 SG_ VCFRONT_pumpPowertrainOutputDuty m1 : 8|7@1+ (1,0) [0|100] "%"  X
 SG_ VCFRONT_radiatorFanOutputDuty m3 : 8|7@1+ (1,0) [0|100] "%"  X
 SG_ VCFRONT_exvMotorThermalShutdown m4 : 8|1@1+ (1,0) [0|1] ""  X
 SG_ VCFRONT_pumpBatteryOutputDuty m0 : 8|7@1+ (1,0) [0|100] "%"  X
 SG_ VCFRONT_exvMotorThermalWarn m4 : 7|1@1+ (1,0) [0|1] ""  X
 SG_ VCFRONT_exvMotorWasHardReset m4 : 6|1@1+ (1,0) [0|1] ""  X
 SG_ VCFRONT_exvMotorDirection m4 : 5|1@1+ (1,0) [0|1] ""  X
 SG_ VCFRONT_exvMotorIsMoving m4 : 4|1@1+ (1,0) [0|1] ""  X
 SG_ VCFRONT_fiveWayValveMotorCounts m2 : 4|11@1+ (1,-1000) [-1000|1000] "ticks"  X
 SG_ VCFRONT_fiveWayValveAtTarget m2 : 3|1@1+ (1,0) [0|1] ""  X
 SG_ VCFRONT_exvMotorIsEnabled m4 : 3|1@1+ (1,0) [0|1] ""  X
 SG_ VCFRONT_debugThermal10HzIndex M : 0|3@1+ (1,0) [0|5] ""  X

BO_ 1863 DBG_DI_vdcControl: 1 VEH
 SG_ DBG_DI_vdcDebugEnable : 0|1@1+ (1,0) [0|1] ""  di

BO_ 1541 UDS_disRequest: 8 VEH
 SG_ UDS_disRequestData : 7|64@0+ (1,0) [0|18446744073709551615] ""  dis

BO_ 1537 VCFRONT_udsResponse: 8 VEH
 SG_ VCFRONT_udsResponseData : 7|64@0+ (1,0) [0|18446744073709551615] ""  gtw

BO_ 808 EPBR_activeStatus: 8 VEH
 SG_ EPBR_pistonIncrement : 54|8@1- (0.05,2.0) [0|4] "vCounts"  X
 SG_ EPBR_pistonPosition : 41|13@1- (9.768009768009769,0.0) [-20000|20000] "vCounts"  X
 SG_ EPBR_filteredCurrentRaw : 29|12@1+ (0.01,0) [0|40.95] "A"  gtw
 SG_ EPBR_filteredCurrentCal : 17|12@1+ (0.01,0) [0|40.95] "A"  gtw
 SG_ EPBR_csmState : 13|4@1+ (1,0) [0|14] ""  gtw
 SG_ EPBR_esmStateRequest : 8|5@1+ (1,0) [0|19] ""  gtw
 SG_ EPBR_esmState : 0|5@1+ (1,0) [0|19] ""  gtw

BO_ 1539 UDS_cmpRequest: 8 VEH
 SG_ UDS_cmpRequestData : 7|64@0+ (1,0) [0|18446744073709551615] ""  cmp

BO_ 1017 VCSEC_alertMatrix: 8 VEH
 SG_ VCSEC_a180_wlistRemovedPermissio m2 : 63|1@1+ (1,0) [0|1] ""  gtw
 SG_ VCSEC_a120_DI_DRIVE_MIA m1 : 63|1@1+ (1,0) [0|1] ""  gtw
 SG_ VCSEC_a060_engineeringBuild m0 : 63|1@1+ (1,0) [0|1] ""  gtw
 SG_ VCSEC_a179_wlistAddedPermission m2 : 62|1@1+ (1,0) [0|1] ""  gtw
 SG_ VCSEC_a119_SCCM_MIA m1 : 62|1@1+ (1,0) [0|1] ""  gtw
 SG_ VCSEC_a059_inputResistanceHigh m0 : 62|1@1+ (1,0) [0|1] ""  gtw
 SG_ VCSEC_a178_whitelistRemovedKey m2 : 61|1@1+ (1,0) [0|1] ""  gtw
 SG_ VCSEC_a118_VCFRONT_MIA m1 : 61|1@1+ (1,0) [0|1] ""  gtw
 SG_ VCSEC_a177_whitelistAddedKey m2 : 60|1@1+ (1,0) [0|1] ""  gtw
 SG_ VCSEC_a117_VCLEFT_MIA m1 : 60|1@1+ (1,0) [0|1] ""  gtw
 SG_ VCSEC_a116_VCRIGHT_MIA m1 : 59|1@1+ (1,0) [0|1] ""  gtw
 SG_ VCSEC_a175_BLEUnexpectedResetRe m2 : 58|1@1+ (1,0) [0|1] ""  gtw
 SG_ VCSEC_a115_VCSEC_MIA m1 : 58|1@1+ (1,0) [0|1] ""  gtw
 SG_ VCSEC_a114_ESP_MIA m1 : 57|1@1+ (1,0) [0|1] ""  gtw
 SG_ VCSEC_a174_BLEUnexpectedResetRi m2 : 57|1@1+ (1,0) [0|1] ""  gtw
 SG_ VCSEC_a173_BLEUnexpectedResetL m2 : 56|1@1+ (1,0) [0|1] ""  gtw
 SG_ VCSEC_a113_UI_MIA m1 : 56|1@1+ (1,0) [0|1] ""  gtw
 SG_ VCSEC_a172_BLEUnexpectedResetC m2 : 55|1@1+ (1,0) [0|1] ""  gtw
 SG_ VCSEC_a112_EPBL_MIA m1 : 55|1@1+ (1,0) [0|1] ""  gtw
 SG_ VCSEC_a111_EPBR_MIA m1 : 54|1@1+ (1,0) [0|1] ""  gtw
 SG_ VCSEC_a170_BLERearSoftReset m2 : 53|1@1+ (1,0) [0|1] ""  gtw
 SG_ VCSEC_a110_GTW_MIA m1 : 53|1@1+ (1,0) [0|1] ""  gtw
 SG_ VCSEC_a169_BLERightSoftReset m2 : 52|1@1+ (1,0) [0|1] ""  gtw
 SG_ VCSEC_a109_RCM_MIA m1 : 52|1@1+ (1,0) [0|1] ""  gtw
 SG_ VCSEC_a108_DIS_MIA m1 : 51|1@1+ (1,0) [0|1] ""  gtw
 SG_ VCSEC_a168_BLELeftSoftReset m2 : 51|1@1+ (1,0) [0|1] ""  gtw
 SG_ VCSEC_a107_BMS_MIA m1 : 50|1@1+ (1,0) [0|1] ""  gtw
 SG_ VCSEC_a167_BLECenterSoftReset m2 : 50|1@1+ (1,0) [0|1] ""  gtw
 SG_ VCSEC_a046_Task1000msError m0 : 49|1@1+ (1,0) [0|1] ""  gtw
 SG_ VCSEC_a166_BLECenterPowerCycled m2 : 49|1@1+ (1,0) [0|1] ""  gtw
 SG_ VCSEC_a106_PCS_MIA m1 : 49|1@1+ (1,0) [0|1] ""  gtw
 SG_ VCSEC_a105_TAS_MIA m1 : 48|1@1+ (1,0) [0|1] ""  gtw
 SG_ VCSEC_a045_Task100msError m0 : 48|1@1+ (1,0) [0|1] ""  gtw
 SG_ VCSEC_a165_ephemeralKeyGenerated m2 : 48|1@1+ (1,0) [0|1] ""  gtw
 SG_ VCSEC_a164_attrsWentMissingC m2 : 47|1@1+ (1,0) [0|1] ""  gtw
 SG_ VCSEC_a044_Task10msError m0 : 47|1@1+ (1,0) [0|1] ""  gtw
 SG_ VCSEC_a104_DAS_MIA m1 : 47|1@1+ (1,0) [0|1] ""  gtw
 SG_ VCSEC_a103_CP_MIA m1 : 46|1@1+ (1,0) [0|1] ""  gtw
 SG_ VCSEC_a043_Task1msError m0 : 46|1@1+ (1,0) [0|1] ""  gtw
 SG_ VCSEC_a102_PTC_MIA m1 : 45|1@1+ (1,0) [0|1] ""  gtw
 SG_ VCSEC_a162_hciFaultRe m2 : 45|1@1+ (1,0) [0|1] ""  gtw
 SG_ VCSEC_a042_HighStackUsage m0 : 45|1@1+ (1,0) [0|1] ""  gtw
 SG_ VCSEC_a101_PM_MIA m1 : 44|1@1+ (1,0) [0|1] ""  gtw
 SG_ VCSEC_a161_hciFaultR m2 : 44|1@1+ (1,0) [0|1] ""  gtw
 SG_ VCSEC_a041_HighCPULoad m0 : 44|1@1+ (1,0) [0|1] ""  gtw
 SG_ VCSEC_a100_CANbus_MIA m1 : 43|1@1+ (1,0) [0|1] ""  gtw
 SG_ VCSEC_a099_PARK_MIA m1 : 42|1@1+ (1,0) [0|1] ""  gtw
 SG_ VCSEC_a159_hciFaultL m2 : 42|1@1+ (1,0) [0|1] ""  gtw
 SG_ VCSEC_a158_hciFaultC m2 : 41|1@1+ (1,0) [0|1] ""  gtw
 SG_ VCSEC_a098_DI_THERMAL_MIA m1 : 41|1@1+ (1,0) [0|1] ""  gtw
 SG_ VCSEC_a097_CMP_MIA m1 : 40|1@1+ (1,0) [0|1] ""  gtw
 SG_ VCSEC_a156_srvcCmdTimeoutRe m2 : 39|1@1+ (1,0) [0|1] ""  gtw
 SG_ VCSEC_a155_srvcCmdTimeoutR m2 : 38|1@1+ (1,0) [0|1] ""  gtw
 SG_ VCSEC_a154_srvcCmdTimeoutL m2 : 37|1@1+ (1,0) [0|1] ""  gtw
 SG_ VCSEC_a153_srvcCmdTimeoutC m2 : 36|1@1+ (1,0) [0|1] ""  gtw
 SG_ VCSEC_a151_attrsWentMissingRe m2 : 34|1@1+ (1,0) [0|1] ""  gtw
 SG_ VCSEC_a031_UDSActive m0 : 34|1@1+ (1,0) [0|1] ""  gtw
 SG_ VCSEC_a030_ECULogUploadRequest m0 : 33|1@1+ (1,0) [0|1] ""  gtw
 SG_ VCSEC_a210_keyDeviceBatteryLow m3 : 33|1@1+ (1,0) [0|1] ""  gtw
 SG_ VCSEC_a150_attrsWentMissingR m2 : 33|1@1+ (1,0) [0|1] ""  gtw
 SG_ VCSEC_a149_attrsWentMissingL m2 : 32|1@1+ (1,0) [0|1] ""  gtw
 SG_ VCSEC_a209_BLECenterAssertFailur m3 : 32|1@1+ (1,0) [0|1] ""  gtw
 SG_ VCSEC_a208_BLERearAssertFailure m3 : 31|1@1+ (1,0) [0|1] ""  gtw
 SG_ VCSEC_a148_keyWhitelistFull m2 : 31|1@1+ (1,0) [0|1] ""  gtw
 SG_ VCSEC_a207_BLERightAssertFailure m3 : 30|1@1+ (1,0) [0|1] ""  gtw
 SG_ VCSEC_a147_protobufRXTimeout m2 : 30|1@1+ (1,0) [0|1] ""  gtw
 SG_ VCSEC_a206_BLELeftAssertFailure m3 : 29|1@1+ (1,0) [0|1] ""  gtw
 SG_ VCSEC_a205_MTUUpdateNotConfirmed m3 : 28|1@1+ (1,0) [0|1] ""  gtw
 SG_ VCSEC_a145_bleGattAlertRe m2 : 28|1@1+ (1,0) [0|1] ""  gtw
 SG_ VCSEC_a144_bleGattAlertR m2 : 27|1@1+ (1,0) [0|1] ""  gtw
 SG_ VCSEC_a204_SharedSecretsWritten m3 : 27|1@1+ (1,0) [0|1] ""  gtw
 SG_ VCSEC_a203_rearEndpointLostComm m3 : 26|1@1+ (1,0) [0|1] ""  gtw
 SG_ VCSEC_a143_bleGattAlertL m2 : 26|1@1+ (1,0) [0|1] ""  gtw
 SG_ VCSEC_a022_TaskInitError m0 : 25|1@1+ (1,0) [0|1] ""  gtw
 SG_ VCSEC_a142_bleGattAlertC m2 : 25|1@1+ (1,0) [0|1] ""  gtw
 SG_ VCSEC_a202_rightEndpointLostComm m3 : 25|1@1+ (1,0) [0|1] ""  gtw
 SG_ VCSEC_a021_TaskSchedulerError m0 : 24|1@1+ (1,0) [0|1] ""  gtw
 SG_ VCSEC_a141_tooFewKeysOnWhitelist m2 : 24|1@1+ (1,0) [0|1] ""  gtw
 SG_ VCSEC_a201_leftEndpointLostComm m3 : 24|1@1+ (1,0) [0|1] ""  gtw
 SG_ VCSEC_a200_centerEndpointLostCom m3 : 23|1@1+ (1,0) [0|1] ""  gtw
 SG_ VCSEC_a140_nfcAuthentication m2 : 23|1@1+ (1,0) [0|1] ""  gtw
 SG_ VCSEC_a199_CenterNFCReaderMIA m3 : 22|1@1+ (1,0) [0|1] ""  gtw
 SG_ VCSEC_a138_rearEndpointMIA m2 : 21|1@1+ (1,0) [0|1] ""  gtw
 SG_ VCSEC_a198_BPillarNFCReaderMIA m3 : 21|1@1+ (1,0) [0|1] ""  gtw
 SG_ VCSEC_a197_indicationFault m3 : 20|1@1+ (1,0) [0|1] ""  gtw
 SG_ VCSEC_a137_rightEndpointMIA m2 : 20|1@1+ (1,0) [0|1] ""  gtw
 SG_ VCSEC_a136_leftEndpointMIA m2 : 19|1@1+ (1,0) [0|1] ""  gtw
 SG_ VCSEC_a196_protobufTXTimeout m3 : 19|1@1+ (1,0) [0|1] ""  gtw
 SG_ VCSEC_a015_NVMMAlert m0 : 18|1@1+ (1,0) [0|1] ""  gtw
 SG_ VCSEC_a195_keyMissingInDrive m3 : 18|1@1+ (1,0) [0|1] ""  gtw
 SG_ VCSEC_a135_centerEndpointMIA m2 : 18|1@1+ (1,0) [0|1] ""  gtw
 SG_ VCSEC_a194_macIDWlistingFailedRe m3 : 17|1@1+ (1,0) [0|1] ""  gtw
 SG_ VCSEC_a134_badCertificate m2 : 17|1@1+ (1,0) [0|1] ""  gtw
 SG_ VCSEC_a133_alarmTriggered m2 : 16|1@1+ (1,0) [0|1] ""  gtw
 SG_ VCSEC_a013_AlertManagerFault m0 : 16|1@1+ (1,0) [0|1] ""  gtw
 SG_ VCSEC_a193_macIDWlistingFailedRi m3 : 16|1@1+ (1,0) [0|1] ""  gtw
 SG_ VCSEC_a012_CPUReset m0 : 15|1@1+ (1,0) [0|1] ""  gtw
 SG_ VCSEC_a192_macIDWlistingFailedL m3 : 15|1@1+ (1,0) [0|1] ""  gtw
 SG_ VCSEC_a191_macIDWlistingFailedC m3 : 14|1@1+ (1,0) [0|1] ""  gtw
 SG_ VCSEC_a190_protoTooManyBytes m3 : 13|1@1+ (1,0) [0|1] ""  gtw
 SG_ VCSEC_a010_ExtSupplyVoltError m0 : 13|1@1+ (1,0) [0|1] ""  gtw
 SG_ VCSEC_a189_protoExpLengthTooLarg m3 : 12|1@1+ (1,0) [0|1] ""  gtw
 SG_ VCSEC_a188_protobufDecodeError m3 : 11|1@1+ (1,0) [0|1] ""  gtw
 SG_ VCSEC_a187_badConnectionDropped m3 : 10|1@1+ (1,0) [0|1] ""  gtw
 SG_ VCSEC_a186_rearEndpointRFMia m3 : 9|1@1+ (1,0) [0|1] ""  gtw
 SG_ VCSEC_a185_passengerEndpointRFMi m3 : 8|1@1+ (1,0) [0|1] ""  gtw
 SG_ VCSEC_a184_driverEndpointRFMia m3 : 7|1@1+ (1,0) [0|1] ""  gtw
 SG_ VCSEC_a064_busSleepReqTimeout m1 : 7|1@1+ (1,0) [0|1] ""  gtw
 SG_ VCSEC_a183_centerEndpointRFMia m3 : 6|1@1+ (1,0) [0|1] ""  gtw
 SG_ VCSEC_a003_SWAssertion m0 : 6|1@1+ (1,0) [0|1] ""  gtw
 SG_ VCSEC_a063_SwitchFault m1 : 6|1@1+ (1,0) [0|1] ""  gtw
 SG_ VCSEC_a062_XCPWasConnected m1 : 5|1@1+ (1,0) [0|1] ""  gtw
 SG_ VCSEC_a002_PowerLossReset m0 : 5|1@1+ (1,0) [0|1] ""  gtw
 SG_ VCSEC_a182_cryptoHighStackUsage m3 : 5|1@1+ (1,0) [0|1] ""  gtw
 SG_ VCSEC_a001_WatchdogReset m0 : 4|1@1+ (1,0) [0|1] ""  gtw
 SG_ VCSEC_a181_signedMessageFault m3 : 4|1@1+ (1,0) [0|1] ""  gtw
 SG_ VCSEC_a061_XCPConnected m1 : 4|1@1+ (1,0) [0|1] ""  gtw
 SG_ VCSEC_matrixIndex M : 0|4@1+ (1,0) [0|15] ""  gtw

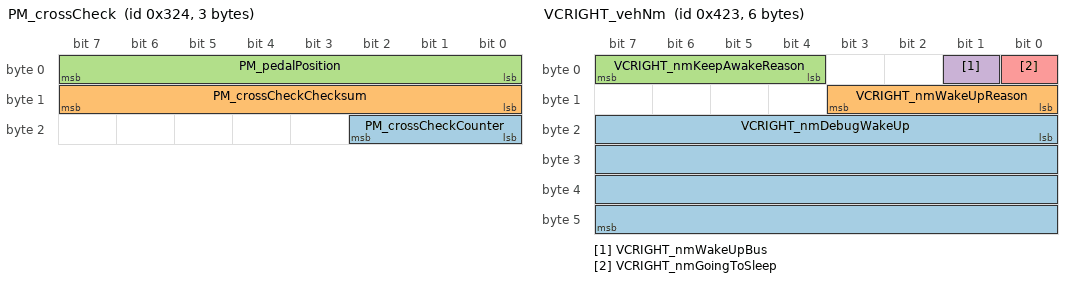
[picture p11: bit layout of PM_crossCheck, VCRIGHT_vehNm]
BO_ 804 PM_crossCheck: 3 VEH
 SG_ PM_crossCheckCounter : 16|3@1+ (1,0) [0|7] ""  X
 SG_ PM_crossCheckChecksum : 8|8@1+ (1,0) [0|255] ""  X
 SG_ PM_pedalPosition : 0|8@1+ (0.4,0) [0|100] "%"  di

BO_ 1604 UDS_pmsRequest: 8 VEH
 SG_ UDS_pmsRequestData : 7|64@0+ (1,0) [0|18446744073709551615] ""  pms

BO_ 1059 VCRIGHT_vehNm: 6 VEH
 SG_ VCRIGHT_nmDebugWakeUp : 16|32@1+ (1,0) [0|4294967295] ""  gtw
 SG_ VCRIGHT_nmWakeUpReason : 8|4@1+ (1,0) [0|15] ""  gtw
 SG_ VCRIGHT_nmKeepAwakeReason : 4|4@1+ (1,0) [0|15] ""  gtw
 SG_ VCRIGHT_nmWakeUpBus : 1|1@1+ (1,0) [0|1] ""  X
 SG_ VCRIGHT_nmGoingToSleep : 0|1@1+ (1,0) [0|1] ""  X

BO_ 1825 VCFRONT_debugThermal1Hz: 8 VEH
 SG_ VCFRONT_fanRadStatDiagFail m4 : 62|1@1+ (1,0) [0|1] ""  X
 SG_ VCFRONT_fanRadStatSPIFail m4 : 61|1@1+ (1,0) [0|1] ""  X
 SG_ VCFRONT_fanRadStatOTPAny m4 : 60|1@1+ (1,0) [0|1] ""  X
 SG_ VCFRONT_fanRadStatMode m4 : 58|2@1+ (1,0) [0|3] ""  X
 SG_ VCFRONT_fanRadPwmInputFault m4 : 57|1@1+ (1,0) [0|1] ""  X
 SG_ VCFRONT_passiveDemandLouver m3 : 56|7@1+ (1,0) [0|100] "%"  X
 SG_ VCFRONT_fanRadVccUnderVoltage m4 : 56|1@1+ (1,0) [0|1] ""  X
 SG_ VCFRONT_activeDemandChiller m0 : 55|7@1+ (1,0) [0|127] "%"  X
 SG_ VCFRONT_fanRadLossOfSpeedLock m4 : 55|1@1+ (1,0) [0|1] ""  X
 SG_ VCFRONT_fanRadStartUpOperation m4 : 54|1@1+ (1,0) [0|1] ""  X
 SG_ VCFRONT_fanRadWatchdogTimeout m4 : 53|1@1+ (1,0) [0|1] ""  X
 SG_ VCFRONT_fanRadJunctionOverTemp m4 : 52|1@1+ (1,0) [0|1] ""  X
 SG_ VCFRONT_fanRadJunctionTempWarn m4 : 51|1@1+ (1,0) [0|1] ""  X
 SG_ VCFRONT_fanRadLockedRotor m4 : 50|1@1+ (1,0) [0|1] ""  X
 SG_ VCFRONT_fanRadThOverTemperature m4 : 49|1@1+ (1,0) [0|1] ""  X
 SG_ VCFRONT_activeDemandFanRad m0 : 48|7@1+ (1,0) [0|127] "%"  X
 SG_ VCFRONT_fanRadFetShortCircuit m4 : 48|1@1+ (1,0) [0|1] ""  X
 SG_ VCFRONT_passiveDemandRadBypass m3 : 48|7@1+ (1,0) [0|100] "%"  X
 SG_ VCFRONT_fanRadVglUnderVoltage m4 : 47|1@1+ (1,0) [0|1] ""  X
 SG_ VCFRONT_fanRadChpUnderVoltage m4 : 46|1@1+ (1,0) [0|1] ""  X
 SG_ VCFRONT_fanRadVsOverVoltage m4 : 45|1@1+ (1,0) [0|1] ""  X
 SG_ VCFRONT_fanRadVsUnderVoltage m4 : 44|1@1+ (1,0) [0|1] ""  X
 SG_ VCFRONT_fanRadOverCurrentError m4 : 43|1@1+ (1,0) [0|1] ""  X
 SG_ VCFRONT_pumpPtStatDiagFail m4 : 42|1@1+ (1,0) [0|1] ""  X
 SG_ VCFRONT_activeDemandPumpBatt m0 : 41|7@1+ (1,0) [0|127] "%"  X
 SG_ VCFRONT_pumpPtStatSPIFail m4 : 41|1@1+ (1,0) [0|1] ""  X
 SG_ VCFRONT_pumpPtStatOTPAny m4 : 40|1@1+ (1,0) [0|1] ""  X
 SG_ VCFRONT_passiveDemandPumpBatt m3 : 40|7@1+ (1,0) [0|100] "%"  X
 SG_ VCFRONT_pumpPtStatMode m4 : 38|2@1+ (1,0) [0|3] ""  X
 SG_ VCFRONT_pumpPtPwmInputFault m4 : 37|1@1+ (1,0) [0|1] ""  X
 SG_ VCFRONT_pumpPtVccUnderVoltage m4 : 36|1@1+ (1,0) [0|1] ""  X
 SG_ VCFRONT_pumpPtLossOfSpeedLock m4 : 35|1@1+ (1,0) [0|1] ""  X
 SG_ VCFRONT_pumpPtStartUpOperation m4 : 34|1@1+ (1,0) [0|1] ""  X
 SG_ VCFRONT_activeDemandPumpPT m0 : 34|7@1+ (1,0) [0|127] "%"  X
 SG_ VCFRONT_pumpPtWatchdogTimeout m4 : 33|1@1+ (1,0) [0|1] ""  X
 SG_ VCFRONT_activeParallelBattRegOn m0 : 33|1@1+ (1,0) [0|1] ""  X
 SG_ VCFRONT_condenserMinLouverReq m5 : 32|7@1+ (1,0) [0|100] "%"  X
 SG_ VCFRONT_activeParallelPTRegOn m0 : 32|1@1+ (1,0) [0|1] ""  X
 SG_ VCFRONT_passiveDemandPumpPT m3 : 32|7@1+ (1,0) [0|100] "%"  X
 SG_ VCFRONT_pumpPtJunctionOverTemp m4 : 32|1@1+ (1,0) [0|1] ""  X
 SG_ VCFRONT_activeSeriesRegOn m0 : 31|1@1+ (1,0) [0|1] ""  X
 SG_ VCFRONT_pumpPtJunctionTempWarn m4 : 31|1@1+ (1,0) [0|1] ""  X
 SG_ VCFRONT_pumpPtLockedRotor m4 : 30|1@1+ (1,0) [0|1] ""  X
 SG_ VCFRONT_pumpPtThOverTemperature m4 : 29|1@1+ (1,0) [0|1] ""  X
 SG_ VCFRONT_pumpPtFetShortCircuit m4 : 28|1@1+ (1,0) [0|1] ""  X
 SG_ VCFRONT_pumpPtVglUnderVoltage m4 : 27|1@1+ (1,0) [0|1] ""  X
 SG_ VCFRONT_pumpPtChpUnderVoltage m4 : 26|1@1+ (1,0) [0|1] ""  X
 SG_ VCFRONT_passiveParallelPTRegMaxd m3 : 26|1@1+ (1,0) [0|1] ""  X
 SG_ VCFRONT_passiveSeriesRegMaxd m3 : 25|1@1+ (1,0) [0|1] ""  X
 SG_ VCFRONT_pumpPtVsOverVoltage m4 : 25|1@1+ (1,0) [0|1] ""  X
 SG_ VCFRONT_passiveParallelPTRegOn m3 : 24|1@1+ (1,0) [0|1] ""  X
 SG_ VCFRONT_pumpPtVsUnderVoltage m4 : 24|1@1+ (1,0) [0|1] ""  X
 SG_ VCFRONT_condenserMinFanReq m5 : 24|7@1+ (1,0) [0|100] "%"  X
 SG_ VCFRONT_activeParallelBattReg m0 : 24|7@1+ (1,0) [0|127] "%"  X
 SG_ VCFRONT_passiveSeriesRegOn m3 : 23|1@1+ (1,0) [0|1] ""  X
 SG_ VCFRONT_pumpPtOverCurrentError m4 : 23|1@1+ (1,0) [0|1] ""  X
 SG_ VCFRONT_pumpBatStatDiagFail m4 : 22|1@1+ (1,0) [0|1] ""  X
 SG_ VCFRONT_pumpBatStatSPIFail m4 : 21|1@1+ (1,0) [0|1] ""  X
 SG_ VCFRONT_pumpBatStatOTPAny m4 : 20|1@1+ (1,0) [0|1] ""  X
 SG_ VCFRONT_pumpBatStatMode m4 : 18|2@1+ (1,0) [0|3] ""  X
 SG_ VCFRONT_condenserRegDemand m5 : 17|7@1+ (1,0) [0|100] "%"  X
 SG_ VCFRONT_pumpBatPwmInputFault m4 : 17|1@1+ (1,0) [0|1] ""  X
 SG_ VCFRONT_pumpBatVccUnderVoltage m4 : 16|1@1+ (1,0) [0|1] ""  X
 SG_ VCFRONT_activeParallelPTReg m0 : 16|7@1+ (1,0) [0|127] "%"  X
 SG_ VCFRONT_activeLouverBrakeEngaged m1 : 16|1@1+ (1,0) [0|1] ""  X
 SG_ VCFRONT_passiveParallelPTReg m3 : 16|7@1+ (1,0) [0|100] "%"  X
 SG_ VCFRONT_condenserFeedfwdForEvap m5 : 16|1@1+ (1,0) [0|1] ""  X
 SG_ VCFRONT_condenserFeedfwdForChill m5 : 15|1@1+ (1,0) [0|1] ""  X
 SG_ VCFRONT_pumpBatLossOfSpeedLock m4 : 15|1@1+ (1,0) [0|1] ""  X
 SG_ VCFRONT_activeLouverDirection m1 : 15|1@1+ (1,0) [0|1] ""  X
 SG_ VCFRONT_condenserActivePID m5 : 14|1@1+ (1,0) [0|1] ""  X
 SG_ VCFRONT_pumpBatStartUpOperation m4 : 14|1@1+ (1,0) [0|1] ""  X
 SG_ VCFRONT_pumpBatWatchdogTimeout m4 : 13|1@1+ (1,0) [0|1] ""  X
 SG_ VCFRONT_pumpBatJunctionOverTemp m4 : 12|1@1+ (1,0) [0|1] ""  X
 SG_ VCFRONT_pumpBatJunctionTempWarn m4 : 11|1@1+ (1,0) [0|1] ""  X
 SG_ VCFRONT_pumpBatLockedRotor m4 : 10|1@1+ (1,0) [0|1] ""  X
 SG_ VCFRONT_pumpBatThOverTemperature m4 : 9|1@1+ (1,0) [0|1] ""  X
 SG_ VCFRONT_condenserTempLimit m5 : 8|6@1+ (1,80) [80|140] "degC"  X
 SG_ VCFRONT_activeLouverSpeedCmd m1 : 8|7@1+ (1,0) [0|100] "%"  X
 SG_ VCFRONT_pumpBatFetShortCircuit m4 : 8|1@1+ (1,0) [0|1] ""  X
 SG_ VCFRONT_activeSeriesReg m0 : 8|7@1+ (1,0) [0|127] "%"  X
 SG_ VCFRONT_passiveSeriesReg m3 : 8|8@1- (1,0) [-100|100] "%"  X
 SG_ VCFRONT_pumpBatVglUnderVoltage m4 : 7|1@1+ (1,0) [0|1] ""  X
 SG_ VCFRONT_pumpBatChpUnderVoltage m4 : 6|1@1+ (1,0) [0|1] ""  X
 SG_ VCFRONT_pumpBatVsOverVoltage m4 : 5|1@1+ (1,0) [0|1] ""  X
 SG_ VCFRONT_pumpBatVsUnderVoltage m4 : 4|1@1+ (1,0) [0|1] ""  X
 SG_ VCFRONT_modeHysteresisActive m2 : 4|1@1+ (1,0) [0|1] ""  X
 SG_ VCFRONT_pumpBatOverCurrentError m4 : 3|1@1+ (1,0) [0|1] ""  X
 SG_ VCFRONT_modeDesiredPrevious m2 : 3|1@1+ (1,0) [0|1] ""  X
 SG_ VCFRONT_debugThermal1HzIndex M : 0|3@1+ (1,0) [0|6] ""  X

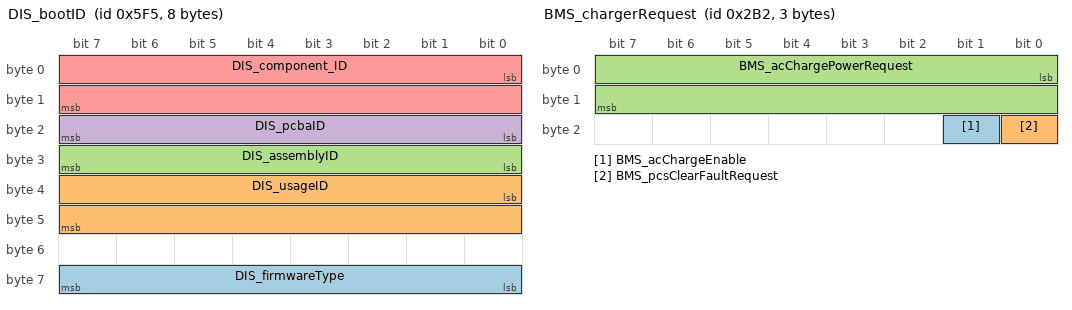
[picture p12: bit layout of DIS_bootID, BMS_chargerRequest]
BO_ 1525 DIS_bootID: 8 VEH
 SG_ DIS_firmwareType : 56|8@1+ (1,0) [0|255] ""  gtwu
 SG_ DIS_usageID : 32|16@1+ (1,0) [0|65535] ""  gtwu
 SG_ DIS_assemblyID : 24|8@1+ (1,0) [0|255] ""  gtwu
 SG_ DIS_pcbaID : 16|8@1+ (1,0) [0|255] ""  gtwu
 SG_ DIS_component_ID : 0|16@1+ (1,0) [0|65535] ""  gtwu

BO_ 1300 FC_serial: 8 VEH
 SG_ FC_serialChar07 m0 : 56|8@1+ (1,0) [0|255] ""  gtw
 SG_ FC_serialChar14 m1 : 56|8@1+ (1,0) [0|255] ""  gtw
 SG_ FC_serialChar13 m1 : 48|8@1+ (1,0) [0|255] ""  gtw
 SG_ FC_serialChar06 m0 : 48|8@1+ (1,0) [0|255] ""  gtw
 SG_ FC_serialChar05 m0 : 40|8@1+ (1,0) [0|255] ""  gtw
 SG_ FC_serialChar12 m1 : 40|8@1+ (1,0) [0|255] ""  gtw
 SG_ FC_serialChar11 m1 : 32|8@1+ (1,0) [0|255] ""  gtw
 SG_ FC_serialChar04 m0 : 32|8@1+ (1,0) [0|255] ""  gtw
 SG_ FC_serialChar03 m0 : 24|8@1+ (1,0) [0|255] ""  gtw
 SG_ FC_serialChar10 m1 : 24|8@1+ (1,0) [0|255] ""  gtw
 SG_ FC_serialChar17 m2 : 24|8@1+ (1,0) [0|255] ""  gtw
 SG_ FC_serialChar09 m1 : 16|8@1+ (1,0) [0|255] ""  gtw
 SG_ FC_serialChar02 m0 : 16|8@1+ (1,0) [0|255] ""  gtw
 SG_ FC_serialChar16 m2 : 16|8@1+ (1,0) [0|255] ""  gtw
 SG_ FC_serialChar15 m2 : 8|8@1+ (1,0) [0|255] ""  gtw
 SG_ FC_serialChar08 m1 : 8|8@1+ (1,0) [0|255] ""  gtw
 SG_ FC_serialChar01 m0 : 8|8@1+ (1,0) [0|255] ""  gtw
 SG_ FC_serialDataSelect M : 0|7@1+ (1,0) [0|2] ""  dbg

BO_ 690 BMS_chargerRequest: 3 VEH
 SG_ BMS_acChargeEnable : 17|1@1+ (1,0) [0|1] ""  X
 SG_ BMS_pcsClearFaultRequest : 16|1@1+ (1,0) [0|1] ""  X
 SG_ BMS_acChargePowerRequest : 0|16@1+ (0.001,0) [0|40] "kW"  gtw

BO_ 1664 UDS_sccmRequest: 8 VEH
 SG_ UDS_sccmRequestData : 7|64@0+ (1,0) [0|18446744073709551615] ""  sccm

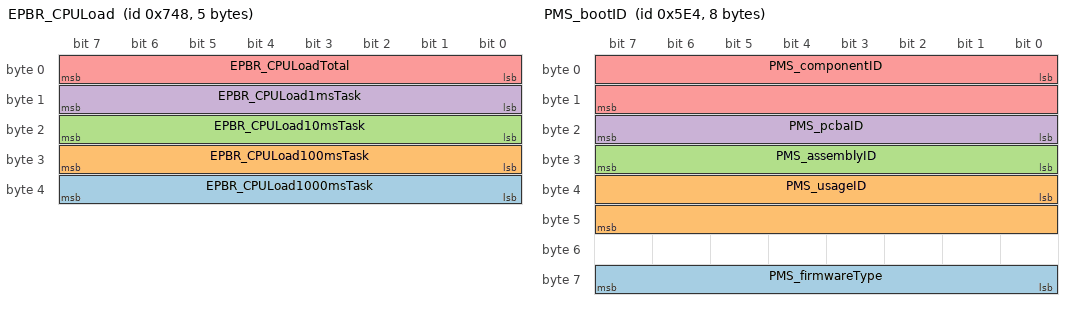
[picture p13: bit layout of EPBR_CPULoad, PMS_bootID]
BO_ 1864 EPBR_CPULoad: 5 VEH
 SG_ EPBR_CPULoad1000msTask : 32|8@1+ (1,0) [0|255] ""  X
 SG_ EPBR_CPULoad100msTask : 24|8@1+ (1,0) [0|255] ""  X
 SG_ EPBR_CPULoad10msTask : 16|8@1+ (1,0) [0|255] ""  X
 SG_ EPBR_CPULoad1msTask : 8|8@1+ (1,0) [0|255] ""  X
 SG_ EPBR_CPULoadTotal : 0|8@1+ (1,0) [0|255] ""  X

BO_ 1812 PM_xcpResponse: 8 VEH
 SG_ PM_xcpResponse : 0|64@1+ (1,0) [0|18446744073709551615] ""  dbg

BO_ 1821 DBG_cpControl: 6 VEH
 SG_ DBG_cp1khzDebugOutput m0 : 40|1@1+ (1,0) [0|1] ""  X
 SG_ DBG_cpLEDDutyWhite m0 : 32|8@1+ (0.39215686275,0) [0|100] "%"  X
 SG_ DBG_cpLatch2MotorDirection m1 : 31|1@1+ (1,0) [0|1] ""  X
 SG_ DBG_cpSWCANRelayActive m4 : 27|1@1+ (1,0) [0|1] ""  X
 SG_ DBG_cpSWCANRelayControlEnable m4 : 26|1@1+ (1,0) [0|1] ""  X
 SG_ DBG_cpGoToSleep m4 : 25|1@1+ (1,0) [0|1] ""  X
 SG_ DBG_cpLatch2HBridgeDuty m1 : 24|7@1+ (1,0) [0|100] "%"  X
 SG_ DBG_cpLEDDutyBlue m0 : 24|8@1+ (0.39215686275,0) [0|100] "%"  X
 SG_ DBG_cpProxEnGBActive m4 : 24|1@1+ (1,0) [0|1] ""  X
 SG_ DBG_cpLatchMotorDirection m1 : 23|1@1+ (1,0) [0|1] ""  X
 SG_ DBG_cpProxEnGBControlEnable m4 : 23|1@1+ (1,0) [0|1] ""  X
 SG_ DBG_cpProxEnGBCC1Active m4 : 22|1@1+ (1,0) [0|1] ""  X
 SG_ DBG_cpProxEnGBCC1ControlEnable m4 : 21|1@1+ (1,0) [0|1] ""  X
 SG_ DBG_cpLatch2EnActive m4 : 20|1@1+ (1,0) [0|1] ""  X
 SG_ DBG_cpLatch2EnControlEnable m4 : 19|1@1+ (1,0) [0|1] ""  X
 SG_ DBG_cpLatchEnActive m4 : 18|1@1+ (1,0) [0|1] ""  X
 SG_ DBG_cpLatchEnControlEnable m4 : 17|1@1+ (1,0) [0|1] ""  X
 SG_ DBG_cpLEDDutyGreen m0 : 16|8@1+ (0.39215686275,0) [0|100] "%"  X
 SG_ DBG_cpLatchHBridgeDuty m1 : 16|7@1+ (1,0) [0|100] "%"  X
 SG_ DBG_cpDoorEnActive m4 : 16|1@1+ (1,0) [0|1] ""  X
 SG_ DBG_cpDoorEnControlEnable m4 : 15|1@1+ (1,0) [0|1] ""  X
 SG_ DBG_latchControlEnable m1 : 15|1@1+ (1,0) [0|1] ""  X
 SG_ DBG_cpLEDEnActive m4 : 14|1@1+ (1,0) [0|1] ""  X
 SG_ DBG_cpLEDEnControlEnable m4 : 13|1@1+ (1,0) [0|1] ""  X
 SG_ DBG_cpProxEnActive m4 : 12|1@1+ (1,0) [0|1] ""  X
 SG_ DBG_cpProxEnControlEnable m4 : 11|1@1+ (1,0) [0|1] ""  X
 SG_ DBG_cpEVSEAcceptActive m4 : 10|1@1+ (1,0) [0|1] ""  X
 SG_ DBG_cpEVSEAcceptControlEnable m4 : 9|1@1+ (1,0) [0|1] ""  X
 SG_ DBG_cpFaultActive m4 : 8|1@1+ (1,0) [0|1] ""  X
 SG_ DBG_cpDoorHeaterDuty m3 : 8|7@1+ (1,0) [0|127] "%"  X
 SG_ DBG_cpDoorHBridgeDuty m1 : 8|7@1+ (1,0) [0|127] "%"  X
 SG_ DBG_cpLEDDutyRed m0 : 8|8@1+ (0.39215686275,0) [0|100] "%"  X
 SG_ DBG_cpFaultControlEnable m4 : 7|1@1+ (1,0) [0|1] ""  X
 SG_ DBG_cp3vActive m4 : 6|1@1+ (1,0) [0|1] ""  X
 SG_ DBG_cp3vControlEnable m4 : 5|1@1+ (1,0) [0|1] ""  X
 SG_ DBG_cpLEDStartSequence m0 : 5|1@1+ (1,0) [0|1] ""  X
 SG_ DBG_cpDoorHeaterControlEnable m3 : 5|1@1+ (1,0) [0|1] ""  X
 SG_ DBG_cpDebugLEDOvrEnable m0 : 4|1@1+ (1,0) [0|1] ""  X
 SG_ DBG_evseRequest m3 : 4|1@1+ (1,0) [0|1] ""  X
 SG_ DBG_cp5vActive m4 : 4|1@1+ (1,0) [0|1] ""  X
 SG_ DBG_cpDoorMotorDirection m1 : 4|1@1+ (1,0) [0|1] ""  X
 SG_ DBG_cpDebugEnable m0 : 3|1@1+ (1,0) [0|1] ""  X
 SG_ DBG_evseRequestControlEnable m3 : 3|1@1+ (1,0) [0|1] ""  X
 SG_ DBG_doorControlEnable m1 : 3|1@1+ (1,0) [0|1] ""  X
 SG_ DBG_cp5vControlEnable m4 : 3|1@1+ (1,0) [0|1] ""  X
 SG_ DBG_CP_debugControls_dataSelect M : 0|3@1+ (1,0) [0|4] ""  X

BO_ 1508 PMS_bootID: 8 VEH
 SG_ PMS_firmwareType : 56|8@1+ (1,0) [0|255] ""  gtwu
 SG_ PMS_usageID : 32|16@1+ (1,0) [0|65535] ""  gtwu
 SG_ PMS_assemblyID : 24|8@1+ (1,0) [0|255] ""  gtwu
 SG_ PMS_pcbaID : 16|8@1+ (1,0) [0|255] ""  gtwu
 SG_ PMS_componentID : 0|16@1+ (1,0) [0|65535] ""  gtwu

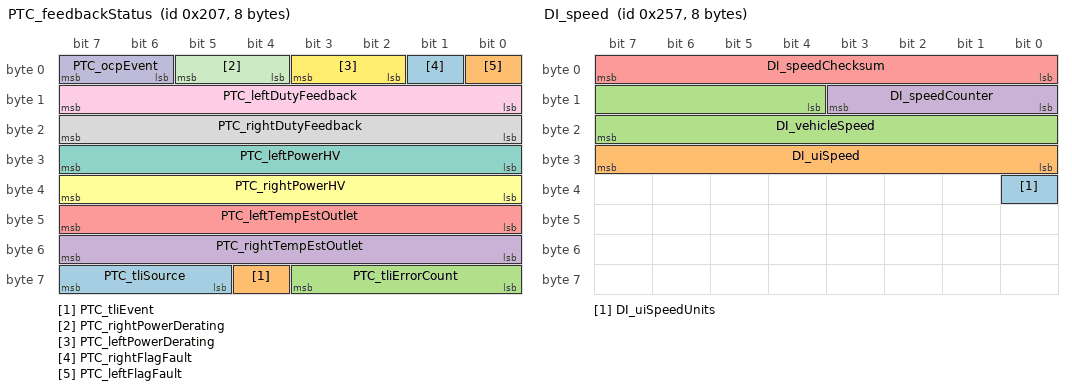
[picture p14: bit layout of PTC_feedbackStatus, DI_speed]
BO_ 519 PTC_feedbackStatus: 8 VEH
 SG_ PTC_tliSource : 61|3@1+ (1,0) [0|4] ""  gtw
 SG_ PTC_tliEvent : 60|1@1+ (1,0) [0|1] ""  gtw
 SG_ PTC_tliErrorCount : 56|4@1+ (1,0) [0|15] ""  gtw
 SG_ PTC_rightTempEstOutlet : 48|8@1+ (1,-40) [-40|200] "degC"  vcright
 SG_ PTC_leftTempEstOutlet : 40|8@1+ (1,-40) [-40|200] "degC"  vcright
 SG_ PTC_rightPowerHV : 32|8@1+ (20,0) [0|5000] "W"  bms
 SG_ PTC_leftPowerHV : 24|8@1+ (20,0) [0|5000] "W"  bms
 SG_ PTC_rightDutyFeedback : 16|8@1+ (0.5,0) [0|100] "%"  vcright
 SG_ PTC_leftDutyFeedback : 8|8@1+ (0.5,0) [0|100] "%"  vcright
 SG_ PTC_ocpEvent : 6|2@1+ (1,0) [0|2] ""  gtw
 SG_ PTC_rightPowerDerating : 4|2@1+ (1,0) [0|3] ""  gtw
 SG_ PTC_leftPowerDerating : 2|2@1+ (1,0) [0|3] ""  gtw
 SG_ PTC_rightFlagFault : 1|1@1+ (1,0) [0|1] ""  gtw
 SG_ PTC_leftFlagFault : 0|1@1+ (1,0) [0|1] ""  gtw

BO_ 769 VCFRONT_info: 8 VEH
 SG_ VCFRONT_infoComponentId m10 : 48|16@1+ (1,0) [0|65535] ""  gtw
 SG_ VCFRONT_infoSubUsageId m11 : 40|16@1+ (1,0) [0|65535] ""  gtw
 SG_ VCFRONT_infoHardwareId m10 : 32|16@1+ (1,0) [0|65535] ""  gtw
 SG_ VCFRONT_hcmrAppCRC m23 : 32|32@1+ (1,0) [0|4294967295] ""  gtw
 SG_ VCFRONT_infoSubcomponent3 m24 : 32|32@1+ (1,0) [0|4294967295] ""  X
 SG_ VCFRONT_hcmlAppCRC m16 : 32|32@1+ (1,0) [0|4294967295] ""  gtw
 SG_ VCFRONT_infoSubcomponent4 m31 : 32|32@1+ (1,0) [0|4294967295] ""  X
 SG_ VCFRONT_infoBootCrc m20 : 24|32@1+ (1,0) [0|4294967295] ""  gtw
 SG_ VCFRONT_infoUsageId m11 : 24|16@1+ (1,0) [0|65535] ""  gtw
 SG_ VCFRONT_infoAssemblyId m11 : 16|8@1+ (1,0) [0|255] ""  gtw
 SG_ VCFRONT_infoBuildConfigId m10 : 16|16@1+ (1,0) [0|65535] ""  gtw
 SG_ VCFRONT_infoBootUdsProtoVersion m20 : 8|16@1+ (1,0) [0|65535] ""  gtw
 SG_ VCFRONT_infoAppGitHash m17 : 8|56@1+ (1,0) [0|72057594037927935] ""  gtw
 SG_ VCFRONT_infoAppCrc m13 : 8|32@1+ (1,0) [0|4294967295] ""  gtw
 SG_ VCFRONT_infoBuildType m10 : 8|3@1+ (1,0) [0|4] ""  gtw
 SG_ VCFRONT_infoBootGitHash m18 : 8|56@1+ (1,0) [0|72057594037927935] ""  gtw
 SG_ VCFRONT_infoPcbaId m11 : 8|8@1+ (1,0) [0|255] ""  gtw
 SG_ VCFRONT_infoPlatformType m19 : 8|8@1+ (1,0) [0|255] ""  gtw
 SG_ VCFRONT_infoIndex M : 0|8@1+ (1,0) [0|255] ""  gtw

BO_ 1566 CP_udsResponse: 8 VEH
 SG_ CP_udsResponseData : 7|64@0+ (1,0) [0|18446744073709551615] ""  gtw

BO_ 599 DI_speed: 8 VEH
 SG_ DI_uiSpeedUnits : 32|1@1+ (1,0) [0|1] ""  das
 SG_ DI_uiSpeed : 24|8@1+ (1,0) [0|254] ""  das
 SG_ DI_vehicleSpeed : 12|12@1+ (0.08,-40) [-40|285] "kph"  epbl
 SG_ DI_speedCounter : 8|4@1+ (1,0) [0|15] ""  X
 SG_ DI_speedChecksum : 0|8@1+ (1,0) [0|255] ""  X

BO_ 797 CC_chgStatus2: 8 VEH
 SG_ CC_buttonState m0 : 8|1@1+ (1,0) [0|1] ""  gtw
 SG_ CC_chgStatus2Index M : 0|8@1+ (1,0) [0|0] ""  X

BO_ 933 DIS_alertMatrix1: 8 VEH
 SG_ DIS_a064_torqueIntervention : 63|1@1+ (1,0) [0|1] ""  gtw
 SG_ DIS_a062_systemLimpMode : 61|1@1+ (1,0) [0|1] ""  gtw
 SG_ DIS_a061_heatsinkSensor : 60|1@1+ (1,0) [0|1] ""  gtw
 SG_ DIS_a060_heatsinkUT : 59|1@1+ (1,0) [0|1] ""  gtw
 SG_ DIS_a059_heatsinkOT : 58|1@1+ (1,0) [0|1] ""  gtw
 SG_ DIS_a058_ambientSensor : 57|1@1+ (1,0) [0|1] ""  gtw
 SG_ DIS_a057_ambientUT : 56|1@1+ (1,0) [0|1] ""  gtw
 SG_ DIS_a056_ambientOT : 55|1@1+ (1,0) [0|1] ""  gtw
 SG_ DIS_a055_trqCrossCheck : 54|1@1+ (1,0) [0|1] ""  gtw
 SG_ DIS_a054_driveInverterOT : 53|1@1+ (1,0) [0|1] ""  gtw
 SG_ DIS_a050_noStatorSensor : 49|1@1+ (1,0) [0|1] ""  gtw
 SG_ DIS_a047_statorSensor1 : 46|1@1+ (1,0) [0|1] ""  gtw
 SG_ DIS_a046_statorOT : 45|1@1+ (1,0) [0|1] ""  gtw
 SG_ DIS_a045_outletSensor : 44|1@1+ (1,0) [0|1] ""  gtw
 SG_ DIS_a044_outletUT : 43|1@1+ (1,0) [0|1] ""  gtw
 SG_ DIS_a043_outletOT : 42|1@1+ (1,0) [0|1] ""  gtw
 SG_ DIS_a042_inletSensor : 41|1@1+ (1,0) [0|1] ""  gtw
 SG_ DIS_a040_disMIA : 39|1@1+ (1,0) [0|1] ""  gtw
 SG_ DIS_a038_busVsensor : 37|1@1+ (1,0) [0|1] ""  gtw
 SG_ DIS_a037_busUV : 36|1@1+ (1,0) [0|1] ""  gtw
 SG_ DIS_a036_busOV : 35|1@1+ (1,0) [0|1] ""  gtw
 SG_ DIS_a035_phaseCurrentBalance : 34|1@1+ (1,0) [0|1] ""  gtw
 SG_ DIS_a034_phaseBcurrentSensor : 33|1@1+ (1,0) [0|1] ""  gtw
 SG_ DIS_a033_phaseAcurrentSensor : 32|1@1+ (1,0) [0|1] ""  gtw
 SG_ DIS_a032_phaseBcurrentOffset : 31|1@1+ (1,0) [0|1] ""  gtw
 SG_ DIS_a031_phaseAcurrentOffset : 30|1@1+ (1,0) [0|1] ""  gtw
 SG_ DIS_a030_phaseCrms : 29|1@1+ (1,0) [0|1] ""  gtw
 SG_ DIS_a029_phaseBrms : 28|1@1+ (1,0) [0|1] ""  gtw
 SG_ DIS_a028_phaseArms : 27|1@1+ (1,0) [0|1] ""  gtw
 SG_ DIS_a027_phaseCpeak : 26|1@1+ (1,0) [0|1] ""  gtw
 SG_ DIS_a026_phaseBpeak : 25|1@1+ (1,0) [0|1] ""  gtw
 SG_ DIS_a025_phaseApeak : 24|1@1+ (1,0) [0|1] ""  gtw
 SG_ DIS_a024_selfTest : 23|1@1+ (1,0) [0|1] ""  gtw
 SG_ DIS_a022_hw5vSupplyUV : 21|1@1+ (1,0) [0|1] ""  gtw
 SG_ DIS_a021_hwBusOV : 20|1@1+ (1,0) [0|1] ""  gtw
 SG_ DIS_a020_hwMotorEncoder : 19|1@1+ (1,0) [0|1] ""  gtw
 SG_ DIS_a019_hwAccelPedalPower : 18|1@1+ (1,0) [0|1] ""  gtw
 SG_ DIS_a018_hw12vSupplyUV : 17|1@1+ (1,0) [0|1] ""  gtw
 SG_ DIS_a017_hwPedalMonitor : 16|1@1+ (1,0) [0|1] ""  gtw
 SG_ DIS_a016_safeStateApplied : 15|1@1+ (1,0) [0|1] ""  gtw
 SG_ DIS_a014_activeDamping : 13|1@1+ (1,0) [0|1] ""  gtw
 SG_ DIS_a011_swPowerStageNotReady : 10|1@1+ (1,0) [0|1] ""  gtw
 SG_ DIS_a009_hwEncoderB : 8|1@1+ (1,0) [0|1] ""  gtw
 SG_ DIS_a008_hwEncoderA : 7|1@1+ (1,0) [0|1] ""  gtw
 SG_ DIS_a007_hwHvilNotPresent : 6|1@1+ (1,0) [0|1] ""  gtw
 SG_ DIS_a006_hwPhaseCpeak : 5|1@1+ (1,0) [0|1] ""  gtw
 SG_ DIS_a005_hwPhaseBpeak : 4|1@1+ (1,0) [0|1] ""  gtw
 SG_ DIS_a004_hwPhaseApeak : 3|1@1+ (1,0) [0|1] ""  gtw
 SG_ DIS_a003_hwPhaseCgateDrive : 2|1@1+ (1,0) [0|1] ""  gtw
 SG_ DIS_a002_hwPhaseBgateDrive : 1|1@1+ (1,0) [0|1] ""  gtw
 SG_ DIS_a001_hwPhaseAgateDrive : 0|1@1+ (1,0) [0|1] ""  gtw

BO_ 1301 VCFRONT_alertCleared: 2 VEH
 SG_ VCFRONT_alertClearedID : 0|9@1+ (1,0) [0|349] ""  X

BO_ 900 PMS_alertMatrix1: 8 VEH
 SG_ PMS_w064_torqueIntervention : 63|1@1+ (1,0) [0|1] ""  gtw
 SG_ PMS_w063_debugAlert : 62|1@1+ (1,0) [0|1] ""  gtw
 SG_ PMS_w061_DIPMVersionMismatch : 60|1@1+ (1,0) [0|1] ""  gtw
 SG_ PMS_w057_canDataBusB : 56|1@1+ (1,0) [0|1] ""  gtw
 SG_ PMS_w056_canHardwareBusB : 55|1@1+ (1,0) [0|1] ""  gtw
 SG_ PMS_w055_resolver : 54|1@1+ (1,0) [0|1] ""  gtw
 SG_ PMS_w054_uiMIA : 53|1@1+ (1,0) [0|1] ""  gtw
 SG_ PMS_w053_vcfrontMIA : 52|1@1+ (1,0) [0|1] ""  gtw
 SG_ PMS_w045_motorMovementDetected : 44|1@1+ (1,0) [0|1] ""  gtw
 SG_ PMS_w043_inconsistentConfig : 42|1@1+ (1,0) [0|1] ""  gtw
 SG_ PMS_w042_gtwMIA : 41|1@1+ (1,0) [0|1] ""  gtw
 SG_ PMS_w040_pmMIA : 39|1@1+ (1,0) [0|1] ""  gtw
 SG_ PMS_w039_disMIA : 38|1@1+ (1,0) [0|1] ""  gtw
 SG_ PMS_w038_inconsistentTorqueSign : 37|1@1+ (1,0) [0|1] ""  gtw
 SG_ PMS_w034_trqCrossCheck : 33|1@1+ (1,0) [0|1] ""  gtw
 SG_ PMS_w033_selfTest : 32|1@1+ (1,0) [0|1] ""  gtw
 SG_ PMS_w032_registerConfigError : 31|1@1+ (1,0) [0|1] ""  gtw
 SG_ PMS_w031_highStackUsage : 30|1@1+ (1,0) [0|1] ""  gtw
 SG_ PMS_w028_torqueCmdError : 27|1@1+ (1,0) [0|1] ""  gtw
 SG_ PMS_w027_torqueOutOfMap : 26|1@1+ (1,0) [0|1] ""  gtw
 SG_ PMS_w026_diHeartBeatMIA : 25|1@1+ (1,0) [0|1] ""  gtw
 SG_ PMS_w019_statorTempIrrational : 18|1@1+ (1,0) [0|1] ""  gtw
 SG_ PMS_w018_encoderIrrational : 17|1@1+ (1,0) [0|1] ""  gtw
 SG_ PMS_w013_canHardwareBusA : 12|1@1+ (1,0) [0|1] ""  gtw
 SG_ PMS_w012_canDataBusA : 11|1@1+ (1,0) [0|1] ""  gtw
 SG_ PMS_w011_phaseCurrentIrrational : 10|1@1+ (1,0) [0|1] ""  gtw
 SG_ PMS_w010_diMIA : 9|1@1+ (1,0) [0|1] ""  gtw
 SG_ PMS_w009_espMIA : 8|1@1+ (1,0) [0|1] ""  gtw
 SG_ PMS_w008_memoryError : 7|1@1+ (1,0) [0|1] ""  gtw
 SG_ PMS_w007_watchdogReset : 6|1@1+ (1,0) [0|1] ""  gtw
 SG_ PMS_w006_inconsistentDIGear : 5|1@1+ (1,0) [0|1] ""  gtw
 SG_ PMS_w005_torqueInNeutral : 4|1@1+ (1,0) [0|1] ""  gtw
 SG_ PMS_w004_regenTorque : 3|1@1+ (1,0) [0|1] ""  gtw
 SG_ PMS_w003_torqueReversal : 2|1@1+ (1,0) [0|1] ""  gtw
 SG_ PMS_w002_accumulatedTorque : 1|1@1+ (1,0) [0|1] ""  gtw
 SG_ PMS_w001_absoluteTorque : 0|1@1+ (1,0) [0|1] ""  gtw

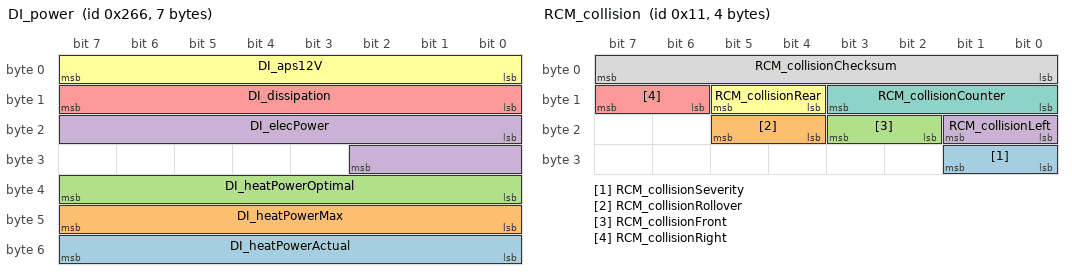
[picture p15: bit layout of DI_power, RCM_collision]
BO_ 614 DI_power: 7 VEH
 SG_ DI_heatPowerActual : 48|8@1+ (0.08,0) [0|20] "kW"  gtw
 SG_ DI_heatPowerMax : 40|8@1+ (0.08,0) [0|20] "kW"  gtw
 SG_ DI_heatPowerOptimal : 32|8@1+ (0.08,0) [0|20] "kW"  X
 SG_ DI_elecPower : 16|11@1- (0.5,0.0) [-500|500] "kW"  bms
 SG_ DI_dissipation : 8|8@1+ (125,0) [0|31000] "W"  X
 SG_ DI_aps12V : 0|8@1+ (0.1,0) [0|25.5] "V"  X

BO_ 1369 GTW_mismatchFault: 6 VEH
 SG_ GTW_BLEEPREARmismatchFault : 43|1@1+ (1,0) [0|1] ""  X
 SG_ GTW_BLEEPRIGHTmismatchFault : 42|1@1+ (1,0) [0|1] ""  X
 SG_ GTW_BLEEPLEFTmismatchFault : 41|1@1+ (1,0) [0|1] ""  X
 SG_ GTW_CBCmismatchFault : 40|1@1+ (1,0) [0|1] ""  X
 SG_ GTW_SWCmismatchFault : 39|1@1+ (1,0) [0|1] ""  X
 SG_ GTW_HCMRmismatchFault : 38|1@1+ (1,0) [0|1] ""  X
 SG_ GTW_HCMLmismatchFault : 37|1@1+ (1,0) [0|1] ""  X
 SG_ GTW_OPCSmismatchFault : 36|1@1+ (1,0) [0|1] ""  vcfront
 SG_ GTW_OPCmismatchFault : 35|1@1+ (1,0) [0|1] ""  vcfront
 SG_ GTW_CMPmismatchFault : 34|1@1+ (1,0) [0|1] ""  X
 SG_ GTW_EPAS3SmismatchFault : 33|1@1+ (1,0) [0|1] ""  X
 SG_ GTW_VCRIGHTmismatchFault : 32|1@1+ (1,0) [0|1] ""  vcfront
 SG_ GTW_VCLEFTmismatchFault : 31|1@1+ (1,0) [0|1] ""  vcfront
 SG_ GTW_VCFRONTmismatchFault : 30|1@1+ (1,0) [0|1] ""  vcfront
 SG_ GTW_TPMSmismatchFault : 29|1@1+ (1,0) [0|1] ""  X
 SG_ GTW_THSmismatchFault : 28|1@1+ (1,0) [0|1] ""  X
 SG_ GTW_TASmismatchFault : 27|1@1+ (1,0) [0|1] ""  X
 SG_ GTW_VCSECmismatchFault : 26|1@1+ (1,0) [0|1] ""  X
 SG_ GTW_SCCMmismatchFault : 25|1@1+ (1,0) [0|1] ""  vcfront
 SG_ GTW_RCMCALmismatchFault : 24|1@1+ (1,0) [0|1] ""  X
 SG_ GTW_RCMmismatchFault : 23|1@1+ (1,0) [0|1] ""  X
 SG_ GTW_RADCmismatchFault : 22|1@1+ (1,0) [0|1] ""  X
 SG_ GTW_PTCmismatchFault : 21|1@1+ (1,0) [0|1] ""  X
 SG_ GTW_PMSmismatchFault : 20|1@1+ (1,0) [0|1] ""  vcfront
 SG_ GTW_PMmismatchFault : 19|1@1+ (1,0) [0|1] ""  vcfront
 SG_ GTW_PCSCPU2mismatchFault : 18|1@1+ (1,0) [0|1] ""  vcfront
 SG_ GTW_PCSmismatchFault : 17|1@1+ (1,0) [0|1] ""  vcfront
 SG_ GTW_PARKmismatchFault : 16|1@1+ (1,0) [0|1] ""  X
 SG_ GTW_OCS1PmismatchFault : 15|1@1+ (1,0) [0|1] ""  X
 SG_ GTW_IBSTCALmismatchFault : 14|1@1+ (1,0) [0|1] ""  vcfront
 SG_ GTW_IBSTmismatchFault : 13|1@1+ (1,0) [0|1] ""  vcfront
 SG_ GTW_HVPmismatchFault : 12|1@1+ (1,0) [0|1] ""  vcfront
 SG_ GTW_GTWmismatchFault : 11|1@1+ (1,0) [0|1] ""  vcfront
 SG_ GTW_ESPCALmismatchFault : 10|1@1+ (1,0) [0|1] ""  vcfront
 SG_ GTW_ESPmismatchFault : 9|1@1+ (1,0) [0|1] ""  vcfront
 SG_ GTW_EPBRmismatchFault : 8|1@1+ (1,0) [0|1] ""  vcfront
 SG_ GTW_EPBLmismatchFault : 7|1@1+ (1,0) [0|1] ""  vcfront
 SG_ GTW_EPAS3PmismatchFault : 6|1@1+ (1,0) [0|1] ""  vcfront
 SG_ GTW_DImismatchFault : 5|1@1+ (1,0) [0|1] ""  vcfront
 SG_ GTW_CPmismatchFault : 4|1@1+ (1,0) [0|1] ""  vcfront
 SG_ GTW_BMSmismatchFault : 3|1@1+ (1,0) [0|1] ""  vcfront
 SG_ GTW_BLEEPCENTERmismatchFault : 2|1@1+ (1,0) [0|1] ""  X
 SG_ GTW_DISmismatchFault : 1|1@1+ (1,0) [0|1] ""  vcfront
 SG_ GTW_APSmismatchFault : 0|1@1+ (1,0) [0|1] ""  X

BO_ 17 RCM_collision: 4 VEH
 SG_ RCM_collisionSeverity : 24|2@1+ (1,0) [0|3] ""  bms
 SG_ RCM_collisionRollover : 20|2@1+ (1,0) [0|3] ""  vcfront
 SG_ RCM_collisionFront : 18|2@1+ (1,0) [0|3] ""  vcfront
 SG_ RCM_collisionLeft : 16|2@1+ (1,0) [0|3] ""  vcfront
 SG_ RCM_collisionRight : 14|2@1+ (1,0) [0|3] ""  vcfront
 SG_ RCM_collisionRear : 12|2@1+ (1,0) [0|3] ""  bms
 SG_ RCM_collisionCounter : 8|4@1+ (1,0) [0|15] ""  vcfront
 SG_ RCM_collisionChecksum : 0|8@1+ (1,0) [0|255] ""  vcfront

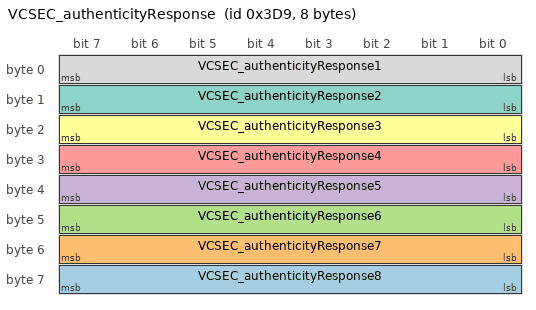
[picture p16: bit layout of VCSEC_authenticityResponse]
BO_ 985 VCSEC_authenticityResponse: 8 VEH
 SG_ VCSEC_authenticityResponse8 : 56|8@1+ (1,0) [0|255] ""  di
 SG_ VCSEC_authenticityResponse7 : 48|8@1+ (1,0) [0|255] ""  di
 SG_ VCSEC_authenticityResponse6 : 40|8@1+ (1,0) [0|255] ""  di
 SG_ VCSEC_authenticityResponse5 : 32|8@1+ (1,0) [0|255] ""  di
 SG_ VCSEC_authenticityResponse4 : 24|8@1+ (1,0) [0|255] ""  di
 SG_ VCSEC_authenticityResponse3 : 16|8@1+ (1,0) [0|255] ""  di
 SG_ VCSEC_authenticityResponse2 : 8|8@1+ (1,0) [0|255] ""  di
 SG_ VCSEC_authenticityResponse1 : 0|8@1+ (1,0) [0|255] ""  di

BO_ 855 DI_alertMatrix2: 8 VEH
 SG_ DI_a127_gracefulPowerOff : 62|1@1+ (1,0) [0|1] ""  gtw
 SG_ DI_a126_limpMode : 61|1@1+ (1,0) [0|1] ""  gtw
 SG_ DI_a125_noBatteryPower : 60|1@1+ (1,0) [0|1] ""  gtw
 SG_ DI_a124_cruiseFault : 59|1@1+ (1,0) [0|1] ""  gtw
 SG_ DI_a123_lossMotorControl : 58|1@1+ (1,0) [0|1] ""  gtw
 SG_ DI_a122_highStackUsage : 57|1@1+ (1,0) [0|1] ""  gtw
 SG_ DI_a121_motorControlRegulation : 56|1@1+ (1,0) [0|1] ""  gtw
 SG_ DI_a117_diMIA : 52|1@1+ (1,0) [0|1] ""  gtw
 SG_ DI_a116_powerConvIrrational : 51|1@1+ (1,0) [0|1] ""  gtw
 SG_ DI_a115_heatsinkTempImbalance : 50|1@1+ (1,0) [0|1] ""  gtw
 SG_ DI_a114_noMotorSpeed : 49|1@1+ (1,0) [0|1] ""  gtw
 SG_ DI_a113_noFuncHeatsinkSensor : 48|1@1+ (1,0) [0|1] ""  gtw
 SG_ DI_a112_noPhaseCurrent : 47|1@1+ (1,0) [0|1] ""  gtw
 SG_ DI_a110_brakeMIA : 45|1@1+ (1,0) [0|1] ""  gtw
 SG_ DI_a109_cruiseMIA : 44|1@1+ (1,0) [0|1] ""  gtw
 SG_ DI_a108_stateTrans : 43|1@1+ (1,0) [0|1] ""  gtw
 SG_ DI_a106_absMIA : 41|1@1+ (1,0) [0|1] ""  gtw
 SG_ DI_a105_cpMIA : 40|1@1+ (1,0) [0|1] ""  gtw
 SG_ DI_a104_proximityIrrational : 39|1@1+ (1,0) [0|1] ""  gtw
 SG_ DI_a103_lowFlow : 38|1@1+ (1,0) [0|1] ""  gtw
 SG_ DI_a100_assertion : 35|1@1+ (1,0) [0|1] ""  gtw
 SG_ DI_a099_threadOverrun : 34|1@1+ (1,0) [0|1] ""  gtw
 SG_ DI_a098_intTimeTooLong : 33|1@1+ (1,0) [0|1] ""  gtw
 SG_ DI_a097_eepromError : 32|1@1+ (1,0) [0|1] ""  gtw
 SG_ DI_a096_memoryError : 31|1@1+ (1,0) [0|1] ""  gtw
 SG_ DI_a095_canOverrunBusA : 30|1@1+ (1,0) [0|1] ""  gtw
 SG_ DI_a094_canDataBusA : 29|1@1+ (1,0) [0|1] ""  gtw
 SG_ DI_a093_canHardwareBusA : 28|1@1+ (1,0) [0|1] ""  gtw
 SG_ DI_a092_bmsMIA : 27|1@1+ (1,0) [0|1] ""  gtw
 SG_ DI_a091_espMIA : 26|1@1+ (1,0) [0|1] ""  gtw
 SG_ DI_a090_pmMIA : 25|1@1+ (1,0) [0|1] ""  gtw
 SG_ DI_a089_sccmMIA : 24|1@1+ (1,0) [0|1] ""  gtw
 SG_ DI_a088_uiMIA : 23|1@1+ (1,0) [0|1] ""  gtw
 SG_ DI_a087_gtwMIA : 22|1@1+ (1,0) [0|1] ""  gtw
 SG_ DI_a086_hvilNotPresent : 21|1@1+ (1,0) [0|1] ""  gtw
 SG_ DI_a085_proximityInEnable : 20|1@1+ (1,0) [0|1] ""  gtw
 SG_ DI_a083_brakePedalSensor : 18|1@1+ (1,0) [0|1] ""  gtw
 SG_ DI_a082_accelTrack2 : 17|1@1+ (1,0) [0|1] ""  gtw
 SG_ DI_a081_accelTrack1 : 16|1@1+ (1,0) [0|1] ""  gtw
 SG_ DI_a080_accelSynch : 15|1@1+ (1,0) [0|1] ""  gtw
 SG_ DI_a079_adcRefHigh : 14|1@1+ (1,0) [0|1] ""  gtw
 SG_ DI_a078_adcRefLow : 13|1@1+ (1,0) [0|1] ""  gtw
 SG_ DI_a077_12vSupplyUV : 12|1@1+ (1,0) [0|1] ""  gtw
 SG_ DI_a076_12vSupplyOV : 11|1@1+ (1,0) [0|1] ""  gtw
 SG_ DI_a075_motorSpeedMismatch : 10|1@1+ (1,0) [0|1] ""  gtw
 SG_ DI_a074_motorEncoder : 9|1@1+ (1,0) [0|1] ""  gtw
 SG_ DI_a073_motorSpeed : 8|1@1+ (1,0) [0|1] ""  gtw
 SG_ DI_a072_gateDriveFaultCounter : 7|1@1+ (1,0) [0|1] ""  gtw
 SG_ DI_a071_busDisconnected : 6|1@1+ (1,0) [0|1] ""  gtw
 SG_ DI_a070_12vSupplySensor : 5|1@1+ (1,0) [0|1] ""  gtw
 SG_ DI_a067_canOverrunBusB : 2|1@1+ (1,0) [0|1] ""  gtw
 SG_ DI_a066_canDataBusB : 1|1@1+ (1,0) [0|1] ""  gtw
 SG_ DI_a065_canHardwareBusB : 0|1@1+ (1,0) [0|1] ""  gtw

BO_ 1116 CC_alertLog: 8 VEH
 SG_ CC_alertType : 15|1@1+ (1,0) [0|1] ""  gtw
 SG_ CC_alertID : 0|15@1+ (1,0) [0|30] ""  dbg

BO_ 946 BMS_log2: 8 VEH
 SG_ BMS_cacMaxBrickId m0 : 56|7@1+ (1,1) [1|128] ""  gtw
 SG_ BMS_1kHzTask_maxExecTime m9 : 48|11@1+ (1,0) [0|2047] "us"  gtw
 SG_ BMS_currentReg_output m5 : 48|14@1- (0.1,0) [-819.2|819.1] "A"  dbg
 SG_ BMS_negCtrDeviationFiltConfMax m16 : 45|13@1+ (0.000122100107192,0) [0|1] "-"  gtw
 SG_ BMS_posCtrDeviationFiltConfMax m12 : 45|13@1+ (0.000122100107192,0) [0|1] "-"  gtw
 SG_ BMS_negCtrOffsetErrorConf m18 : 45|13@1+ (0.000122100107192,0) [0|1] "-"  gtw
 SG_ BMS_posCtrOffsetErrorConf m14 : 45|13@1+ (0.000122100107192,0) [0|1] "-"  gtw
 SG_ BMS_cacMaxKalmanError m1 : 45|10@1+ (0.01,0) [0|10] "Ah"  gtw
 SG_ BMS_negCtrDeviationConfidenceMax m15 : 45|13@1+ (0.000122100107192,0) [0|1] "-"  gtw
 SG_ BMS_posCtrDeviationConfidenceMax m11 : 45|13@1+ (0.000122100107192,0) [0|1] "-"  gtw
 SG_ BMS_negCtrResistanceConfidence m10 : 45|13@1+ (12.21001071916841,0) [0|100000] "-"  gtw
 SG_ BMS_posCtrDropCorrectedFiltMax m13 : 45|13@1- (0.001221299164314,0) [-5|5] "V"  gtw
 SG_ BMS_negCtrDropCorrectedFiltMax m17 : 45|13@1- (0.001221299164314,0) [-5|5] "V"  gtw
 SG_ BMS_cacMax m0 : 40|13@1+ (0.1,0) [0|819.1] "Ah"  gtw
 SG_ BMS_vshTestMinDeltaVBrickID m4 : 40|7@1+ (1,1) [1|128] ""  gtw
 SG_ BMS_negCtrResistance m10 : 32|13@1- (2.442598329e-06,0) [-0.01|0.01] "Ohm"  gtw
 SG_ BMS_posCtrDropCorrectedFiltMin m13 : 32|13@1- (0.001221299164314,0) [-5|5] "V"  gtw
 SG_ BMS_negCtrDropCorrectedFiltMin m17 : 32|13@1- (0.001221299164314,0) [-5|5] "V"  gtw
 SG_ BMS_100HzTask_maxExecTime m9 : 32|14@1+ (1,0) [0|16383] "us"  gtw
 SG_ BMS_10HzTask_maxExecTime m8 : 32|17@1+ (1,0) [0|131071] "us"  gtw
 SG_ BMS_1HzTask_maxExecTime m7 : 32|20@1+ (1,0) [0|1048575] "us"  gtw
 SG_ BMS_negCtrDeviationFiltConfMin m16 : 32|13@1+ (0.000122100107192,0) [0|1] "-"  gtw
 SG_ BMS_floodPortV2 m2 : 32|16@1+ (0.001,0) [0|65.535] "V"  gtw
 SG_ BMS_posCtrDeviationFiltConfMin m12 : 32|13@1+ (0.000122100107192,0) [0|1] "-"  gtw
 SG_ BMS_currentReg_targetI m5 : 32|11@1+ (0.5,0) [0|1023.5] "A"  dbg
 SG_ BMS_cacMinUpperBoundEst m1 : 32|13@1+ (0.1,0) [0|819.1] "Ah"  gtw
 SG_ BMS_posCtrOffsetError m14 : 32|13@1- (0.001221299164314,0) [-5|5] "V"  gtw
 SG_ BMS_posCtrDeviationConfidenceMin m11 : 32|13@1+ (0.000122100107192,0) [0|1] "-"  gtw
 SG_ BMS_negCtrDeviationConfidenceMin m15 : 32|13@1+ (0.000122100107192,0) [0|1] "-"  gtw
 SG_ BMS_negCtrOffsetError m18 : 32|13@1- (0.001221299164314,0) [-5|5] "V"  gtw
 SG_ BMS_cacMinBrickId m0 : 32|7@1+ (1,1) [1|128] ""  gtw
 SG_ BMS_hvChain_limitingStateTempera m19 : 32|16@1- (0.01,0) [-327.68|327.67] "DegC"  gtw
 SG_ BMS_vshTestMinDeltaV m4 : 32|8@1+ (0.002,0) [0|0.5] "V"  gtw
 SG_ BMS_ahDischargeTotal m6 : 32|24@1+ (0.1,0) [0|1677721.5] "Ah"  gtw
 SG_ BMS_vshTestMaxDeltaVBrickID m4 : 24|7@1+ (1,1) [1|128] ""  gtw
 SG_ BMS_hvChain_limitingState m19 : 24|5@1+ (1,0) [0|31] ""  gtw
 SG_ BMS_chgEndDcEvseFault m3 : 23|1@1+ (1,0) [0|1] ""  gtw
 SG_ BMS_chgEndDcEvseDisabled m3 : 22|1@1+ (1,0) [0|1] ""  gtw
 SG_ BMS_maxDcCurrentAvailable m5 : 21|11@1+ (0.5,0) [0|1023.5] "A"  dbg
 SG_ BMS_chgEndDcEvseCompatible m3 : 21|1@1+ (1,0) [0|1] ""  gtw
 SG_ BMS_1kHzTask_avgExecTime m9 : 20|11@1+ (1,0) [0|2047] "us"  gtw
 SG_ BMS_chgEndDcEvseEnabled m3 : 20|1@1+ (1,0) [0|1] ""  gtw
 SG_ BMS_posCtrDropCorrectedMax m13 : 19|13@1- (0.001221299164314,0) [-5|5] "V"  gtw
 SG_ BMS_cacMin m0 : 19|13@1+ (0.1,0) [0|819.1] "Ah"  gtw
 SG_ BMS_chgEndChargeCableSecured m3 : 19|1@1+ (1,0) [0|1] ""  gtw
 SG_ BMS_negCtrDropCorrectedMax m17 : 19|13@1- (0.001221299164314,0) [-5|5] "V"  gtw
 SG_ BMS_negCtrDeviationMax m15 : 19|13@1- (0.001221299164314,0) [-5|5] "V"  gtw
 SG_ BMS_posCtrDeviationMax m11 : 19|13@1- (0.001221299164314,0) [-5|5] "V"  gtw
 SG_ BMS_negCtrCommonModeRejErrorConf m18 : 19|13@1+ (1.221001071916841,0) [0|10000] "-"  gtw
 SG_ BMS_posCtrCommonModeRejErrorConf m14 : 19|13@1+ (1.221001071916841,0) [0|10000] "-"  gtw
 SG_ BMS_cacMinRawEstimate m1 : 19|13@1+ (0.1,0) [0|819.1] "Ah"  gtw
 SG_ BMS_posCtrResistanceConfidence m10 : 19|13@1+ (12.21001071916841,0) [0|100000] "-"  gtw
 SG_ BMS_negCtrDeviationFiltMax m16 : 19|13@1- (0.001221299164314,0) [-5|5] "V"  gtw
 SG_ BMS_posCtrDeviationFiltMax m12 : 19|13@1- (0.001221299164314,0) [-5|5] "V"  gtw
 SG_ BMS_chgEndBatteryChargeRequest m3 : 18|1@1+ (1,0) [0|1] ""  gtw
 SG_ BMS_vshTestMaxDeltaV m4 : 16|8@1+ (0.002,0) [0|0.5] "V"  gtw
 SG_ BMS_floodPortV1 m2 : 16|16@1+ (0.001,0) [0|65.535] "V"  gtw
 SG_ BMS_chgEndPcsStatus m3 : 16|2@1+ (1,0) [0|2] ""  gtw
 SG_ BMS_floodPortState2 m2 : 13|3@1+ (1,0) [0|4] ""  dbg
 SG_ BMS_chgEndChargeState m3 : 12|4@1+ (1,0) [0|15] ""  gtw
 SG_ BMS_floodPortState1 m2 : 10|3@1+ (1,0) [0|4] ""  dbg
 SG_ BMS_chargeNeededReason m5 : 9|3@1+ (1,0) [0|6] ""  gtw
 SG_ BMS_hvChain_iLimit m19 : 9|14@1+ (0.128,0) [0|2096.896] "A"  gtw
 SG_ BMS_chgRequestTerminatedCount m3 : 8|4@1+ (1,0) [0|15] ""  gtw
 SG_ BMS_hvChain_useLeakyBucket m19 : 8|1@1+ (1,0) [0|1] ""  gtw
 SG_ BMS_ahChargeTotal m6 : 8|24@1+ (0.1,0) [0|1677721.5] "Ah"  gtw
 SG_ BMS_posCtrResistance m10 : 6|13@1- (2.442598329e-06,0) [-0.01|0.01] "Ohm"  gtw
 SG_ BMS_posCtrCommonModeRejError m14 : 6|13@1- (2.4425983286e-05,0) [-0.1|0.1] "-"  gtw
 SG_ BMS_negCtrCommonModeRejError m18 : 6|13@1- (2.442592959e-05,0) [-0.1|0.1] "-"  gtw
 SG_ BMS_posCtrDropCorrectedMin m13 : 6|13@1- (0.001221299164314,0) [-5|5] "V"  gtw
 SG_ BMS_negCtrDropCorrectedMin m17 : 6|13@1- (0.001221299164314,0) [-5|5] "V"  gtw
 SG_ BMS_1HzTask_avgExecTime m7 : 6|20@1+ (1,0) [0|1048575] "us"  gtw
 SG_ BMS_100HzTask_avgExecTime m9 : 6|14@1+ (1,0) [0|16383] "us"  gtw
 SG_ BMS_negCtrDeviationFiltMin m16 : 6|13@1- (0.001221299164314,0) [-5|5] "V"  gtw
 SG_ BMS_10HzTask_avgExecTime m8 : 6|17@1+ (1,0) [0|131071] "us"  gtw
 SG_ BMS_posCtrDeviationFiltMin m12 : 6|13@1- (0.001221299164314,0) [-5|5] "V"  gtw
 SG_ BMS_chargeCurrentLimitMode m5 : 6|3@1+ (1,0) [0|4] ""  dbg
 SG_ BMS_negCtrDeviationMin m15 : 6|13@1- (0.001221299164314,0) [-5|5] "V"  gtw
 SG_ BMS_posCtrDeviationMin m11 : 6|13@1- (0.001221299164314,0) [-5|5] "V"  gtw
 SG_ BMS_cacMinLowerBoundEst m1 : 6|13@1+ (0.1,0) [0|819.1] "Ah"  gtw
 SG_ BMS_cacAvg m0 : 6|13@1+ (0.1,0) [0|819.1] "Ah"  gtw
 SG_ BMS_chgEndEvseChargeType m3 : 6|2@1+ (1,0) [0|2] ""  gtw
 SG_ BMS_log2MuxId M : 0|6@1+ (1,0) [0|19] ""  X

BA_DEF_ SG_  "SystemSignalLongSymbol" STRING ;
BA_DEF_DEF_  "SystemSignalLongSymbol" "";
BA_ "SystemSignalLongSymbol" SG_ 291 VCRIGHT_frontHandleDebounceStatu "VCRIGHT_frontHandleDebounceStatus";
BA_ "SystemSignalLongSymbol" SG_ 1017 VCSEC_a180_wlistRemovedPermissio "VCSEC_a180_wlistRemovedPermission";
BA_ "SystemSignalLongSymbol" SG_ 1017 VCSEC_a209_BLECenterAssertFailur "VCSEC_a209_BLECenterAssertFailure";
BA_ "SystemSignalLongSymbol" SG_ 1017 VCSEC_a200_centerEndpointLostCom "VCSEC_a200_centerEndpointLostComm";
BA_ "SystemSignalLongSymbol" SG_ 1017 VCSEC_a189_protoExpLengthTooLarg "VCSEC_a189_protoExpLengthTooLarge";
BA_ "SystemSignalLongSymbol" SG_ 1017 VCSEC_a185_passengerEndpointRFMi "VCSEC_a185_passengerEndpointRFMia";
BA_ "SystemSignalLongSymbol" SG_ 1825 VCFRONT_condenserFeedfwdForChill "VCFRONT_condenserFeedfwdForChiller";
BA_ "SystemSignalLongSymbol" SG_ 946 BMS_hvChain_limitingStateTempera "BMS_hvChain_limitingStateTemperature";
VAL_ 1304 VCRIGHT_alertClearedID 270 "VCRIGHT_a270_seatLiftHCEncStlDbg" 305 "VCRIGHT_a305_rearIntHandleShorted" 306 "VCRIGHT_a306_handleDisconnectedF" 247 "VCRIGHT_a247_seatHeatMIARearC" 105 "VCRIGHT_a105_TAS_MIA" 12 "VCRIGHT_a012_CPUReset" 148 "VCRIGHT_a148_incarMidTempSns" 134 "VCRIGHT_a134_hvacUpprModeUncalib" 286 "VCRIGHT_a286_windowSpeedInvalidF" 276 "VCRIGHT_a276_mirrorDebug" 202 "VCRIGHT_a202_epbmUnderIStatic" 292 "VCRIGHT_a292_buckleFaultedRearC" 320 "VCRIGHT_a320_windowPwrDerivFDBG" 215 "VCRIGHT_a215_currentDesyncWarning" 100 "VCRIGHT_a100_CANbus_MIA" 182 "VCRIGHT_a182_emergencyLatchRel" 141 "VCRIGHT_a141_hvacUpperModeFault" 41 "VCRIGHT_a041_HighCPULoad" 118 "VCRIGHT_a118_VCFRONT_MIA" 109 "VCRIGHT_a109_RCM_MIA" 242 "VCRIGHT_a242_seatHeatIRearL" 136 "VCRIGHT_a136_hvacIntakeFault" 240 "VCRIGHT_a240_seatHeatShortFront" 324 "VCRIGHT_a324_mirrorHeatFault" 188 "VCRIGHT_a188_latchUnableToRearmF" 110 "VCRIGHT_a110_GTW_MIA" 210 "VCRIGHT_a210_epbStateTime" 152 "VCRIGHT_a152_windowUncalFront" 111 "VCRIGHT_a111_EPBR_MIA" 245 "VCRIGHT_a245_seatHeatIRearC" 170 "VCRIGHT_a170_windowCurrentPeakR" 196 "VCRIGHT_a196_VEHCANOverterminate" 130 "VCRIGHT_a130_hvacLHBleedUncalib" 224 "VCRIGHT_a224_seatEncStallTrack" 159 "VCRIGHT_a159_windowPinchOverideR" 221 "VCRIGHT_a221_seatCurrStallBack" 260 "VCRIGHT_a260_latchDisarmDelayR" 266 "VCRIGHT_a266_seatLiftStallDebug" 21 "VCRIGHT_a021_TaskSchedulerError" 230 "VCRIGHT_a230_seatEncOverTilt" 161 "VCRIGHT_a161_windowUndercurrentR" 192 "VCRIGHT_a192_gloveboxLatchRel" 142 "VCRIGHT_a142_hvacLowerModeFault" 238 "VCRIGHT_a238_lumbarValveMIA" 236 "VCRIGHT_a236_lumbarOverPresA" 151 "VCRIGHT_a151_windowPinchRear" 209 "VCRIGHT_a209_epbStateMisTime" 131 "VCRIGHT_a131_hvacRHBleedUncalib" 104 "VCRIGHT_a104_DAS_MIA" 116 "VCRIGHT_a116_VCRIGHT_MIA" 191 "VCRIGHT_a191_gloveboxPower" 157 "VCRIGHT_a157_windowNoInputRear" 172 "VCRIGHT_a172_SPI_MIA" 31 "VCRIGHT_a031_UDSActive" 129 "VCRIGHT_a129_hvacIntakeUncalib" 184 "VCRIGHT_a184_trunkFailedOpening" 304 "VCRIGHT_a304_frontIntHandleShorted" 263 "VCRIGHT_a263_seatTrackStallDebug" 200 "VCRIGHT_a200_motorPhantomEncoder" 233 "VCRIGHT_a233_seatCurrUnderBack" 138 "VCRIGHT_a138_hvacRHBleedFault" 220 "VCRIGHT_a220_seatCurrStallTrack" 187 "VCRIGHT_a187_latchReleaseFailedR" 168 "VCRIGHT_a168_windowDebugPinchR" 243 "VCRIGHT_a243_seatHeatShortRearL" 166 "VCRIGHT_a166_windowDebug" 144 "VCRIGHT_a144_evaporatorTempSns" 282 "VCRIGHT_a282_latchUnexpectedArmF" 120 "VCRIGHT_a120_DI_DRIVE_MIA" 101 "VCRIGHT_a101_PM_MIA" 115 "VCRIGHT_a115_VCSEC_MIA" 145 "VCRIGHT_a145_ductLeftTempSns" 264 "VCRIGHT_a264_seatBackStallDebug" 22 "VCRIGHT_a022_TaskInitError" 255 "VCRIGHT_a255_PTCOverTemp" 229 "VCRIGHT_a229_seatEncOverBack" 259 "VCRIGHT_a259_latchDisarmDelayF" 194 "VCRIGHT_a194_cntctrPwrEFuseFault" 146 "VCRIGHT_a146_ductRightTempSns" 223 "VCRIGHT_a223_seatCurrStallLift" 167 "VCRIGHT_a167_windowDebugPinchF" 195 "VCRIGHT_a195_hvcEFuseFault" 98 "VCRIGHT_a098_DI_THERMAL_MIA" 283 "VCRIGHT_a283_latchUnexpectedArmR" 231 "VCRIGHT_a231_seatEncOverLift" 269 "VCRIGHT_a269_seatTiltHCEncStlDbg" 262 "VCRIGHT_a262_PTCFaulted" 257 "VCRIGHT_a257_THSMIA" 280 "VCRIGHT_a280_latchDidNotDisarmF" 169 "VCRIGHT_a169_windowCurrentPeakF" 15 "VCRIGHT_a015_NVMMAlert" 153 "VCRIGHT_a153_windowUncalRear" 248 "VCRIGHT_a248_seatHeatIRearR" 216 "VCRIGHT_a216_SPI_MIA_debugData1" 63 "VCRIGHT_a063_SwitchFault" 3 "VCRIGHT_a003_SWAssertion" 139 "VCRIGHT_a139_hvacLHVaneFault" 162 "VCRIGHT_a162_windowEncoderStallF" 207 "VCRIGHT_a207_epbmEnableWrong" 150 "VCRIGHT_a150_windowPinchFront" 149 "VCRIGHT_a149_incarDeepTempSns" 164 "VCRIGHT_a164_windowFactoryTest" 119 "VCRIGHT_a119_SCCM_MIA" 214 "VCRIGHT_a214_epbmOverIDynNew" 234 "VCRIGHT_a234_seatCurrUnderTilt" 211 "VCRIGHT_a211_epbmUnderIStaticNew" 147 "VCRIGHT_a147_incarProbeTempSns" 322 "VCRIGHT_a322_windowPwrDerivRDBG" 113 "VCRIGHT_a113_UI_MIA" 199 "VCRIGHT_a199_PRVCANUndertrminate" 212 "VCRIGHT_a212_epbmOverIStaticNew" 46 "VCRIGHT_a046_Task1000msError" 163 "VCRIGHT_a163_windowEncoderStallR" 321 "VCRIGHT_a321_windowPwrDeriv2FDBG" 272 "VCRIGHT_a272_vhclPwrStateMsmtch" 185 "VCRIGHT_a185_summonAborted" 217 "VCRIGHT_a217_SPI_MIA_debugData2" 252 "VCRIGHT_a252_seatUncalBack" 241 "VCRIGHT_a241_seatHeatMIAFront" 135 "VCRIGHT_a135_hvacLowrModeUncalib" 107 "VCRIGHT_a107_BMS_MIA" 256 "VCRIGHT_a256_PTCCurrentDrawNoReq" 265 "VCRIGHT_a265_seatTiltStallDebug" 114 "VCRIGHT_a114_ESP_MIA" 249 "VCRIGHT_a249_seatHeatShortRearR" 143 "VCRIGHT_a143_mirrorManuallyFolded" 181 "VCRIGHT_a181_rearDoorLatchRehome" 156 "VCRIGHT_a156_windowNoInputFront" 193 "VCRIGHT_a193_amplifierEFuseFault" 190 "VCRIGHT_a190_eFuseMgmtVbatFused" 258 "VCRIGHT_a258_PTCStuckInBoot" 277 "VCRIGHT_a277_BLERightUnderVoltage" 239 "VCRIGHT_a239_seatHeatIFront" 293 "VCRIGHT_a293_buckleFaultedRearR" 42 "VCRIGHT_a042_HighStackUsage" 112 "VCRIGHT_a112_EPBL_MIA" 117 "VCRIGHT_a117_VCLEFT_MIA" 189 "VCRIGHT_a189_latchUnableToRearmR" 225 "VCRIGHT_a225_seatEncStallBack" 237 "VCRIGHT_a237_lumbarOverPresB" 103 "VCRIGHT_a103_CP_MIA" 61 "VCRIGHT_a061_XCPConnected" 45 "VCRIGHT_a045_Task100msError" 2 "VCRIGHT_a002_PowerLossReset" 290 "VCRIGHT_a290_occupancyFaultedFront" 226 "VCRIGHT_a226_seatEncStallTilt" 323 "VCRIGHT_a323_windowPwrDeriv2RDBG" 208 "VCRIGHT_a208_epbFaulted" 30 "VCRIGHT_a030_ECULogUploadRequest" 102 "VCRIGHT_a102_PTC_MIA" 235 "VCRIGHT_a235_seatCurrUnderLift" 154 "VCRIGHT_a154_windowThermalFront" 267 "VCRIGHT_a267_seatTrackHCEncStlDbg" 165 "VCRIGHT_a165_windowFactoryTest2" 291 "VCRIGHT_a291_buckleFaultedFront" 246 "VCRIGHT_a246_seatHeatShortRearC" 204 "VCRIGHT_a204_epbmUnderIDyn" 183 "VCRIGHT_a183_doorStateFactoryTest" 60 "VCRIGHT_a060_engineeringBuild" 205 "VCRIGHT_a205_epbmOverIDyn" 1 "VCRIGHT_a001_WatchdogReset" 186 "VCRIGHT_a186_latchReleaseFailedF" 232 "VCRIGHT_a232_seatCurrUnderTrack" 275 "VCRIGHT_a275_rightTurnLightFault" 158 "VCRIGHT_a158_windowPinchOverideF" 180 "VCRIGHT_a180_frontDoorLatchRehome" 310 "VCRIGHT_a310_mirrorFoldStall" 197 "VCRIGHT_a197_VEHCANUndertrminate" 222 "VCRIGHT_a222_seatCurrStallTilt" 244 "VCRIGHT_a244_seatHeatMIARearL" 218 "VCRIGHT_a218_motorDriverFault" 213 "VCRIGHT_a213_epbmUnderIDynNew" 203 "VCRIGHT_a203_epbmOverIStatic" 273 "VCRIGHT_a273_handleStuckActiveF" 160 "VCRIGHT_a160_windowUndercurrentF" 278 "VCRIGHT_a278_hvacPtcHeatingUnavailable" 64 "VCRIGHT_a064_busSleepReqTimeout" 198 "VCRIGHT_a198_PRVCANOverterminate" 250 "VCRIGHT_a250_seatHeatMIARearR" 0 "VCRIGHT_ALERT_DO_NOT_USE_ZERO" 271 "VCRIGHT_a271_THSSensorFault" 219 "VCRIGHT_a219_motorCurrentDropout" 274 "VCRIGHT_a274_handleStuckActiveR" 59 "VCRIGHT_a059_inputResistanceHigh" 281 "VCRIGHT_a281_latchDidNotDisarmR" 253 "VCRIGHT_a253_seatUncalTilt" 251 "VCRIGHT_a251_seatUncalTrack" 10 "VCRIGHT_a010_ExtSupplyVoltError" 99 "VCRIGHT_a099_PARK_MIA" 174 "VCRIGHT_a174_BLERightPowerCycled" 228 "VCRIGHT_a228_seatEncOverTrack" 254 "VCRIGHT_a254_seatUncalLift" 155 "VCRIGHT_a155_windowThermalRear" 44 "VCRIGHT_a044_Task10msError" 132 "VCRIGHT_a132_hvacLHVaneUncalib" 97 "VCRIGHT_a097_CMP_MIA" 140 "VCRIGHT_a140_hvacRHVaneFault" 268 "VCRIGHT_a268_seatBackHCEncStlDbg" 137 "VCRIGHT_a137_hvacLHBleedFault" 227 "VCRIGHT_a227_seatEncStallLift" 106 "VCRIGHT_a106_PCS_MIA" 43 "VCRIGHT_a043_Task1msError" 133 "VCRIGHT_a133_hvacRHVaneUncalib" 13 "VCRIGHT_a013_AlertManagerFault" 201 "VCRIGHT_a201_motorDutyEncDisabl" 287 "VCRIGHT_a287_windowSpeedInvalidR" 307 "VCRIGHT_a307_handleDisconnectedR" 62 "VCRIGHT_a062_XCPWasConnected" 206 "VCRIGHT_a206_epbWrongDirection" 108 "VCRIGHT_a108_DIS_MIA" ;
VAL_ 1064 EPBL_nmWakeUpReason 0 "EPB3_WAKEUP_REASON_NONE" 3 "EPB3_WAKEUP_REASON_RESET" 1 "EPB3_WAKEUP_REASON_ECU_SPECIFIC" 2 "EPB3_WAKEUP_REASON_SWITCH_INPUT" ;
VAL_ 1064 EPBL_nmKeepAwakeReason 0 "EPB3_KEEPAWAKE_REASON_NONE_SNA" 1 "EPB3_KEEPAWAKE_REASON_EPB_STATE_NOT_SAVED" 15 "EPB3_KEEPAWAKE_REASON_MULTIPLE" 2 "EPB3_KEEPAWAKE_REASON_EPB_NOT_SECURE" 5 "EPB3_KEEPAWAKE_REASON_UDS_ACTIVE" 3 "EPB3_KEEPAWAKE_REASON_EPB_LOCKOUT_PENDING" 4 "EPB3_KEEPAWAKE_REASON_EPB_SUMMON_ACTIVE" ;
VAL_ 627 UI_driveStateRequest 0 "DRIVE_STATE_REQ_IDLE" 1 "DRIVE_STATE_REQ_START" ;
VAL_ 627 UI_domeLightSwitch 0 "DOME_LIGHT_SWITCH_OFF" 1 "DOME_LIGHT_SWITCH_ON" 2 "DOME_LIGHT_SWITCH_AUTO" ;
VAL_ 627 UI_wiperRequest 0 "WIPER_REQUEST_SNA" 2 "WIPER_REQUEST_AUTO" 6 "WIPER_REQUEST_FAST_CONTINUOUS" 5 "WIPER_REQUEST_SLOW_CONTINUOUS" 1 "WIPER_REQUEST_OFF" 3 "WIPER_REQUEST_SLOW_INTERMITTENT" 4 "WIPER_REQUEST_FAST_INTERMITTENT" ;
VAL_ 627 UI_remoteClosureRequest 3 "UI_REMOTE_CLOSURE_REQUEST_SNA" 0 "UI_REMOTE_CLOSURE_REQUEST_IDLE" 1 "UI_REMOTE_CLOSURE_REQUEST_REAR_TRUNK_MOVE" 2 "UI_REMOTE_CLOSURE_REQUEST_FRONT_TRUNK_MOVE" ;
VAL_ 627 UI_rearRightSeatHeatReq 1 "HEATER_REQUEST_LEVEL1" 2 "HEATER_REQUEST_LEVEL2" 3 "HEATER_REQUEST_LEVEL3" 0 "HEATER_REQUEST_OFF" ;
VAL_ 627 UI_rearCenterSeatHeatReq 1 "HEATER_REQUEST_LEVEL1" 2 "HEATER_REQUEST_LEVEL2" 3 "HEATER_REQUEST_LEVEL3" 0 "HEATER_REQUEST_OFF" ;
VAL_ 627 UI_rearLeftSeatHeatReq 1 "HEATER_REQUEST_LEVEL1" 2 "HEATER_REQUEST_LEVEL2" 3 "HEATER_REQUEST_LEVEL3" 0 "HEATER_REQUEST_OFF" ;
VAL_ 627 UI_frontRightSeatHeatReq 1 "HEATER_REQUEST_LEVEL1" 2 "HEATER_REQUEST_LEVEL2" 3 "HEATER_REQUEST_LEVEL3" 0 "HEATER_REQUEST_OFF" ;
VAL_ 627 UI_frontLeftSeatHeatReq 1 "HEATER_REQUEST_LEVEL1" 2 "HEATER_REQUEST_LEVEL2" 3 "HEATER_REQUEST_LEVEL3" 0 "HEATER_REQUEST_OFF" ;
VAL_ 627 UI_displayBrightnessLevel 255 "SNA" ;
VAL_ 627 UI_remoteStartRequest 0 "UI_REMOTE_START_REQUEST_IDLE" 4 "UI_REMOTE_START_REQUEST_SNA" 1 "UI_REMOTE_START_REQUEST_START" ;
VAL_ 627 UI_mirrorFoldRequest 3 "MIRROR_FOLD_REQUEST_SNA" 0 "MIRROR_FOLD_REQUEST_IDLE" 1 "MIRROR_FOLD_REQUEST_RETRACT" 2 "MIRROR_FOLD_REQUEST_PRESENT" ;
VAL_ 627 UI_lockRequest 1 "UI_LOCK_REQUEST_LOCK" 7 "UI_LOCK_REQUEST_SNA" 4 "UI_LOCK_REQUEST_REMOTE_LOCK" 3 "UI_LOCK_REQUEST_REMOTE_UNLOCK" 0 "UI_LOCK_REQUEST_IDLE" 2 "UI_LOCK_REQUEST_UNLOCK" ;
VAL_ 627 UI_steeringButtonMode 2 "STEERING_BUTTON_MODE_MIRROR_LEFT" 0 "STEERING_BUTTON_MODE_OFF" 3 "STEERING_BUTTON_MODE_MIRROR_RIGHT" 4 "STEERING_BUTTON_MODE_HEADLIGHT_LEFT" 1 "STEERING_BUTTON_MODE_STEERING_COLUMN_ADJ" 5 "STEERING_BUTTON_MODE_HEADLIGHT_RIGHT" ;
VAL_ 627 UI_steeringBacklightEnabled 1 "STEERING_BACKLIGHT_ENABLED" 0 "STEERING_BACKLIGHT_DISABLED" ;
VAL_ 627 UI_wiperMode 3 "WIPER_MODE_PARK" 0 "WIPER_MODE_SNA" 1 "WIPER_MODE_SERVICE" 2 "WIPER_MODE_NORMAL" ;
VAL_ 1960 EPBR_learnedBrakeHWType 1 "EPB_BRAKE_HARDWARE_MANDO" 0 "EPB_BRAKE_HARDWARE_UNKNOWN" 2 "EPB_BRAKE_HARDWARE_BREMBO" ;
VAL_ 1960 EPBR_caliperState 5 "EPB_SAVED_CALIPERSTATE_SERVICE" 1 "EPB_SAVED_CALIPERSTATE_UNKNOWN" 4 "EPB_SAVED_CALIPERSTATE_OPEN" 2 "EPB_SAVED_CALIPERSTATE_REAPPLY" 0 "EPB_SAVED_CALIPERSTATE_UNSAVED" 3 "EPB_SAVED_CALIPERSTATE_PARK" ;
VAL_ 1960 EPBR_debugOutput 1 "EPB_DEBUG_1" 2 "EPB_DEBUG_2" 0 "EPB_DEBUG_0" ;
VAL_ 1310 FC_infoBuildType 2 "INFO_LOCAL_BUILD_FC" 4 "INFO_MFG_BUILD_FC" 3 "INFO_TRACEABLE_CI_BUILD_FC" 0 "INFO_UNKNOWN_BUILD_FC" 1 "INFO_PLATFORM_BUILD_FC" ;
VAL_ 1310 FC_infoIndex 1 "INFO_DEPRECATED_1_FC" 2 "INFO_DEPRECATED_2_FC" 13 "INFO_APP_CRC_FC" 7 "INFO_DEPRECATED_7_FC" 17 "INFO_APP_GITHASH_FC" 8 "INFO_DEPRECATED_8_FC" 14 "INFO_BOOTLOADER_SVN_FC" 11 "INFO_PCBAID_ASSYID_USAGEID_FC" 18 "INFO_BOOTLOADER_GITHASH_FC" 3 "INFO_DEPRECATED_3_FC" 25 "INFO_PART_NUM_1" 4 "INFO_DEPRECATED_4_FC" 15 "INFO_BOOTLOADER_CRC_FC" 22 "INFO_VARIANT_CRC_FC" 255 "INFO_END_FC" 9 "INFO_DEPRECATED_9_FC" 19 "INFO_VERSION_DEPRECATED_FC" 26 "INFO_PART_NUM_2" 0 "INFO_DEPRECATED_0_FC" 10 "INFO_BUILD_HWID_COMPONENTID_FC" 16 "INFO_SUBCOMPONENT_FC" 5 "INFO_DEPRECATED_5_FC" 27 "INFO_PART_NUM_3" 20 "INFO_UDS_PROTOCOL_BOOTCRC_FC" 6 "INFO_DEPRECATED_6_FC" ;
VAL_ 643 VCRIGHT_PTCRequestMode 1 "DUTY" 0 "POWER" 2 "DIRECT" ;
VAL_ 1768 EPBR_statsOutput 0 "EPB_STATIC_COUNT" 1 "EPB_DYNAMIC_COUNT" 2 "EPB_MAX_DATA" ;
VAL_ 963 VCRIGHT_rearRightBuckleSwitch 2 "SWITCH_ON" 0 "SWITCH_SNA" 3 "SWITCH_FAULT" 1 "SWITCH_OFF" ;
VAL_ 963 VCRIGHT_rearCenterBuckleSwitch 2 "SWITCH_ON" 0 "SWITCH_SNA" 3 "SWITCH_FAULT" 1 "SWITCH_OFF" ;
VAL_ 963 VCRIGHT_frontOccupancySwitch 2 "SWITCH_ON" 0 "SWITCH_SNA" 3 "SWITCH_FAULT" 1 "SWITCH_OFF" ;
VAL_ 963 VCRIGHT_frontBuckleSwitch 2 "SWITCH_ON" 0 "SWITCH_SNA" 3 "SWITCH_FAULT" 1 "SWITCH_OFF" ;
VAL_ 963 VCRIGHT_frontSeatLumbarOut 2 "SWITCH_ON" 0 "SWITCH_SNA" 3 "SWITCH_FAULT" 1 "SWITCH_OFF" ;
VAL_ 963 VCRIGHT_frontSeatLumbarIn 2 "SWITCH_ON" 0 "SWITCH_SNA" 3 "SWITCH_FAULT" 1 "SWITCH_OFF" ;
VAL_ 963 VCRIGHT_frontSeatLumbarUp 2 "SWITCH_ON" 0 "SWITCH_SNA" 3 "SWITCH_FAULT" 1 "SWITCH_OFF" ;
VAL_ 963 VCRIGHT_frontSeatLumbarDown 2 "SWITCH_ON" 0 "SWITCH_SNA" 3 "SWITCH_FAULT" 1 "SWITCH_OFF" ;
VAL_ 963 VCRIGHT_frontSeatBackrestForward 2 "SWITCH_ON" 0 "SWITCH_SNA" 3 "SWITCH_FAULT" 1 "SWITCH_OFF" ;
VAL_ 963 VCRIGHT_frontSeatBackrestBack 2 "SWITCH_ON" 0 "SWITCH_SNA" 3 "SWITCH_FAULT" 1 "SWITCH_OFF" ;
VAL_ 963 VCRIGHT_frontSeatLiftUp 2 "SWITCH_ON" 0 "SWITCH_SNA" 3 "SWITCH_FAULT" 1 "SWITCH_OFF" ;
VAL_ 963 VCRIGHT_frontSeatLiftDown 2 "SWITCH_ON" 0 "SWITCH_SNA" 3 "SWITCH_FAULT" 1 "SWITCH_OFF" ;
VAL_ 963 VCRIGHT_frontSeatTiltUp 2 "SWITCH_ON" 0 "SWITCH_SNA" 3 "SWITCH_FAULT" 1 "SWITCH_OFF" ;
VAL_ 963 VCRIGHT_frontSeatTiltDown 2 "SWITCH_ON" 0 "SWITCH_SNA" 3 "SWITCH_FAULT" 1 "SWITCH_OFF" ;
VAL_ 963 VCRIGHT_frontSeatTrackForward 2 "SWITCH_ON" 0 "SWITCH_SNA" 3 "SWITCH_FAULT" 1 "SWITCH_OFF" ;
VAL_ 963 VCRIGHT_frontSeatTrackBack 2 "SWITCH_ON" 0 "SWITCH_SNA" 3 "SWITCH_FAULT" 1 "SWITCH_OFF" ;
VAL_ 792 GTW_tsMonth 9 "SEPTEMBER" 12 "DECEMBER" 10 "OCTOBER" 1 "JANUARY" 7 "JULY" 11 "NOVEMBER" 5 "MAY" 4 "APRIL" 6 "JUNE" 2 "FEBRUARY" 3 "MARCH" 8 "AUGUST" ;
VAL_ 771 VCRIGHT_infoAssemblyId 1 "ASSEMBLY1" 255 "ASSEMBLY_SNA" ;
VAL_ 771 VCRIGHT_infoBuildType 1 "INFO_PLATFORM_BUILD" 3 "INFO_TRACEABLE_CI_BUILD" 4 "INFO_MFG_BUILD" 2 "INFO_LOCAL_BUILD" 0 "INFO_UNKNOWN_BUILD" ;
VAL_ 771 VCRIGHT_infoIndex 14 "BC_INFO_BOOTLOADER_SVN" 6 "BC_INFO_DEPRECATED_6" 20 "BC_INFO_UDS_PROTOCOL_BOOTCRC" 24 "BC_INFO_SUBCOMPONENT3" 1 "BC_INFO_DEPRECATED_1" 31 "BC_INFO_SUBCOMPONENT4" 19 "BC_INFO_VERSION_DEPRECATED" 10 "BC_INFO_BUILD_HWID_COMPONENTID" 0 "BC_INFO_DEPRECATED_0" 5 "BC_INFO_DEPRECATED_5" 11 "BC_INFO_PCBAID_ASSYID_USAGEID" 18 "BC_INFO_BOOTLOADER_GITHASH" 3 "BC_INFO_DEPRECATED_3" 15 "BC_INFO_BOOTLOADER_CRC" 4 "BC_INFO_DEPRECATED_4" 16 "BC_INFO_SUBCOMPONENT1" 255 "BC_INFO_END" 9 "BC_INFO_DEPRECATED_9" 13 "BC_INFO_APP_CRC" 2 "BC_INFO_DEPRECATED_2" 23 "BC_INFO_SUBCOMPONENT2" 7 "BC_INFO_DEPRECATED_7" 8 "BC_INFO_DEPRECATED_8" 17 "BC_INFO_APP_GITHASH" ;
VAL_ 1285 SA_infoIndex 26 "Mux26" 27 "Mux27" 11 "Mux11" 32 "Mux32" 25 "Mux25" 31 "Mux31" 0 "Mux0" 30 "Mux30" 29 "Mux29" ;
VAL_ 524 VCRIGHT_tempEvaporatorTarget 255 "SNA" ;
VAL_ 524 VCRIGHT_tempEvaporator 2047 "SNA" ;
VAL_ 1748 PMS_hardwareId 252 "CONFIGURABLE_HWID_PLACEHOLDER" ;
VAL_ 1748 PMS_diNodeBuildType 1 "INFO_PLATFORM_BUILD" 3 "INFO_TRACEABLE_CI_BUILD" 4 "INFO_MFG_BUILD" 2 "INFO_LOCAL_BUILD" 0 "INFO_UNKNOWN_BUILD" ;
VAL_ 1748 PMS_buildType 1 "INFO_PLATFORM_BUILD" 3 "INFO_TRACEABLE_CI_BUILD" 4 "INFO_MFG_BUILD" 2 "INFO_LOCAL_BUILD" 0 "INFO_UNKNOWN_BUILD" ;
VAL_ 1748 PMS_infoIndex 1 "PM_INFO_DEPRECATED_1" 19 "PM_INFO_VERSION_DEPRECATED" 7 "PM_INFO_DEPRECATED_7" 10 "PM_INFO_BUILD_HWID_COMPONENTID" 0 "PM_INFO_DEPRECATED_0" 14 "PM_INFO_BOOTLOADER_SVN" 21 "PM_INFO_DI_BUILD_DATA" 6 "PM_INFO_DEPRECATED_6" 20 "PM_INFO_UDS_PROTOCOL_BOOTCRC" 3 "PM_INFO_DEPRECATED_3" 255 "PM_INFO_END" 9 "PM_INFO_DEPRECATED_9" 2 "PM_INFO_DEPRECATED_2" 13 "PM_INFO_APP_CRC" 8 "PM_INFO_DEPRECATED_8" 17 "PM_INFO_APP_GITHASH" 5 "PM_INFO_DEPRECATED_5" 16 "PM_INFO_SUBCOMPONENT" 18 "PM_INFO_BOOTLOADER_GITHASH" 11 "PM_INFO_PCBAID_ASSYID_USAGEID" 4 "PM_INFO_DEPRECATED_4" 15 "PM_INFO_BOOTLOADER_CRC" ;
VAL_ 929 VCFRONT_pcsEFuseVoltage 1023 "SNA" ;
VAL_ 929 VCFRONT_2RowRightUnbuckled 0 "CHIME_NONE" 1 "CHIME_OCCUPIED_AND_UNBUCKLED" 2 "CHIME_SNA" ;
VAL_ 929 VCFRONT_2RowCenterUnbuckled 0 "CHIME_NONE" 1 "CHIME_OCCUPIED_AND_UNBUCKLED" 2 "CHIME_SNA" ;
VAL_ 929 VCFRONT_2RowLeftUnbuckled 0 "CHIME_NONE" 1 "CHIME_OCCUPIED_AND_UNBUCKLED" 2 "CHIME_SNA" ;
VAL_ 929 VCFRONT_passengerUnbuckled 0 "CHIME_NONE" 1 "CHIME_OCCUPIED_AND_UNBUCKLED" 2 "CHIME_SNA" ;
VAL_ 929 VCFRONT_driverUnbuckled 0 "CHIME_NONE" 1 "CHIME_OCCUPIED_AND_UNBUCKLED" 2 "CHIME_SNA" ;
VAL_ 929 VCFRONT_driverDoorStatus 1 "DOOR_CLOSED" 0 "DOOR_OPEN" ;
VAL_ 929 VCFRONT_driverBuckleStatus 1 "BUCKLED" 0 "UNBUCKLED" ;
VAL_ 929 VCFRONT_12vStatusForDrive 1 "READY_FOR_DRIVE_12V" 2 "EXIT_DRIVE_REQUESTED_12V" 0 "NOT_READY_FOR_DRIVE_12V" ;
VAL_ 929 VCFRONT_diPowerOnState 4 "DI_POWER_GOING_DOWN" 1 "DI_POWERED_ON_FOR_POST_RUN" 2 "DI_POWERED_ON_FOR_STATIONARY_HEAT" 0 "DI_POWERED_OFF" 3 "DI_POWERED_ON_FOR_DRIVE" ;
VAL_ 929 VCFRONT_APGlassHeaterState 2 "HEATER_STATE_OFF" 4 "HEATER_STATE_FAULT" 1 "HEATER_STATE_ON" 0 "HEATER_STATE_SNA" 3 "HEATER_STATE_OFF_UNAVAILABLE" ;
VAL_ 1000 EPBR_matrixIndex 0 "EPBR_AlertMatrix0" 3 "EPBR_AlertMatrix3" 2 "EPBR_AlertMatrix2" 4 "EPBR_AlertMatrix4" 1 "EPBR_AlertMatrix1" ;
VAL_ 648 EPBL_internalCDPRequest 0 "EPB_CDP_NOT_REQUESTED" 1 "EPB_CDP_REQUESTED" ;
VAL_ 648 EPBL_epbmCDPQualified 0 "EPB_EXTERNAL_APPLY_IDLE" 1 "EPB_EXTERNAL_APPLY_VALID" 2 "EPB_EXTERNAL_APPLY_INVALID" ;
VAL_ 648 EPBL_telltaleLocal 0 "EPB_TELLTALE_LAMP_OFF" 2 "EPB_TELLTALE_LAMP_AMBER_ON" 3 "EPB_TELLTALE_LAMP_RED_FLASH" 1 "EPB_TELLTALE_LAMP_RED_ON" 7 "EPB_TELLTALE_SNA" ;
VAL_ 648 EPBL_summonFaultReason 9 "EPB_SUMMONFAULT_VEH_CAN_FAULT" 21 "EPB_SUMMONFAULT_PASSIVE_REQUEST" 26 "EPB_SUMMONFAULT_START_IN_UNAVAILABLE" 5 "EPB_SUMMONFAULT_DI_FAULT" 4 "EPB_SUMMONFAULT_EPBM_MIA" 12 "EPB_SUMMONFAULT_SPEED" 14 "EPB_SUMMONFAULT_PARK_MIA" 19 "EPB_SUMMONFAULT_EPB_FAULT" 25 "EPB_SUMMONFAULT_REMOTE_UNIT_FAULTED" 11 "EPB_SUMMONFAULT_EPBM_REQUEST" 16 "EPB_SUMMONFAULT_PM_REQUEST" 6 "EPB_SUMMONFAULT_DI_APC_FAULT" 13 "EPB_SUMMONFAULT_EXTERNAL" 23 "EPB_SUMMONFAULT_REMOTE_SUMMON_FAULTED" 24 "EPB_SUMMONFAULT_LOCAL_UNIT_FAULTED" 28 "EPB_SUMMONFAULT_REMOTE_DID_NOT_START" 1 "EPB_SUMMONFAULT_DI_MIA" 15 "EPB_SUMMONFAULT_PM_MIA" 27 "EPB_SUMMONFAULT_INVALID_REMOTE_STATE" 0 "EPB_SUMMONFAULT_NONE" 10 "EPB_SUMMONFAULT_EAC_NOT_ALLOWED" 22 "EPB_SUMMONFAULT_EPBREMOTE_MIA" 18 "EPB_SUMMONFAULT_MISMATCH" 3 "EPB_SUMMONFAULT_ESP_MIA" 2 "EPB_SUMMONFAULT_DAS_MIA" 20 "EPB_SUMMONFAULT_DI_STATE_INVALID" 8 "EPB_SUMMONFAULT_ESP_FAULT" 17 "EPB_SUMMONFAULT_OOC" 7 "EPB_SUMMONFAULT_DAS_FAULT" ;
VAL_ 648 EPBL_esmOperationTrigger 20 "EPB_TRIGGER_TIMEOUT" 2 "EPB_TRIGGER_PBUTTON_PRESSED_FAST" 19 "EPB_TRIGGER_SPEED_FAST" 3 "EPB_TRIGGER_PBUTTON_PRESSED_UNKNOWN" 27 "EPB_TRIGGER_EPBM_DISQUALIFIED" 10 "EPB_TRIGGER_WINCHMODE_UNAVAILABLE" 28 "EPB_TRIGGER_ACCELERATION" 12 "EPB_TRIGGER_DIAG_CLOSE" 24 "EPB_TRIGGER_FAULT" 25 "EPB_TRIGGER_SUMMON_FAULT" 30 "EPB_TRIGGER_DRIVER_IS_LEAVING" 18 "EPB_TRIGGER_SPEED_OKAYTOPARK" 1 "EPB_TRIGGER_PBUTTON_PRESSED_OKTOPARK" 4 "EPB_TRIGGER_PBUTTON_RELEASED" 14 "EPB_TRIGGER_DIAG_EXIT" 21 "EPB_TRIGGER_SAVESTATE_ON_BOOT" 6 "EPB_TRIGGER_DI_UNPARK" 23 "EPB_TRIGGER_SUMMON_COMPLETE" 22 "EPB_TRIGGER_REAPPLY" 26 "EPB_TRIGGER_DISQUALIFIED" 16 "EPB_TRIGGER_USER_CANCEL" 13 "EPB_TRIGGER_DIAG_OPEN" 11 "EPB_TRIGGER_SERVICE" 5 "EPB_TRIGGER_ACTIVE_PARK_REQUEST" 15 "EPB_TRIGGER_USER_CONFIRMED" 8 "EPB_TRIGGER_WINCHMODE_EXIT" 9 "EPB_TRIGGER_WINCHMODE_ENTER" 17 "EPB_TRIGGER_SPEED_STOPPED" 0 "EPB_TRIGGER_PBUTTON_PRESSED_STOPPED" 7 "EPB_TRIGGER_TOUCHSCREEN" 29 "EPB_TRIGGER_SYSTEM_APPLY" ;
VAL_ 648 EPBL_csmFaultReason 5 "CSM_FAULT_APPLY_BLOCKED" 19 "CSM_FAULT_EPBM_MIA" 1 "CSM_FAULT_EPBM_DISABLED" 16 "CSM_FAULT_MOTOR_IDLE_FAULT" 8 "CSM_FAULT_TIMEOUT_APPLY_INRUSH" 3 "CSM_FAULT_STATE_MISMATCH" 13 "CSM_FAULT_TIMEOUT_EPBM_CUTOFF" 15 "CSM_FAULT_TIMEOUT_EPBM_START" 2 "CSM_FAULT_EPBM_FAULTED" 4 "CSM_FAULT_TIMEOUT_CALIBRATE" 12 "CSM_FAULT_TIMEOUT_RELEASE_COMPLETE" 17 "CSM_FAULT_MOTOR_ACTIVE_FAULT" 18 "CSM_FAULT_MOTOR_NOT_READY" 11 "CSM_FAULT_TIMEOUT_RELEASE_WAIT_FOR_ENDSTOP" 0 "CSM_FAULT_NONE" 9 "CSM_FAULT_TIMEOUT_WAIT_FOR_CLAMP" 14 "CSM_FAULT_TIMEOUT_NO_RAMP" 10 "CSM_FAULT_TIMEOUT_RELEASE_INRUSH" 21 "CSM_FAULT_REMOTE_MIA" 20 "CSM_FAULT_NVM_MISMATCH" 6 "CSM_FAULT_RELEASE_BLOCKED" 7 "CSM_FAULT_TIMEOUT_APPLY_COMPLETE" ;
VAL_ 648 EPBL_esmCaliperRequest 2 "CSM_RQST_APPLY" 1 "CSM_RQST_NONE" 4 "CSM_RQST_ENDSTOP" 0 "CSM_RQST_INVALID" 3 "CSM_RQST_RELEASE" ;
VAL_ 648 EPBL_summonState 3 "EPB_SUMMON_ACTIVE" 6 "EPB_SUMMON_UNAVAILABLE" 5 "EPB_SUMMON_FAULT" 4 "EPB_SUMMON_COMPLETE" 1 "EPB_SUMMON_IDLE" 2 "EPB_SUMMON_ARMED" 0 "EPB_SUMMON_INIT" ;
VAL_ 648 EPBL_unitFaultStatus 1 "EPB_STATUS_RETRY" 3 "EPB_STATUS_FAULT_IDLE" 0 "EPB_STATUS_NOMINAL" 2 "EPB_STATUS_FAULT" ;
VAL_ 648 EPBL_unitStatus 14 "EPB_STATUS_SUMMON" 1 "EPB_STATUS_OPEN" 9 "EPB_STATUS_DYNAMIC_APPLYING" 21 "EPB_STATUS_COUNT" 12 "EPB_STATUS_PARK_PENDING" 13 "EPB_STATUS_WINCHMODE_PENDING" 6 "EPB_STATUS_WINCHMODE" 3 "EPB_STATUS_PARK" 0 "EPB_STATUS_UNKNOWN" 4 "EPB_STATUS_START" 18 "EPB_STATUS_RELEASING_FOR_EXTERNAL_PARK" 19 "EPB_STATUS_EXTERNAL_PARKING" 17 "EPB_STATUS_EXTERNAL_DYNAMIC" 10 "EPB_STATUS_RELEASING" 15 "EPB_STATUS_SUMMON_RELEASING" 11 "EPB_STATUS_SERVICE_RELEASING" 7 "EPB_STATUS_WINCHMODE_RELEASING" 16 "EPB_STATUS_SUMMON_PARKING" 8 "EPB_STATUS_PARKING" 2 "EPB_STATUS_DYNAMIC" 5 "EPB_STATUS_SERVICE" 20 "EPB_STATUS_DYNAMIC_PARKING" ;
VAL_ 867 CMP_infoAssemblyId 1 "ASSEMBLY1" 255 "ASSEMBLY_SNA" ;
VAL_ 867 CMP_infoBuildType 1 "INFO_PLATFORM_BUILD" 3 "INFO_TRACEABLE_CI_BUILD" 4 "INFO_MFG_BUILD" 2 "INFO_LOCAL_BUILD" 0 "INFO_UNKNOWN_BUILD" ;
VAL_ 867 CMP_infoIndex 25 "INFO_PACKAGE_PN_1_7" 30 "INFO_PACKAGE_SN_8_14" 27 "INFO_PACKAGE_PN_15_20" 0 "INFO_DEPRECATED_0" 29 "INFO_PACKAGE_SN_1_7" 10 "INFO_BUILD_HWID_COMPONENTID" 14 "INFO_BOOTLOADER_SVN" 31 "INFO_SUBCOMPONENT_GITHASH" 19 "INFO_VERSION_DEPRECATED" 7 "INFO_DEPRECATED_7" 255 "INFO_END" 9 "INFO_DEPRECATED_9" 6 "INFO_DEPRECATED_6" 20 "INFO_UDS_PROTOCOL_BOOTCRC" 3 "INFO_DEPRECATED_3" 22 "INFO_VARIANTCRC" 17 "INFO_APP_GITHASH" 8 "INFO_DEPRECATED_8" 26 "INFO_PACKAGE_PN_8_14" 5 "INFO_DEPRECATED_5" 16 "INFO_SUBCOMPONENT" 13 "INFO_APP_CRC" 2 "INFO_DEPRECATED_2" 4 "INFO_DEPRECATED_4" 15 "INFO_BOOTLOADER_CRC" 1 "INFO_DEPRECATED_1" 11 "INFO_PCBAID_ASSYID_USAGEID" 18 "INFO_BOOTLOADER_GITHASH" ;
VAL_ 796 CC_line3Voltage 511 "SNA" ;
VAL_ 796 CC_line2Voltage 511 "SNA" ;
VAL_ 796 CC_gridGrounding 0 "CC_GRID_GROUNDING_TN_TT" 1 "CC_GRID_GROUNDING_IT_SplitPhase" 2 "CC_GRID_GROUNDING_SNA" ;
VAL_ 796 CC_line1Voltage 511 "SNA" ;
VAL_ 796 CC_numPhases 0 "SNA" ;
VAL_ 796 CC_pilotState 1 "CC_PILOT_STATE_IDLE" 3 "CC_PILOT_STATE_SNA" 2 "CC_PILOT_STATE_FAULTED" 0 "CC_PILOT_STATE_READY" ;
VAL_ 796 CC_currentLimit 255 "SNA" ;
VAL_ 737 VCFRONT_homelinkCommStatus 1 "HOMELINK_COMM_STATUS_OFF" 3 "HOMELINK_COMM_STATUS_FAULT" 2 "HOMELINK_COMM_STATUS_ON" 0 "HOMELINK_COMM_STATUS_SNA" ;
VAL_ 737 VCFRONT_pressureRefrigDischarge 255 "SNA" ;
VAL_ 737 VCFRONT_pressureRefrigSuction 127 "SNA" ;
VAL_ 737 VCFRONT_airCompressorStatus 5 "VCFRONT_AIR_COMPRESSOR_STATUS_RETRY_AVAILABLE" 3 "VCFRONT_AIR_COMPRESSOR_STATUS_TURNING_ON" 4 "VCFRONT_AIR_COMPRESSOR_STATUS_FAULT" 2 "VCFRONT_AIR_COMPRESSOR_STATUS_TURNING_OFF" 7 "VCFRONT_AIR_COMPRESSOR_STATUS_SNA" 1 "VCFRONT_AIR_COMPRESSOR_STATUS_ON" 0 "VCFRONT_AIR_COMPRESSOR_STATUS_OFF" ;
VAL_ 737 VCFRONT_AS8510Voltage 4095 "SNA" ;
VAL_ 737 VCFRONT_crashState 2 "CRASH_STATE_SEVERE" 0 "CRASH_STATE_IDLE" 1 "CRASH_STATE_MINOR" ;
VAL_ 737 VCFRONT_batterySMState 2 "BATTERY_SM_STATE_DISCHARGE" 7 "BATTERY_SM_STATE_FAULT" 0 "BATTERY_SM_STATE_INIT" 3 "BATTERY_SM_STATE_STANDBY" 4 "BATTERY_SM_STATE_RESISTANCE_ESTIMATION" 5 "BATTERY_SM_STATE_OTA_STANDBY" 6 "BATTERY_SM_STATE_DISCONNECTED_BATTERY_TEST" 1 "BATTERY_SM_STATE_CHARGE" ;
VAL_ 737 VCFRONT_crashDetectedType 1 "CRASH_DETECTED_TYPE_MINOR" 0 "CRASH_DETECTED_TYPE_NONE" 2 "CRASH_DETECTED_TYPE_SEVERE" ;
VAL_ 737 VCFRONT_vehicleStatusDBG 5 "VEHICLE_STATUS_SLEEP_SHUTDOWN" 12 "VEHICLE_STATUS_CONDITIONING" 9 "VEHICLE_STATUS_HV_UP_STANDBY" 13 "VEHICLE_STATUS_DRIVE" 6 "VEHICLE_STATUS_SLEEP_STANDBY" 4 "VEHICLE_STATUS_SYSTEM_CHECKS" 10 "VEHICLE_STATUS_ACCESSORY" 14 "VEHICLE_STATUS_CRASH" 2 "VEHICLE_STATUS_SILENT_WAKE" 16 "VEHICLE_STATUS_TURN_ON_RAILS" 1 "VEHICLE_STATUS_LOW_POWER_STANDBY" 8 "VEHICLE_STATUS_LV_AWAKE" 0 "VEHICLE_STATUS_INIT" 15 "VEHICLE_STATUS_OTA" 3 "VEHICLE_STATUS_BATTERY_POST_WAKE" 7 "VEHICLE_STATUS_LV_SHUTDOWN" 17 "VEHICLE_STATUS_RESET" 11 "VEHICLE_STATUS_ACCESSORY_PLUS" ;
VAL_ 737 VCFRONT_wiperState 2 "WIPER_STATE_FAULT" 12 "WIPER_STATE_INT_AUTO_HIGH" 9 "WIPER_STATE_CONT_FAST" 8 "WIPER_STATE_INTERMITTENT_LOW" 7 "WIPER_STATE_INTERMITTENT_HIGH" 0 "WIPER_STATE_SNA" 3 "WIPER_STATE_DELAYED_REST" 10 "WIPER_STATE_CONT_SLOW" 6 "WIPER_STATE_MOMENTARY_WIPE" 1 "WIPER_STATE_SERVICE" 5 "WIPER_STATE_WASH" 4 "WIPER_STATE_PARK" 11 "WIPER_STATE_INT_AUTO_LOW" ;
VAL_ 737 VCFRONT_vbatMonitorVoltage 4095 "SNA" ;
VAL_ 737 VCFRONT_iBoosterStateDBG 3 "IBOOSTER_WRITING_DATA_SHUTDOWN" 1 "IBOOSTER_ON" 0 "IBOOSTER_OFF" 4 "IBOOSTER_FORCE_OFF" 2 "IBOOSTER_GOING_DOWN" ;
VAL_ 737 VCFRONT_wiperPosition 0 "WIPER_POSITION_SNA" 1 "WIPER_POSITION_SERVICE" 2 "WIPER_POSITION_DEPRESSED_PARK" 3 "WIPER_POSITION_DELAYED_REST" 4 "WIPER_POSITION_WIPING" ;
VAL_ 737 VCFRONT_wiperSpeed 2 "WIPER_SPEED_1" 0 "WIPER_SPEED_SNA" 7 "WIPER_SPEED_LOW" 8 "WIPER_SPEED_HIGH" 3 "WIPER_SPEED_2" 5 "WIPER_SPEED_4" 4 "WIPER_SPEED_3" 6 "WIPER_SPEED_5" 1 "WIPER_SPEED_OFF" ;
VAL_ 737 VCFRONT_frunkLatchStatus 8 "LATCH_FAULT" 2 "LATCH_CLOSED" 1 "LATCH_OPENED" 3 "LATCH_CLOSING" 7 "LATCH_DEFAULT" 4 "LATCH_OPENING" 5 "LATCH_AJAR" 6 "LATCH_TIMEOUT" 0 "LATCH_SNA" ;
VAL_ 737 VCFRONT_statusIndex 5 "VCF_STS_IDX_INVALID" 4 "VCF_STS_IDX_LV_BATTERY_DEBUG" 0 "VCF_STS_IDX_BODY_CONTROLS" 3 "VCF_STS_IDX_REFRIGERANT_SYSTEM" 2 "VCF_STS_IDX_HOMELINK" 1 "VCF_STS_IDX_VEHICLE_AND_RAILS" ;
VAL_ 562 BMS_internalHvilSenseV 65535 "SNA" ;
VAL_ 562 BMS_packContactorRequest 4 "SET_REQUEST_CLOSE_NEGATIVE_ONLY" 1 "SET_REQUEST_CLOSE" 3 "SET_REQUEST_OPEN_IMMEDIATELY" 2 "SET_REQUEST_OPEN" 0 "SET_REQUEST_SNA" 5 "SET_REQUEST_CLOSE_POSITIVE_ONLY" ;
VAL_ 562 BMS_fcContactorRequest 4 "SET_REQUEST_CLOSE_NEGATIVE_ONLY" 1 "SET_REQUEST_CLOSE" 3 "SET_REQUEST_OPEN_IMMEDIATELY" 2 "SET_REQUEST_OPEN" 0 "SET_REQUEST_SNA" 5 "SET_REQUEST_CLOSE_POSITIVE_ONLY" ;
VAL_ 825 VCSEC_keyChannelIndexed 15 "SNA" ;
VAL_ 825 VCSEC_simpleLockStatus 2 "SIMPLE_LOCK_STATUS_LOCKED" 0 "SIMPLE_LOCK_STATUS_SNA" 1 "SIMPLE_LOCK_STATUS_UNLOCKED" ;
VAL_ 825 VCSEC_lockIndicationRequest 4 "INDICATION_HOLD" 3 "INDICATION_TRIPLE" 2 "INDICATION_DOUBLE" 1 "INDICATION_SINGLE" 0 "INDICATION_NONE_SNA" ;
VAL_ 825 VCSEC_immobilizerState 5 "IMMOBILIZER_STATE_SEND_NO_GO_AUTH_RESPONSE" 4 "IMMOBILIZER_STATE_SEND_AUTH_RESPONSE" 3 "IMMOBILIZER_STATE_ENCRYPT" 2 "IMMOBILIZER_STATE_ENCRYPT_BEGIN" 1 "IMMOBILIZER_STATE_PREPARE" 0 "IMMOBILIZER_STATE_IDLE" ;
VAL_ 825 VCSEC_alarmStatus 2 "ALARM_STATUS_PARTIAL_ARMED" 5 "ALARM_STATUS_TRIGGERED_FLASH_INACTIVE" 7 "ALARM_STATUS_DEFAULT" 4 "ALARM_STATUS_ERROR" 3 "ALARM_STATUS_TRIGGERED_FLASH_ACTIVE" 1 "ALARM_STATUS_ARMED" 15 "ALARM_STATUS_SNA" 6 "ALARM_STATUS_IMMINENT" 0 "ALARM_STATUS_DISARMED" ;
VAL_ 825 VCSEC_MCUCommandType 1 "MCU_COMMAND_REMOTE_UNLOCK" 0 "MCU_COMMAND_NONE" 5 "MCU_COMMAND_COMMAND5" 4 "MCU_COMMAND_COMMAND4" 2 "MCU_COMMAND_REMOTE_START" 3 "MCU_COMMAND_COMMAND3" ;
VAL_ 825 VCSEC_frunkRequest 2 "CLOSURE_REQUEST_SNA" 0 "CLOSURE_REQUEST_NONE" 1 "CLOSURE_REQUEST_OPEN" ;
VAL_ 825 VCSEC_trunkRequest 2 "CLOSURE_REQUEST_SNA" 0 "CLOSURE_REQUEST_NONE" 1 "CLOSURE_REQUEST_OPEN" ;
VAL_ 825 VCSEC_summonRequest 5 "SUMMON_REQUEST_SNA" 0 "SUMMON_REQUEST_IDLE" 1 "SUMMON_REQUEST_PRIME" 2 "SUMMON_REQUEST_FORWARD" 3 "SUMMON_REQUEST_BACKWARD" 4 "SUMMON_REQUEST_STOP" ;
VAL_ 825 VCSEC_lockRequestType 13 "LOCK_REQUEST_ACTIVE_REMOTE_UNLOCK" 17 "LOCK_REQUEST_ACTIVE_BLE_UNLOCK" 15 "LOCK_REQUEST_ACTIVE_NFC_UNLOCK" 0 "LOCK_REQUEST_NONE" 12 "LOCK_REQUEST_ACTIVE_UI_BUTTON_LOCK" 16 "LOCK_REQUEST_ACTIVE_NFC_LOCK" 10 "LOCK_REQUEST_CRASH_UNLOCK" 6 "LOCK_REQUEST_PASSIVE_BLE_EXTERIOR_CHARGEHANDLEBUTTON_UNLOCK" 18 "LOCK_REQUEST_ACTIVE_BLE_LOCK" 19 "LOCK_REQUEST_PASSIVE_INTERNAL_LOCK_PROMOTION" 5 "LOCK_REQUEST_PASSIVE_BLE_WALKUP_UNLOCK" 4 "LOCK_REQUEST_PASSIVE_DRIVE_AWAY_LOCK" 2 "LOCK_REQUEST_PASSIVE_PARKBUTTON_UNLOCK" 7 "LOCK_REQUEST_PASSIVE_BLE_EXTERIOR_HANDLE_UNLOCK" 1 "LOCK_REQUEST_PASSIVE_SHIFT_TO_P_UNLOCK" 8 "LOCK_REQUEST_PASSIVE_BLE_INTERIOR_HANDLE_UNLOCK" 3 "LOCK_REQUEST_PASSIVE_INTERNAL_HANDLE_UNLOCK" 11 "LOCK_REQUEST_ACTIVE_UI_BUTTON_UNLOCK" 14 "LOCK_REQUEST_ACTIVE_REMOTE_LOCK" 9 "LOCK_REQUEST_PASSIVE_BLE_LOCK" ;
VAL_ 825 VCSEC_trunkLockStatus 0 "CLOSURE_UNLOCKED" 1 "CLOSURE_LOCKED" ;
VAL_ 825 VCSEC_rightRearLockStatus 0 "CLOSURE_UNLOCKED" 1 "CLOSURE_LOCKED" ;
VAL_ 825 VCSEC_rightFrontLockStatus 0 "CLOSURE_UNLOCKED" 1 "CLOSURE_LOCKED" ;
VAL_ 825 VCSEC_leftRearLockStatus 0 "CLOSURE_UNLOCKED" 1 "CLOSURE_LOCKED" ;
VAL_ 825 VCSEC_leftFrontLockStatus 0 "CLOSURE_UNLOCKED" 1 "CLOSURE_LOCKED" ;
VAL_ 825 VCSEC_chargePortLockStatus 0 "CLOSURE_UNLOCKED" 1 "CLOSURE_LOCKED" ;
VAL_ 825 VCSEC_authenticationStatus 2 "AUTHENTICATION_AUTHENTICATED_FOR_DRIVE" 0 "AUTHENTICATION_NONE" 1 "AUTHENTICATION_AUTHENTICATED_FOR_UNLOCK" ;
VAL_ 825 VCSEC_vehicleLockStatus 14 "LOCK_STATUS_PASSIVE_INTERNAL_UNLOCKED" 13 "LOCK_STATUS_CRASH_UNLOCKED" 5 "LOCK_STATUS_PASSIVE_BLE_LOCKED" 12 "LOCK_STATUS_ACTIVE_REMOTE_LOCKED" 6 "LOCK_STATUS_ACTIVE_SELECTIVE_UNLOCKED" 4 "LOCK_STATUS_PASSIVE_BLE_UNLOCKED" 11 "LOCK_STATUS_ACTIVE_REMOTE_UNLOCKED" 7 "LOCK_STATUS_ACTIVE_BLE_UNLOCKED" 1 "LOCK_STATUS_ACTIVE_NFC_UNLOCKED" 3 "LOCK_STATUS_PASSIVE_SELECTIVE_UNLOCKED" 2 "LOCK_STATUS_ACTIVE_NFC_LOCKED" 8 "LOCK_STATUS_ACTIVE_BLE_LOCKED" 10 "LOCK_STATUS_ACTIVE_UI_LOCKED" 0 "LOCK_STATUS_SNA" 9 "LOCK_STATUS_ACTIVE_UI_UNLOCKED" 15 "LOCK_STATUS_PASSIVE_INTERNAL_LOCKED" ;
VAL_ 516 PCS_hwVariantType 1 "PCS_32A_SINGLE_PHASE_VARIANT" 0 "PCS_48A_SINGLE_PHASE_VARIANT" 2 "PCS_THREE_PHASES_VARIANT" ;
VAL_ 516 PCS_gridConfig 2 "GRID_CONFIG_THREE_PHASE" 3 "GRID_CONFIG_THREE_PHASE_DELTA" 1 "GRID_CONFIG_SINGLE_PHASE" 0 "GRID_CONFIG_SNA" ;
VAL_ 516 PCS_chargeStatus 2 "CHARGE_FAULTED" 0 "CHARGE_IDLE" 1 "CHARGE_ENABLED" ;
VAL_ 516 PCS_chgMainState 3 "PCS_CHG_STATE_WAIT_FOR_LINE_VOLTAGE" 0 "PCS_CHG_STATE_INIT" 7 "PCS_CHG_STATE_SHUTDOWN" 5 "PCS_CHG_STATE_SYSTEM_CONFIG" 8 "PCS_CHG_STATE_FAULTED" 4 "PCS_CHG_STATE_QUALIFY_LINE_CONFIG" 6 "PCS_CHG_STATE_ENABLE" 1 "PCS_CHG_STATE_IDLE" 9 "PCS_CHG_STATE_CLEAR_FAULTS" 2 "PCS_CHG_STATE_STARTUP" ;
VAL_ 531 UI_cruiseSpeedCommand 1 "CRUISE_SPEED_INC_SHORT" 2 "CRUISE_SPEED_INC_LONG" 5 "CRUISE_SPEED_SNAP" 0 "CRUISE_SPEED_IDLE" 4 "CRUISE_SPEED_DEC_LONG" 3 "CRUISE_SPEED_DEC_SHORT" ;
VAL_ 531 UI_speedLimitTick 255 "SNA" ;
VAL_ 1493 DIS_torqueWearTotal 255 "SNA" ;
VAL_ 1493 DIS_IGBTJunctTemp 255 "SNA" ;
VAL_ 1849 VCSEC_CPULoad1000msTask 255 "SNA" ;
VAL_ 1849 VCSEC_CPULoad100msTask 255 "SNA" ;
VAL_ 1849 VCSEC_CPULoad10msTask 255 "SNA" ;
VAL_ 1849 VCSEC_CPULoad1msTask 255 "SNA" ;
VAL_ 1849 VCSEC_CPULoadTotal 255 "SNA" ;
VAL_ 821 DIS_hardwareId 252 "CONFIGURABLE_HWID_PLACEHOLDER" ;
VAL_ 821 DIS_oilPumpBuildType 1 "INFO_PLATFORM_BUILD" 3 "INFO_TRACEABLE_CI_BUILD" 4 "INFO_MFG_BUILD" 2 "INFO_LOCAL_BUILD" 0 "INFO_UNKNOWN_BUILD" ;
VAL_ 821 DIS_buildType 1 "INFO_PLATFORM_BUILD" 3 "INFO_TRACEABLE_CI_BUILD" 4 "INFO_MFG_BUILD" 2 "INFO_LOCAL_BUILD" 0 "INFO_UNKNOWN_BUILD" ;
VAL_ 821 DIS_infoIndex 25 "INFO_PACKAGE_PN_1_7" 30 "INFO_PACKAGE_SN_8_14" 27 "INFO_PACKAGE_PN_15_20" 0 "INFO_DEPRECATED_0" 29 "INFO_PACKAGE_SN_1_7" 10 "INFO_BUILD_HWID_COMPONENTID" 14 "INFO_BOOTLOADER_SVN" 31 "INFO_SUBCOMPONENT_GITHASH" 19 "INFO_VERSION_DEPRECATED" 7 "INFO_DEPRECATED_7" 255 "INFO_END" 9 "INFO_DEPRECATED_9" 6 "INFO_DEPRECATED_6" 20 "INFO_UDS_PROTOCOL_BOOTCRC" 3 "INFO_DEPRECATED_3" 22 "INFO_VARIANTCRC" 17 "INFO_APP_GITHASH" 8 "INFO_DEPRECATED_8" 26 "INFO_PACKAGE_PN_8_14" 5 "INFO_DEPRECATED_5" 16 "INFO_SUBCOMPONENT" 13 "INFO_APP_CRC" 2 "INFO_DEPRECATED_2" 4 "INFO_DEPRECATED_4" 15 "INFO_BOOTLOADER_CRC" 1 "INFO_DEPRECATED_1" 11 "INFO_PCBAID_ASSYID_USAGEID" 18 "INFO_BOOTLOADER_GITHASH" ;
VAL_ 579 VCRIGHT_hvacSecondRowState 2 "LOW" 0 "AUTO" 3 "MED" 1 "OFF" 4 "HIGH" ;
VAL_ 579 VCRIGHT_hvacPowerState 2 "PRECONDITION" 4 "OVERHEAT_PROTECT" 3 "OVERHEAT_PROTECT_FANONLY" 0 "OFF" 1 "ON" ;
VAL_ 579 VCRIGHT_hvacACRunning 0 "OFF" 1 "ON" ;
VAL_ 579 VCRIGHT_hvacRecirc 0 "AUTO" 1 "RECIRC" 2 "FRESH" ;
VAL_ 579 VCRIGHT_hvacBlowerSegment 7 "7" 1 "1" 4 "4" 0 "OFF" 2 "2" 5 "5" 8 "8" 11 "11" 3 "3" 6 "6" 9 "9" 10 "10" ;
VAL_ 579 VCRIGHT_hvacAirDistributionMode 6 "DEFROST_PANEL" 5 "DEFROST_FLOOR" 0 "NONE" 4 "DEFROST" 1 "FLOOR" 7 "DEFROST_PANEL_FLOOR" 3 "PANEL_FLOOR" 2 "PANEL" ;
VAL_ 822 DI_sysRegenPowerRated 255 "SNA" ;
VAL_ 822 DI_sysDrivePowerRated 511 "SNA" ;
VAL_ 1810 BMS_thermistorStatus12 0 "SENSOR_SNA" 1 "SENSOR_BAD" 2 "SENSOR_NOMINAL" 3 "SENSOR_BYPASSED" ;
VAL_ 1810 BMS_thermistorStatus18 0 "SENSOR_SNA" 1 "SENSOR_BAD" 2 "SENSOR_NOMINAL" 3 "SENSOR_BYPASSED" ;
VAL_ 1810 BMS_thermistorStatus6 0 "SENSOR_SNA" 1 "SENSOR_BAD" 2 "SENSOR_NOMINAL" 3 "SENSOR_BYPASSED" ;
VAL_ 1810 BMS_thermistorStatus3 0 "SENSOR_SNA" 1 "SENSOR_BAD" 2 "SENSOR_NOMINAL" 3 "SENSOR_BYPASSED" ;
VAL_ 1810 BMS_thermistorStatus15 0 "SENSOR_SNA" 1 "SENSOR_BAD" 2 "SENSOR_NOMINAL" 3 "SENSOR_BYPASSED" ;
VAL_ 1810 BMS_thermistorStatus9 0 "SENSOR_SNA" 1 "SENSOR_BAD" 2 "SENSOR_NOMINAL" 3 "SENSOR_BYPASSED" ;
VAL_ 1810 BMS_thermistorStatus14 0 "SENSOR_SNA" 1 "SENSOR_BAD" 2 "SENSOR_NOMINAL" 3 "SENSOR_BYPASSED" ;
VAL_ 1810 BMS_thermistorStatus2 0 "SENSOR_SNA" 1 "SENSOR_BAD" 2 "SENSOR_NOMINAL" 3 "SENSOR_BYPASSED" ;
VAL_ 1810 BMS_thermistorStatus11 0 "SENSOR_SNA" 1 "SENSOR_BAD" 2 "SENSOR_NOMINAL" 3 "SENSOR_BYPASSED" ;
VAL_ 1810 BMS_thermistorStatus8 0 "SENSOR_SNA" 1 "SENSOR_BAD" 2 "SENSOR_NOMINAL" 3 "SENSOR_BYPASSED" ;
VAL_ 1810 BMS_thermistorStatus5 0 "SENSOR_SNA" 1 "SENSOR_BAD" 2 "SENSOR_NOMINAL" 3 "SENSOR_BYPASSED" ;
VAL_ 1810 BMS_thermistorStatus17 0 "SENSOR_SNA" 1 "SENSOR_BAD" 2 "SENSOR_NOMINAL" 3 "SENSOR_BYPASSED" ;
VAL_ 1810 BMS_thermistorStatus4 0 "SENSOR_SNA" 1 "SENSOR_BAD" 2 "SENSOR_NOMINAL" 3 "SENSOR_BYPASSED" ;
VAL_ 1810 BMS_thermistorStatus1 0 "SENSOR_SNA" 1 "SENSOR_BAD" 2 "SENSOR_NOMINAL" 3 "SENSOR_BYPASSED" ;
VAL_ 1810 BMS_thermistorStatus13 0 "SENSOR_SNA" 1 "SENSOR_BAD" 2 "SENSOR_NOMINAL" 3 "SENSOR_BYPASSED" ;
VAL_ 1810 BMS_thermistorStatus7 0 "SENSOR_SNA" 1 "SENSOR_BAD" 2 "SENSOR_NOMINAL" 3 "SENSOR_BYPASSED" ;
VAL_ 1810 BMS_thermistorStatus10 0 "SENSOR_SNA" 1 "SENSOR_BAD" 2 "SENSOR_NOMINAL" 3 "SENSOR_BYPASSED" ;
VAL_ 1810 BMS_thermistorStatus16 0 "SENSOR_SNA" 1 "SENSOR_BAD" 2 "SENSOR_NOMINAL" 3 "SENSOR_BYPASSED" ;
VAL_ 1810 BMS_packTemperatureMultiplexer 4 "Mux4" 2 "Mux2" 5 "Mux5" 3 "Mux3" 0 "Mux0" 1 "Mux1" ;
VAL_ 595 UI_ventPanelRightLateralMode 1 "SPLIT" 0 "SINGLE" ;
VAL_ 595 UI_ventPanelLeftLateralMode 1 "SPLIT" 0 "SINGLE" ;
VAL_ 1992 EPBL_infoAssemblyId 1 "ASSEMBLY1" 255 "ASSEMBLY_SNA" ;
VAL_ 1992 EPBL_infoBuildType 1 "INFO_PLATFORM_BUILD" 3 "INFO_TRACEABLE_CI_BUILD" 4 "INFO_MFG_BUILD" 2 "INFO_LOCAL_BUILD" 0 "INFO_UNKNOWN_BUILD" ;
VAL_ 1992 EPBL_infoIndex 14 "BC_INFO_BOOTLOADER_SVN" 6 "BC_INFO_DEPRECATED_6" 20 "BC_INFO_UDS_PROTOCOL_BOOTCRC" 24 "BC_INFO_SUBCOMPONENT3" 1 "BC_INFO_DEPRECATED_1" 31 "BC_INFO_SUBCOMPONENT4" 19 "BC_INFO_VERSION_DEPRECATED" 10 "BC_INFO_BUILD_HWID_COMPONENTID" 0 "BC_INFO_DEPRECATED_0" 5 "BC_INFO_DEPRECATED_5" 11 "BC_INFO_PCBAID_ASSYID_USAGEID" 18 "BC_INFO_BOOTLOADER_GITHASH" 3 "BC_INFO_DEPRECATED_3" 15 "BC_INFO_BOOTLOADER_CRC" 4 "BC_INFO_DEPRECATED_4" 16 "BC_INFO_SUBCOMPONENT1" 255 "BC_INFO_END" 9 "BC_INFO_DEPRECATED_9" 13 "BC_INFO_APP_CRC" 2 "BC_INFO_DEPRECATED_2" 23 "BC_INFO_SUBCOMPONENT2" 7 "BC_INFO_DEPRECATED_7" 8 "BC_INFO_DEPRECATED_8" 17 "BC_INFO_APP_GITHASH" ;
VAL_ 707 VCRIGHT_windowStopReqReasonRR 5 "WINDOW_STOP_REQUEST_REASON_STALL" 7 "WINDOW_STOP_REQUEST_REASON_FULL_OPEN_SOFT_STOP" 8 "WINDOW_STOP_REQUEST_REASON_EXTERNAL_REQUEST" 3 "WINDOW_STOP_REQUEST_REASON_REAR_LOCKOUT" 6 "WINDOW_STOP_REQUEST_REASON_STATE_TIMEOUT" 4 "WINDOW_STOP_REQUEST_REASON_THERMAL" 0 "WINDOW_STOP_REQUEST_REASON_NONE" 1 "WINDOW_STOP_REQUEST_REASON_SWITCH_CANCEL_AUTO_MOVEMENT" 2 "WINDOW_STOP_REQUEST_REASON_SWITCH_RELEASED" ;
VAL_ 707 VCRIGHT_windowStopReasonRR 6 "WINDOW_STOP_REASON_STATE_TIMEOUT" 0 "WINDOW_STOP_REASON_NONE" 3 "WINDOW_STOP_REASON_TARGET_REACHED" 1 "WINDOW_STOP_REASON_DOOR_OPEN_TRIM_PROTECT" 4 "WINDOW_STOP_REASON_STOP_REQUEST" 2 "WINDOW_STOP_REASON_NEW_REQUEST" 5 "WINDOW_STOP_REASON_FULL_OPEN_SOFT_STOP" ;
VAL_ 707 VCRIGHT_windowThermalModeRR 0 "WINDOW_THERMAL_MODE_SNA" 2 "WINDOW_THERMAL_MODE_ALERT" 1 "WINDOW_THERMAL_MODE_NORMAL" 3 "WINDOW_THERMAL_MODE_CRITICAL" ;
VAL_ 707 VCRIGHT_windowStateRR 8 "WINDOW_STATE_BACKDRIVE" 0 "WINDOW_STATE_STOPPED" 5 "WINDOW_STATE_SHORT_DROP_REVERSE" 4 "WINDOW_STATE_SHORT_DROP" 3 "WINDOW_STATE_BACKOFF" 7 "WINDOW_STATE_MOVING_AUTO_DOWN" 2 "WINDOW_STATE_MOVING_DOWN" 1 "WINDOW_STATE_MOVING_UP" 6 "WINDOW_STATE_MOVING_AUTO_UP" ;
VAL_ 707 VCRIGHT_windowStopReqReasonRF 5 "WINDOW_STOP_REQUEST_REASON_STALL" 7 "WINDOW_STOP_REQUEST_REASON_FULL_OPEN_SOFT_STOP" 8 "WINDOW_STOP_REQUEST_REASON_EXTERNAL_REQUEST" 3 "WINDOW_STOP_REQUEST_REASON_REAR_LOCKOUT" 6 "WINDOW_STOP_REQUEST_REASON_STATE_TIMEOUT" 4 "WINDOW_STOP_REQUEST_REASON_THERMAL" 0 "WINDOW_STOP_REQUEST_REASON_NONE" 1 "WINDOW_STOP_REQUEST_REASON_SWITCH_CANCEL_AUTO_MOVEMENT" 2 "WINDOW_STOP_REQUEST_REASON_SWITCH_RELEASED" ;
VAL_ 707 VCRIGHT_windowStopReasonRF 6 "WINDOW_STOP_REASON_STATE_TIMEOUT" 0 "WINDOW_STOP_REASON_NONE" 3 "WINDOW_STOP_REASON_TARGET_REACHED" 1 "WINDOW_STOP_REASON_DOOR_OPEN_TRIM_PROTECT" 4 "WINDOW_STOP_REASON_STOP_REQUEST" 2 "WINDOW_STOP_REASON_NEW_REQUEST" 5 "WINDOW_STOP_REASON_FULL_OPEN_SOFT_STOP" ;
VAL_ 707 VCRIGHT_windowThermalModeRF 0 "WINDOW_THERMAL_MODE_SNA" 2 "WINDOW_THERMAL_MODE_ALERT" 1 "WINDOW_THERMAL_MODE_NORMAL" 3 "WINDOW_THERMAL_MODE_CRITICAL" ;
VAL_ 707 VCRIGHT_windowStateRF 8 "WINDOW_STATE_BACKDRIVE" 0 "WINDOW_STATE_STOPPED" 5 "WINDOW_STATE_SHORT_DROP_REVERSE" 4 "WINDOW_STATE_SHORT_DROP" 3 "WINDOW_STATE_BACKOFF" 7 "WINDOW_STATE_MOVING_AUTO_DOWN" 2 "WINDOW_STATE_MOVING_DOWN" 1 "WINDOW_STATE_MOVING_UP" 6 "WINDOW_STATE_MOVING_AUTO_UP" ;
VAL_ 707 VCRIGHT_windowStatusIndex 0 "Mux0" 1 "Mux1" ;
VAL_ 291 VCRIGHT_rearHandleDebounceStatus 4 "EXTERIOR_HANDLE_STATUS_DISCONNECTED" 5 "EXTERIOR_HANDLE_STATUS_FAULT" 1 "EXTERIOR_HANDLE_STATUS_INDETERMINATE" 3 "EXTERIOR_HANDLE_STATUS_ACTIVE" 0 "EXTERIOR_HANDLE_STATUS_SNA" 2 "EXTERIOR_HANDLE_STATUS_NOT_ACTIVE" ;
VAL_ 291 VCRIGHT_frontHandleDebounceStatu 4 "EXTERIOR_HANDLE_STATUS_DISCONNECTED" 5 "EXTERIOR_HANDLE_STATUS_FAULT" 1 "EXTERIOR_HANDLE_STATUS_INDETERMINATE" 3 "EXTERIOR_HANDLE_STATUS_ACTIVE" 0 "EXTERIOR_HANDLE_STATUS_SNA" 2 "EXTERIOR_HANDLE_STATUS_NOT_ACTIVE" ;
VAL_ 291 VCRIGHT_rearHandleRawStatus 4 "EXTERIOR_HANDLE_STATUS_DISCONNECTED" 5 "EXTERIOR_HANDLE_STATUS_FAULT" 1 "EXTERIOR_HANDLE_STATUS_INDETERMINATE" 3 "EXTERIOR_HANDLE_STATUS_ACTIVE" 0 "EXTERIOR_HANDLE_STATUS_SNA" 2 "EXTERIOR_HANDLE_STATUS_NOT_ACTIVE" ;
VAL_ 291 VCRIGHT_frontHandleRawStatus 4 "EXTERIOR_HANDLE_STATUS_DISCONNECTED" 5 "EXTERIOR_HANDLE_STATUS_FAULT" 1 "EXTERIOR_HANDLE_STATUS_INDETERMINATE" 3 "EXTERIOR_HANDLE_STATUS_ACTIVE" 0 "EXTERIOR_HANDLE_STATUS_SNA" 2 "EXTERIOR_HANDLE_STATUS_NOT_ACTIVE" ;
VAL_ 291 VCRIGHT_rearDoorState 2 "DOOR_STATE_WAIT_FOR_SHORT_DROP" 1 "DOOR_STATE_CLOSED" 4 "DOOR_STATE_OPEN_OR_AJAR" 3 "DOOR_STATE_RELEASING_LATCH" 0 "DOOR_STATE_UNKNOWN" ;
VAL_ 291 VCRIGHT_frontDoorState 2 "DOOR_STATE_WAIT_FOR_SHORT_DROP" 1 "DOOR_STATE_CLOSED" 4 "DOOR_STATE_OPEN_OR_AJAR" 3 "DOOR_STATE_RELEASING_LATCH" 0 "DOOR_STATE_UNKNOWN" ;
VAL_ 1349 VCFRONT_vcrightVoltage 4095 "SNA" ;
VAL_ 1349 VCFRONT_vcleftVoltage 4095 "SNA" ;
VAL_ 1349 VCFRONT_vcrightCurrent 4095 "SNA" ;
VAL_ 1349 VCFRONT_loadShedPumps_duty 127 "SNA" ;
VAL_ 1349 VCFRONT_loadShedBlower_duty 127 "SNA" ;
VAL_ 1349 VCFRONT_vcleftCurrent 4095 "SNA" ;
VAL_ 1349 VCFRONT_loadShedSMState 0 "LOADSHED_SM_STATE_INIT" 3 "LOADSHED_SM_STATE_CRITICAL" 1 "LOADSHED_SM_STATE_IDLE" 2 "LOADSHED_SM_STATE_PARTIAL" ;
VAL_ 1349 VCFRONT_systemStatusMuxIndex 0 "SYSTEM_DATA" 1 "LOADSHED_REQUESTS" ;
VAL_ 1053 CP_nmKeepAwakeReason 1 "CHARGING" 0 "CP_KEEPAWAKE_REASON_NONE_SNA" 2 "OPERATING_DOOR_LATCH" 3 "CABLE_IN" 4 "SUPERCHARGER_CONNECTED" ;
VAL_ 1053 CP_nmWakeUpReason 2 "WAKEUP_REASON_PROXIMITY" 4 "WAKEUP_REASON_UHF" 3 "WAKEUP_REASON_PILOT" 1 "WAKEUP_REASON_DOOR_PUSHED" 0 "WAKEUP_REASON_NONE" ;
VAL_ 1793 VCFRONT_pumpBatteryITerm 255 "SNA" ;
VAL_ 1793 VCFRONT_pumpPowertrainITerm 255 "SNA" ;
VAL_ 1793 VCFRONT_radiatorFanITerm 255 "SNA" ;
VAL_ 1793 VCFRONT_pumpPowertrainOutputDuty 127 "SNA" ;
VAL_ 1793 VCFRONT_radiatorFanOutputDuty 127 "SNA" ;
VAL_ 1793 VCFRONT_pumpBatteryOutputDuty 127 "SNA" ;
VAL_ 1793 VCFRONT_debugThermal10HzIndex 2 "coolant" 3 "radiatorFan" 4 "refrigerant" 5 "END" 1 "coolantPumpPowertrain" 0 "coolantPumpBattery" ;
VAL_ 1863 DBG_DI_vdcDebugEnable 0 "DBG_DI_VDC_DEBUG_DISABLED" 1 "DBG_DI_VDC_DEBUG_ENABLED" ;
VAL_ 808 EPBR_csmState 8 "CSM_WAIT_FOR_ENDSTOP" 9 "CSM_RELEASE_COMPLETE" 12 "CSM_FAULT" 5 "CSM_APPLY_COMPLETE" 7 "CSM_RELEASE_NOLOAD" 14 "CSM_HOLD_CLAMP" 4 "CSM_WAIT_FOR_CLAMP" 6 "CSM_RELEASE_INRUSH" 13 "CSM_STATIONARY_FAULT" 2 "CSM_APPLY_INRUSH" 10 "CSM_CALIBRATE" 1 "CSM_STANDBY" 0 "CSM_INIT" 11 "CSM_HALT" 3 "CSM_APPLY_NOLOAD" ;
VAL_ 808 EPBR_esmStateRequest 11 "ESM_PARK_PENDING" 1 "ESM_PARK" 3 "ESM_OPEN" 5 "ESM_SUMMON" 0 "ESM_INIT" 6 "ESM_WINCHMODE" 13 "ESM_SUMMON_PARK" 18 "ESM_DYNAMIC_EXTERNAL_EXIT" 19 "ESM_UNKNOWN" 12 "ESM_WINCHMODE_PENDING" 8 "ESM_DIAGNOSTIC_PARK" 16 "ESM_LATCHED_DYNAMIC_EXTERNAL" 2 "ESM_REAPPLY" 9 "ESM_DIAGNOSTIC_OPEN" 14 "ESM_DYNAMIC_EXTERNAL" 10 "ESM_DYNAMIC_PARK" 17 "ESM_SERVICE_PENDING" 15 "ESM_DYNAMIC_PENDING" 7 "ESM_SERVICE" 4 "ESM_DYNAMIC" ;
VAL_ 808 EPBR_esmState 11 "ESM_PARK_PENDING" 1 "ESM_PARK" 3 "ESM_OPEN" 5 "ESM_SUMMON" 0 "ESM_INIT" 6 "ESM_WINCHMODE" 13 "ESM_SUMMON_PARK" 18 "ESM_DYNAMIC_EXTERNAL_EXIT" 19 "ESM_UNKNOWN" 12 "ESM_WINCHMODE_PENDING" 8 "ESM_DIAGNOSTIC_PARK" 16 "ESM_LATCHED_DYNAMIC_EXTERNAL" 2 "ESM_REAPPLY" 9 "ESM_DIAGNOSTIC_OPEN" 14 "ESM_DYNAMIC_EXTERNAL" 10 "ESM_DYNAMIC_PARK" 17 "ESM_SERVICE_PENDING" 15 "ESM_DYNAMIC_PENDING" 7 "ESM_SERVICE" 4 "ESM_DYNAMIC" ;
VAL_ 1017 VCSEC_matrixIndex 2 "VCSEC_AlertMatrix2" 3 "VCSEC_AlertMatrix3" 0 "VCSEC_AlertMatrix0" 1 "VCSEC_AlertMatrix1" ;
VAL_ 1059 VCRIGHT_nmWakeUpReason 6 "VCRIGHT_WAKEUP_REASON_EXTERIOR_HANDLE" 1 "VCRIGHT_WAKEUP_REASON_ECU_SPECIFIC" 9 "VCRIGHT_WAKEUP_REASON_TRUNK_LATCH" 4 "VCRIGHT_WAKEUP_REASON_DOOR_LATCH" 0 "VCRIGHT_WAKEUP_REASON_NONE" 7 "VCRIGHT_WAKEUP_REASON_LIN_RX" 2 "VCRIGHT_WAKEUP_REASON_SWITCH_INPUT" 8 "VCRIGHT_WAKEUP_REASON_TRUNK_SWITCH" 15 "VCRIGHT_WAKEUP_REASON_UNKNOWN" 5 "VCRIGHT_WAKEUP_REASON_INTERIOR_HANDLE" 3 "VCRIGHT_WAKEUP_REASON_RESET" ;
VAL_ 1059 VCRIGHT_nmKeepAwakeReason 8 "VCRIGHT_KEEPAWAKE_REASON_SEAT" 10 "VCRIGHT_KEEPAWAKE_REASON_UDS_ACTIVE" 7 "VCRIGHT_KEEPAWAKE_REASON_HANDLE_PULLED" 4 "VCRIGHT_KEEPAWAKE_REASON_HVAC_PRECONDITIONING" 1 "VCRIGHT_KEEPAWAKE_REASON_EPB_STATE_NOT_SAVED" 15 "VCRIGHT_KEEPAWAKE_REASON_MULTIPLE" 3 "VCRIGHT_KEEPAWAKE_REASON_HVAC_CABIN_PURGE" 0 "VCRIGHT_KEEPAWAKE_REASON_NONE_SNA" 5 "VCRIGHT_KEEPAWAKE_REASON_CLOSURE_LATCH" 14 "VCRIGHT_KEEPAWAKE_REASON_OTHER" 6 "VCRIGHT_KEEPAWAKE_REASON_EPB_SUMMON_ACTIVE" 9 "VCRIGHT_KEEPAWAKE_REASON_TRUNK_LIGHT" 2 "VCRIGHT_KEEPAWAKE_REASON_EPB_NOT_SECURE" ;
VAL_ 1825 VCFRONT_fanRadStatMode 0 "LV8907_SLEEP" 2 "LV8907_STANDBY" 3 "LV8907_NORMAL" 1 "LV8907_STARTUP" ;
VAL_ 1825 VCFRONT_pumpPtStatMode 0 "LV8907_SLEEP" 2 "LV8907_STANDBY" 3 "LV8907_NORMAL" 1 "LV8907_STARTUP" ;
VAL_ 1825 VCFRONT_pumpBatStatMode 0 "LV8907_SLEEP" 2 "LV8907_STANDBY" 3 "LV8907_NORMAL" 1 "LV8907_STARTUP" ;
VAL_ 1825 VCFRONT_condenserActivePID 1 "TEMP" 0 "PRESSURE" ;
VAL_ 1825 VCFRONT_modeDesiredPrevious 0 "SERIES" 1 "PARALLEL" ;
VAL_ 1825 VCFRONT_debugThermal1HzIndex 4 "brushlessMotorErrors" 5 "refrigerantCondenserManager" 2 "coolantModeManager" 3 "coolantPassiveManager" 6 "END" 1 "activeLouver" 0 "coolantActiveManager" ;
VAL_ 1300 FC_serialDataSelect 2 "Mux2" 0 "Mux0" 1 "Mux1" ;
VAL_ 1864 EPBR_CPULoad1000msTask 255 "SNA" ;
VAL_ 1864 EPBR_CPULoad100msTask 255 "SNA" ;
VAL_ 1864 EPBR_CPULoad10msTask 255 "SNA" ;
VAL_ 1864 EPBR_CPULoad1msTask 255 "SNA" ;
VAL_ 1864 EPBR_CPULoadTotal 255 "SNA" ;
VAL_ 1821 DBG_cpLatch2MotorDirection 0 "DBG_CP_LATCH_MOTOR_ENGAGED" 1 "DBG_CP_LATCH_MOTOR_DISENGAGED" ;
VAL_ 1821 DBG_cpLatchMotorDirection 0 "DBG_CP_LATCH_MOTOR_ENGAGED" 1 "DBG_CP_LATCH_MOTOR_DISENGAGED" ;
VAL_ 1821 DBG_cpDoorMotorDirection 0 "DBG_CP_DOOR_MOTOR_CLOSED" 1 "DBG_CP_DOOR_MOTOR_OPEN" ;
VAL_ 1821 DBG_CP_debugControls_dataSelect 3 "CP_debug_dataSelect3" 0 "CP_debug_dataSelect0" 1 "CP_debug_dataSelect1" 4 "CP_debug_dataSelect4" ;
VAL_ 519 PTC_tliSource 4 "HV_OVER_VOLTAGE" 1 "IGBT_DRIVER" 3 "OCP" 0 "NO_ERROR" 2 "12_VOLTS" ;
VAL_ 519 PTC_ocpEvent 2 "OCP_EVENT_RIGHT_SIDE" 1 "OCP_EVENT_LEFT_SIDE" 0 "NO_OCP_EVENT" ;
VAL_ 519 PTC_rightPowerDerating 1 "OVERTEMPERATURE_PCB" 2 "OVERTEMPERATURE_IGBT" 0 "NOT_DERATED" 3 "OVERTEMPERATURE_CORE" ;
VAL_ 519 PTC_leftPowerDerating 1 "OVERTEMPERATURE_PCB" 2 "OVERTEMPERATURE_IGBT" 0 "NOT_DERATED" 3 "OVERTEMPERATURE_CORE" ;
VAL_ 769 VCFRONT_infoAssemblyId 1 "ASSEMBLY1" 255 "ASSEMBLY_SNA" ;
VAL_ 769 VCFRONT_infoBuildType 1 "INFO_PLATFORM_BUILD" 3 "INFO_TRACEABLE_CI_BUILD" 4 "INFO_MFG_BUILD" 2 "INFO_LOCAL_BUILD" 0 "INFO_UNKNOWN_BUILD" ;
VAL_ 769 VCFRONT_infoIndex 14 "BC_INFO_BOOTLOADER_SVN" 6 "BC_INFO_DEPRECATED_6" 20 "BC_INFO_UDS_PROTOCOL_BOOTCRC" 24 "BC_INFO_SUBCOMPONENT3" 1 "BC_INFO_DEPRECATED_1" 31 "BC_INFO_SUBCOMPONENT4" 19 "BC_INFO_VERSION_DEPRECATED" 10 "BC_INFO_BUILD_HWID_COMPONENTID" 0 "BC_INFO_DEPRECATED_0" 5 "BC_INFO_DEPRECATED_5" 11 "BC_INFO_PCBAID_ASSYID_USAGEID" 18 "BC_INFO_BOOTLOADER_GITHASH" 3 "BC_INFO_DEPRECATED_3" 15 "BC_INFO_BOOTLOADER_CRC" 4 "BC_INFO_DEPRECATED_4" 16 "BC_INFO_SUBCOMPONENT1" 255 "BC_INFO_END" 9 "BC_INFO_DEPRECATED_9" 13 "BC_INFO_APP_CRC" 2 "BC_INFO_DEPRECATED_2" 23 "BC_INFO_SUBCOMPONENT2" 7 "BC_INFO_DEPRECATED_7" 8 "BC_INFO_DEPRECATED_8" 17 "BC_INFO_APP_GITHASH" ;
VAL_ 599 DI_uiSpeedUnits 0 "DI_SPEED_MPH" 1 "DI_SPEED_KPH" ;
VAL_ 599 DI_uiSpeed 255 "DI_UI_SPEED_SNA" ;
VAL_ 599 DI_vehicleSpeed 4095 "SNA" ;
VAL_ 797 CC_buttonState 1 "CC_BUTTON_PRESSED" 0 "CC_BUTTON_RELEASED" ;
VAL_ 797 CC_chgStatus2Index 0 "Mux0" ;
VAL_ 1301 VCFRONT_alertClearedID 347 "VCFRONT_a347_iboosterFastTripSlope" 116 "VCFRONT_a116_VCRIGHT_MIA" 60 "VCFRONT_a060_engineeringBuild" 104 "VCFRONT_a104_DAS_MIA" 336 "VCFRONT_a336_pcsFastTripOCMax" 150 "VCFRONT_a150_pumpBatLowRPMCBang" 168 "VCFRONT_a168_hcmShortToVBAT" 213 "VCFRONT_a213_12VOvercharge" 204 "VCFRONT_a204_epas3sSelfTestFail" 341 "VCFRONT_a341_vbatFusedFastTripOCMax" 148 "VCFRONT_a148_thmlFanSoftStall" 215 "VCFRONT_a215_airCompDriverFault" 174 "VCFRONT_a174_driveNotAuthed" 98 "VCFRONT_a098_DI_THERMAL_MIA" 230 "VCFRONT_a230_thmlFanFbkSanity" 313 "VCFRONT_a313_epas3pOvertempSlope" 325 "VCFRONT_a325_vbatFusedOvertempMax" 158 "VCFRONT_a158_louverDisconnected" 97 "VCFRONT_a097_CMP_MIA" 206 "VCFRONT_a206_espSelfTestFail" 209 "VCFRONT_a209_brakeFluidSNA" 318 "VCFRONT_a318_vcleftOvertempMax" 166 "VCFRONT_a166_rightHCMMIA" 269 "VCFRONT_a269_partialLoadShed" 44 "VCFRONT_a044_Task10msError" 321 "VCFRONT_a321_epas3pOvertempMax" 253 "VCFRONT_a253_maxChrgeSssionTmeout" 194 "VCFRONT_a194_iBoosterRetry" 115 "VCFRONT_a115_VCSEC_MIA" 22 "VCFRONT_a022_TaskInitError" 156 "VCFRONT_a156_louverBlockage" 243 "VCFRONT_a243_12VOverchargeInstc" 220 "VCFRONT_a220_reverseBatteryFault" 0 "VCFRONT_ALERT_DO_NOT_USE_ZERO" 323 "VCFRONT_a323_iboosterOvertempMax" 180 "VCFRONT_a180_12VNotSupported" 140 "VCFRONT_a140_coolantTempPtSns" 327 "VCFRONT_a327_vcrightSlowTripOC" 137 "VCFRONT_a137_refrigDischPresSns" 312 "VCFRONT_a312_pcsOvertempSlope" 207 "VCFRONT_a207_vbatFusdSelfTestFail" 231 "VCFRONT_a231_12VTempSensShort" 226 "VCFRONT_a226_railAPoweredForFrunk" 259 "VCFRONT_a259_12vVoltageDropOnHighLoadCurrent" 185 "VCFRONT_a185_washerFluidLow" 105 "VCFRONT_a105_TAS_MIA" 223 "VCFRONT_a223_12VTempSensDiscnect" 249 "VCFRONT_a249_fiveWayValveBadMode" 247 "VCFRONT_a247_evapSolenoidFault" 332 "VCFRONT_a332_espSlowTripOC" 172 "VCFRONT_a172_wsteHtBlckdByMsmtch" 167 "VCFRONT_a167_leftHCMMIA" 233 "VCFRONT_a233_autopilot1EFuseFault" 186 "VCFRONT_a186_noDriveChgCableCon" 149 "VCFRONT_a149_BLEFrontPowerCycled" 324 "VCFRONT_a324_espOvertempMax" 3 "VCFRONT_a003_SWAssertion" 261 "VCFRONT_a261_vcleftVoltageMismatch" 63 "VCFRONT_a063_SwitchFault" 43 "VCFRONT_a043_Task1msError" 339 "VCFRONT_a339_iboosterFastTripOCMax" 199 "VCFRONT_a199_PRVCANUndertrminate" 203 "VCFRONT_a203_epas3pSelfTestFail" 334 "VCFRONT_a334_vcleftFastTripOCMax" 189 "VCFRONT_a189_IBSMIA" 214 "VCFRONT_a214_airCompUnderCurrent" 195 "VCFRONT_a195_drveBlckdVltgeTooHgh" 254 "VCFRONT_a254_pumpBatStopped" 142 "VCFRONT_a142_exvMotorFault" 326 "VCFRONT_a326_vcleftSlowTripOC" 136 "VCFRONT_a136_refrigDischTempSns" 110 "VCFRONT_a110_GTW_MIA" 258 "VCFRONT_a258_resistanceEstimationRun" 118 "VCFRONT_a118_VCFRONT_MIA" 109 "VCFRONT_a109_RCM_MIA" 134 "VCFRONT_a134_fusedHighEFuseTrip" 145 "VCFRONT_a145_thmlFanICTransFault" 331 "VCFRONT_a331_iboosterSlowTripOC" 314 "VCFRONT_a314_epas3sOvertempSlope" 122 "VCFRONT_a122_pumpBatICWarning" 201 "VCFRONT_a201_vcrightSelfTestFail" 173 "VCFRONT_a173_HVBlckdByMsmtch" 340 "VCFRONT_a340_espFastTripOCMax" 147 "VCFRONT_a147_pumpPtSoftStall" 193 "VCFRONT_a193_mcuAudioRetry" 187 "VCFRONT_a187_busesNotSleeping" 171 "VCFRONT_a171_driveBlckdByMsmtch" 248 "VCFRONT_a248_voltageOutOfSpec" 143 "VCFRONT_a143_pumpBatICTransFault" 222 "VCFRONT_a222_rightTurnLightFault" 124 "VCFRONT_a124_pumpPtICWarning" 100 "VCFRONT_a100_CANbus_MIA" 236 "VCFRONT_a236_batTempSnsIrrational" 221 "VCFRONT_a221_leftTurnLightFault" 235 "VCFRONT_a235_ptTempSnsIrrational" 348 "VCFRONT_a348_espFastTripSlope" 131 "VCFRONT_a131_epas3sEFuseTrip" 161 "VCFRONT_a161_compressorSelfFault" 257 "VCFRONT_a257_portExpanderVOR" 219 "VCFRONT_a219_12VVoltFloorRchd" 343 "VCFRONT_a343_vcrightFastTripSlope" 315 "VCFRONT_a315_iboosterOvertempSlope" 31 "VCFRONT_a031_UDSActive" 159 "VCFRONT_a159_fiveWayValveFault" 337 "VCFRONT_a337_epas3pFastTripOCMax" 345 "VCFRONT_a345_epas3pFastTripSlope" 64 "VCFRONT_a064_busSleepReqTimeout" 302 "VCFRONT_a302_wiperCommError" 237 "VCFRONT_a237_pumpBatChipComms" 225 "VCFRONT_a225_driveBlckdByShowroom" 234 "VCFRONT_a234_autopilot2EFuseFault" 205 "VCFRONT_a205_iBoosterSelfTestFail" 138 "VCFRONT_a138_refrigSuctTempSns" 256 "VCFRONT_a256_compTornShaftSeal" 301 "VCFRONT_a301_wipersFactoryDisabled" 344 "VCFRONT_a344_pcsFastTripSlope" 135 "VCFRONT_a135_coolantLevelLow" 263 "VCFRONT_a263_pcsVoltageMismatch" 1 "VCFRONT_a001_WatchdogReset" 342 "VCFRONT_a342_vcleftFastTripSlope" 311 "VCFRONT_a311_vcrightOvertempSlope" 239 "VCFRONT_a239_thmlFanChipComms" 265 "VCFRONT_a265_ESPVoltageMismatch" 130 "VCFRONT_a130_epas3pEFuseTrip" 126 "VCFRONT_a126_thmlFanICWarning" 175 "VCFRONT_a175_ambientTempSns" 21 "VCFRONT_a021_TaskSchedulerError" 128 "VCFRONT_a128_vcrightEFuseTrip" 267 "VCFRONT_a267_EPAS3sVoltageMismatch" 10 "VCFRONT_a010_ExtSupplyVoltError" 99 "VCFRONT_a099_PARK_MIA" 322 "VCFRONT_a322_epas3sOvertempMax" 170 "VCFRONT_a170_hcmUnderVoltage" 15 "VCFRONT_a015_NVMMAlert" 229 "VCFRONT_a229_pumpPtFbkSanity" 268 "VCFRONT_a268_vbatFusedVoltageMismatch" 317 "VCFRONT_a317_vbatFusedOvertempSlope" 182 "VCFRONT_a182_replace12VBattery" 335 "VCFRONT_a335_vcrightFastTripOCMax" 198 "VCFRONT_a198_PRVCANOverterminate" 121 "VCFRONT_a121_pumpBatICLatchFault" 144 "VCFRONT_a144_pumpPtICTransFault" 320 "VCFRONT_a320_pcsOvertempMax" 251 "VCFRONT_a251_UIWakeupTrigger" 120 "VCFRONT_a120_DI_DRIVE_MIA" 101 "VCFRONT_a101_PM_MIA" 333 "VCFRONT_a333_vbatFusedSlowTripOC" 183 "VCFRONT_a183_low12VCapacity" 59 "VCFRONT_a059_inputResistanceHigh" 255 "VCFRONT_a255_pumpPtStopped" 245 "VCFRONT_a245_pump1EFuseFault" 329 "VCFRONT_a329_epas3pSlowTripOC" 228 "VCFRONT_a228_pumpBatFbkSanity" 211 "VCFRONT_a211_I2CFault" 157 "VCFRONT_a157_louverBreakage" 202 "VCFRONT_a202_pcsSelfTestFail" 114 "VCFRONT_a114_ESP_MIA" 165 "VCFRONT_a165_unxpctdEFuseLckout" 319 "VCFRONT_a319_vcrightOvertempMax" 246 "VCFRONT_a246_pump2EFuseFault" 133 "VCFRONT_a133_espEFuseTrip" 12 "VCFRONT_a012_CPUReset" 152 "VCFRONT_a152_thmlFanLowRPMCBang" 238 "VCFRONT_a238_pumpPtChipComms" 46 "VCFRONT_a046_Task1000msError" 266 "VCFRONT_a266_EPAS3pVoltageMismatch" 107 "VCFRONT_a107_BMS_MIA" 125 "VCFRONT_a125_thmlFanICLatchFault" 260 "VCFRONT_a260_dead12VBattery" 179 "VCFRONT_a179_highLVAmpsIntoPCS" 338 "VCFRONT_a338_epas3sFastTripOCMax" 262 "VCFRONT_a262_vcrightVoltageMismatch" 164 "VCFRONT_a164_eFuseLckoutMissing" 188 "VCFRONT_a188_sleepFailed" 264 "VCFRONT_a264_iBoosterVoltageMismatch" 192 "VCFRONT_a192_criticalLoadShed" 106 "VCFRONT_a106_PCS_MIA" 108 "VCFRONT_a108_DIS_MIA" 210 "VCFRONT_a210_fiveWayValveCalib" 62 "VCFRONT_a062_XCPWasConnected" 328 "VCFRONT_a328_pcsSlowTripOC" 113 "VCFRONT_a113_UI_MIA" 176 "VCFRONT_a176_vehicleInSelfTest" 316 "VCFRONT_a316_espOvertempSlope" 139 "VCFRONT_a139_refrigSuctPresSns" 250 "VCFRONT_a250_headlampsNotAimed" 127 "VCFRONT_a127_vcleftEFuseTrip" 13 "VCFRONT_a013_AlertManagerFault" 244 "VCFRONT_a244_sleepBypassFault" 119 "VCFRONT_a119_SCCM_MIA" 252 "VCFRONT_a252_frontControllerWakeup" 141 "VCFRONT_a141_coolantTempBatSns" 129 "VCFRONT_a129_pcsEFuseTrip" 123 "VCFRONT_a123_pumpPtICLatchFault" 102 "VCFRONT_a102_PTC_MIA" 196 "VCFRONT_a196_discnctd12VBattery" 111 "VCFRONT_a111_EPBR_MIA" 30 "VCFRONT_a030_ECULogUploadRequest" 177 "VCFRONT_a177_mcuAudioEFuseFault" 151 "VCFRONT_a151_pumpPtLowRPMCBang" 61 "VCFRONT_a061_XCPConnected" 112 "VCFRONT_a112_EPBL_MIA" 45 "VCFRONT_a045_Task100msError" 42 "VCFRONT_a042_HighStackUsage" 208 "VCFRONT_a208_brakeFluidLow" 117 "VCFRONT_a117_VCLEFT_MIA" 330 "VCFRONT_a330_epas3sSlowTripOC" 2 "VCFRONT_a002_PowerLossReset" 41 "VCFRONT_a041_HighCPULoad" 103 "VCFRONT_a103_CP_MIA" 310 "VCFRONT_a310_vcleftOvertempSlope" 212 "VCFRONT_a212_IBSOverTemp" 224 "VCFRONT_a224_revBatChrgPmpFault" 283 "VCFRONT_a283_thmlFanLimitedByCurrent" 200 "VCFRONT_a200_vcleftSelfTestFail" 346 "VCFRONT_a346_epas3sFastTripSlope" 191 "VCFRONT_a191_exitDriveLow12V" 160 "VCFRONT_a160_compressorInhibited" 349 "VCFRONT_a349_vbatFusedFastTripSlope" 169 "VCFRONT_a169_hcmPhaseEnableFail" 146 "VCFRONT_a146_pumpBatSoftStall" 132 "VCFRONT_a132_iBoosterEFuseTrip" ;
VAL_ 614 DI_elecPower -1024 "SNA" ;
VAL_ 17 RCM_collisionSeverity 1 "RCM_COLLISION_SEVERITY_FIRST_STAGE" 0 "RCM_COLLISION_SEVERITY_PRETENSIONER" 2 "RCM_COLLISION_SEVERITY_SECOND_STAGE" 3 "RCM_COLLISION_SEVERITY_PEDPRO_EVENT" ;
VAL_ 17 RCM_collisionRollover 0 "RCM_COLLISION_EVENT_INACTIVE" 3 "RCM_COLLISION_EVENT_SNA" 1 "RCM_COLLISION_EVENT_ACTIVE" ;
VAL_ 17 RCM_collisionFront 0 "RCM_COLLISION_EVENT_INACTIVE" 3 "RCM_COLLISION_EVENT_SNA" 1 "RCM_COLLISION_EVENT_ACTIVE" ;
VAL_ 17 RCM_collisionLeft 0 "RCM_COLLISION_EVENT_INACTIVE" 3 "RCM_COLLISION_EVENT_SNA" 1 "RCM_COLLISION_EVENT_ACTIVE" ;
VAL_ 17 RCM_collisionRight 0 "RCM_COLLISION_EVENT_INACTIVE" 3 "RCM_COLLISION_EVENT_SNA" 1 "RCM_COLLISION_EVENT_ACTIVE" ;
VAL_ 17 RCM_collisionRear 0 "RCM_COLLISION_EVENT_INACTIVE" 3 "RCM_COLLISION_EVENT_SNA" 1 "RCM_COLLISION_EVENT_ACTIVE" ;
VAL_ 1116 CC_alertType 0 "ALERT_CLEARED" 1 "ALERT_SET" ;
VAL_ 1116 CC_alertID 7 "CC_a007_inputOverVoltage" 14 "CC_a014_mcuSelfTestFault" 13 "CC_a013_vehConnOT" 22 "CC_a022_CB_tooManyMasters" 27 "CC_a027_vehicleHandleTemp" 11 "CC_a011_ambientOT" 8 "CC_a008_inputUnderVoltage" 19 "CC_a019_proxDisconnected" 18 "CC_a018_PilotDFault" 17 "CC_a017_PilotCFault" 4 "CC_a004_CCIDSelfTestFault" 15 "CC_a015_PilotAFault" 0 "CC_ALERT_DO_NOT_USE_ZERO" 10 "CC_a010_contactorWelded" 24 "CC_a024_CB_masterISetTooLow" 21 "CC_a021_CB_noMaster" 9 "CC_a009_inputMiswired" 30 "CC_a030_masterSlaveMismatch" 23 "CC_a023_CB_tooManySlaves" 25 "CC_a025_evseTemp" 2 "CC_a002_gndMonIntrptLoadSide" 5 "CC_a005_groundedNeutral" 16 "CC_a016_PilotBFault" 29 "CC_a029_PilotFFault" 6 "CC_a006_inputOverCurrent" 28 "CC_a028_CB_rotarySelect" 26 "CC_a026_wallPlugTemp" 1 "CC_a001_gndMonIntrptLineSide" 12 "CC_a012_wallPlugOT" 20 "CC_a020_3vRailIncorrect" 3 "CC_a003_CCIDTripped" ;
VAL_ 946 BMS_negCtrDeviationFiltConfMax 8191 "SNA" ;
VAL_ 946 BMS_posCtrDeviationFiltConfMax 8191 "SNA" ;
VAL_ 946 BMS_negCtrOffsetErrorConf 8191 "SNA" ;
VAL_ 946 BMS_posCtrOffsetErrorConf 8191 "SNA" ;
VAL_ 946 BMS_negCtrDeviationConfidenceMax 8191 "SNA" ;
VAL_ 946 BMS_posCtrDeviationConfidenceMax 8191 "SNA" ;
VAL_ 946 BMS_negCtrResistanceConfidence 8191 "SNA" ;
VAL_ 946 BMS_posCtrDropCorrectedFiltMax -4096 "SNA" ;
VAL_ 946 BMS_negCtrDropCorrectedFiltMax -4096 "SNA" ;
VAL_ 946 BMS_negCtrResistance -4096 "SNA" ;
VAL_ 946 BMS_posCtrDropCorrectedFiltMin -4096 "SNA" ;
VAL_ 946 BMS_negCtrDropCorrectedFiltMin -4096 "SNA" ;
VAL_ 946 BMS_negCtrDeviationFiltConfMin 8191 "SNA" ;
VAL_ 946 BMS_posCtrDeviationFiltConfMin 8191 "SNA" ;
VAL_ 946 BMS_posCtrOffsetError -4096 "SNA" ;
VAL_ 946 BMS_posCtrDeviationConfidenceMin 8191 "SNA" ;
VAL_ 946 BMS_negCtrDeviationConfidenceMin 8191 "SNA" ;
VAL_ 946 BMS_negCtrOffsetError -4096 "SNA" ;
VAL_ 946 BMS_posCtrDropCorrectedMax -4096 "SNA" ;
VAL_ 946 BMS_negCtrDropCorrectedMax -4096 "SNA" ;
VAL_ 946 BMS_negCtrDeviationMax -4096 "SNA" ;
VAL_ 946 BMS_posCtrDeviationMax -4096 "SNA" ;
VAL_ 946 BMS_negCtrCommonModeRejErrorConf 8191 "SNA" ;
VAL_ 946 BMS_posCtrCommonModeRejErrorConf 8191 "SNA" ;
VAL_ 946 BMS_posCtrResistanceConfidence 8191 "SNA" ;
VAL_ 946 BMS_negCtrDeviationFiltMax -4096 "SNA" ;
VAL_ 946 BMS_posCtrDeviationFiltMax -4096 "SNA" ;
VAL_ 946 BMS_chgEndPcsStatus 2 "CHARGE_FAULTED" 0 "CHARGE_IDLE" 1 "CHARGE_ENABLED" ;
VAL_ 946 BMS_floodPortState2 1 "FLOOD_PORT_STATE_ERROR_LOW" 0 "FLOOD_PORT_STATE_SNA" 3 "FLOOD_PORT_STATE_OPEN" 2 "FLOOD_PORT_STATE_CLOSED" 4 "FLOOD_PORT_STATE_ERROR_HIGH" ;
VAL_ 946 BMS_chgEndChargeState 15 "CHARGE_STATE_FAULT" 2 "CHARGE_STATE_DC_EXT_ISO_CHECK" 7 "CHARGE_STATE_AC_DISABLE_PCS" 6 "CHARGE_STATE_DC_DISABLING_CHARGER" 3 "CHARGE_STATE_DC_ENABLE_FCLINK" 4 "CHARGE_STATE_AC_ENABLE_PCS" 5 "CHARGE_STATE_CHARGING_ACTIVE" 1 "CHARGE_STATE_ENABLE_DCLINK" 0 "CHARGE_STATE_INACTIVE" ;
VAL_ 946 BMS_floodPortState1 1 "FLOOD_PORT_STATE_ERROR_LOW" 0 "FLOOD_PORT_STATE_SNA" 3 "FLOOD_PORT_STATE_OPEN" 2 "FLOOD_PORT_STATE_CLOSED" 4 "FLOOD_PORT_STATE_ERROR_HIGH" ;
VAL_ 946 BMS_chargeNeededReason 2 "BMS_DCH_KWH_THRESHOLD" 6 "BMS_BRICKV_LESS_THAN_FULL_CHARGE" 1 "BMS_SOC_LESS_THAN_UI_THRESHOLD" 3 "BMS_CHARGE_TARGET_INCREASED" 4 "BMS_CABLE_CYCLE_TOP_OFF" 0 "BMS_NO_CHARGE_REASON" 5 "BMS_AUTO_TOP_OFF_COUNTER" ;
VAL_ 946 BMS_posCtrResistance -4096 "SNA" ;
VAL_ 946 BMS_posCtrCommonModeRejError -4096 "SNA" ;
VAL_ 946 BMS_negCtrCommonModeRejError -4096 "SNA" ;
VAL_ 946 BMS_posCtrDropCorrectedMin -4096 "SNA" ;
VAL_ 946 BMS_negCtrDropCorrectedMin -4096 "SNA" ;
VAL_ 946 BMS_negCtrDeviationFiltMin -4096 "SNA" ;
VAL_ 946 BMS_posCtrDeviationFiltMin -4096 "SNA" ;
VAL_ 946 BMS_chargeCurrentLimitMode 0 "BMS_CHG_I_LIMIT_NONE" 3 "BMS_CHG_I_LIMIT_LEAKY_BUCKET" 2 "BMS_CHG_I_LIMIT_CAC_IMBALANCE" 1 "BMS_CHG_I_LIMIT_BRICK_TEMP_AND_V" 4 "BMS_CHG_I_LIMIT_TETHERING" ;
VAL_ 946 BMS_negCtrDeviationMin -4096 "SNA" ;
VAL_ 946 BMS_posCtrDeviationMin -4096 "SNA" ;
VAL_ 946 BMS_chgEndEvseChargeType 1 "DC_CHARGER_PRESENT" 0 "NO_CHARGER_PRESENT" 2 "AC_CHARGER_PRESENT" ;
VAL_ 946 BMS_log2MuxId 18 "BMS_LOG2_NEG_CTR_HEALTH_4" 14 "BMS_LOG2_POS_CTR_HEALTH_4" 6 "BMS_LOG2_AHR_COUNTER" 9 "BMS_LOG2_100HZ_1KHZ_TASK_STATS" 12 "BMS_LOG2_POS_CTR_HEALTH_2" 16 "BMS_LOG2_NEG_CTR_HEALTH_2" 8 "BMS_LOG2_10HZ_TASK_STATS" 3 "BMS_LOG2_CHARGE_TERMINATION" 17 "BMS_LOG2_NEG_CTR_HEALTH_3" 13 "BMS_LOG2_POS_CTR_HEALTH_3" 4 "BMS_LOG2_VSH_TEST" 1 "BMS_LOG2_CAC2" 2 "BMS_LOG2_FLOOD_PORT" 0 "BMS_LOG2_CAC1" 5 "BMS_LOG2_CHARGING" 7 "BMS_LOG2_1HZ_TASK_STATS" 10 "BMS_LOG2_CTR_RESISTANCE" 19 "BMS_LOG2_HV_CHAIN_MODEL" 15 "BMS_LOG2_NEG_CTR_HEALTH_1" 11 "BMS_LOG2_POS_CTR_HEALTH_1" ;
